BO_ 2650776967 PB_ROC_87: 16 NODE_87
 SG_ NegRelayCounterAbove500_FFA587 : 120|8@1+ (1,0) [0|255] ""  PCM
 SG_ PosRelayCounterAbove500_FFA587 : 112|8@1+ (1,0) [0|255] ""  PCM
 SG_ NegRelayCounter400_500_FFA587 : 104|8@1+ (1,0) [0|255] ""  PCM
 SG_ PosRelayCounter400_500_FFA587 : 96|8@1+ (1,0) [0|255] ""  PCM
 SG_ NegRelayCounter250_400_FFA587 : 88|8@1+ (1,0) [0|255] ""  PCM
 SG_ PosRelayCounter250_400_FFA587 : 80|8@1+ (1,0) [0|255] ""  PCM
 SG_ NegRelayCounter50_250_FFA587 : 64|16@1+ (1,0) [0|65535] ""  PCM
 SG_ PosRelayCounter50_250_FFA587 : 48|16@1+ (1,0) [0|65535] ""  PCM
 SG_ NegRelayCounter_FFA587 : 32|16@1+ (1,0) [0|65535] ""  PCM
 SG_ PosRelayCounter_FFA587 : 16|16@1+ (1,0) [0|65535] ""  PCM
 SG_ PreRelayCounter_FFA587 : 0|16@1+ (1,0) [0|65535] ""  PCM

BO_ 2650777076 PB_ROC_F4: 16 NODE_F4
 SG_ NegRelayCounterAbove500_FFA5F4 : 120|8@1+ (1,0) [0|255] ""  PCM
 SG_ PosRelayCounterAbove500_FFA5F4 : 112|8@1+ (1,0) [0|255] ""  PCM
 SG_ NegRelayCounter400_500_FFA5F4 : 104|8@1+ (1,0) [0|255] ""  PCM
 SG_ PosRelayCounter400_500_FFA5F4 : 96|8@1+ (1,0) [0|255] ""  PCM
 SG_ NegRelayCounter250_400_FFA5F4 : 88|8@1+ (1,0) [0|255] ""  PCM
 SG_ PosRelayCounter250_400_FFA5F4 : 80|8@1+ (1,0) [0|255] ""  PCM
 SG_ NegRelayCounter50_250_FFA5F4 : 64|16@1+ (1,0) [0|65535] ""  PCM
 SG_ PosRelayCounter50_250_FFA5F4 : 48|16@1+ (1,0) [0|65535] ""  PCM
 SG_ NegRelayCounter_FFA5F4 : 32|16@1+ (1,0) [0|65535] ""  PCM
 SG_ PosRelayCounter_FFA5F4 : 16|16@1+ (1,0) [0|65535] ""  PCM
 SG_ PreRelayCounter_FFA5F4 : 0|16@1+ (1,0) [0|65535] ""  PCM

BO_ 2650777077 PB_ROC_F5: 16 NODE_F5
 SG_ NegRelayCounterAbove500_FFA5F5 : 120|8@1+ (1,0) [0|255] ""  PCM
 SG_ PosRelayCounterAbove500_FFA5F5 : 112|8@1+ (1,0) [0|255] ""  PCM
 SG_ NegRelayCounter400_500_FFA5F5 : 104|8@1+ (1,0) [0|255] ""  PCM
 SG_ PosRelayCounter400_500_FFA5F5 : 96|8@1+ (1,0) [0|255] ""  PCM
 SG_ NegRelayCounter250_400_FFA5F5 : 88|8@1+ (1,0) [0|255] ""  PCM
 SG_ PosRelayCounter250_400_FFA5F5 : 80|8@1+ (1,0) [0|255] ""  PCM
 SG_ NegRelayCounter50_250_FFA5F5 : 64|16@1+ (1,0) [0|65535] ""  PCM
 SG_ PosRelayCounter50_250_FFA5F5 : 48|16@1+ (1,0) [0|65535] ""  PCM
 SG_ NegRelayCounter_FFA5F5 : 32|16@1+ (1,0) [0|65535] ""  PCM
 SG_ PosRelayCounter_FFA5F5 : 16|16@1+ (1,0) [0|65535] ""  PCM
 SG_ PreRelayCounter_FFA5F5 : 0|16@1+ (1,0) [0|65535] ""  PCM

BO_ 2650777078 PB_ROC_F6: 16 NODE_F6
 SG_ NegRelayCounterAbove500_FFA5F6 : 120|8@1+ (1,0) [0|255] ""  PCM
 SG_ PosRelayCounterAbove500_FFA5F6 : 112|8@1+ (1,0) [0|255] ""  PCM
 SG_ NegRelayCounter400_500_FFA5F6 : 104|8@1+ (1,0) [0|255] ""  PCM
 SG_ PosRelayCounter400_500_FFA5F6 : 96|8@1+ (1,0) [0|255] ""  PCM
 SG_ NegRelayCounter250_400_FFA5F6 : 88|8@1+ (1,0) [0|255] ""  PCM
 SG_ PosRelayCounter250_400_FFA5F6 : 80|8@1+ (1,0) [0|255] ""  PCM
 SG_ NegRelayCounter50_250_FFA5F6 : 64|16@1+ (1,0) [0|65535] ""  PCM
 SG_ PosRelayCounter50_250_FFA5F6 : 48|16@1+ (1,0) [0|65535] ""  PCM
 SG_ NegRelayCounter_FFA5F6 : 32|16@1+ (1,0) [0|65535] ""  PCM
 SG_ PosRelayCounter_FFA5F6 : 16|16@1+ (1,0) [0|65535] ""  PCM
 SG_ PreRelayCounter_FFA5F6 : 0|16@1+ (1,0) [0|65535] ""  PCM

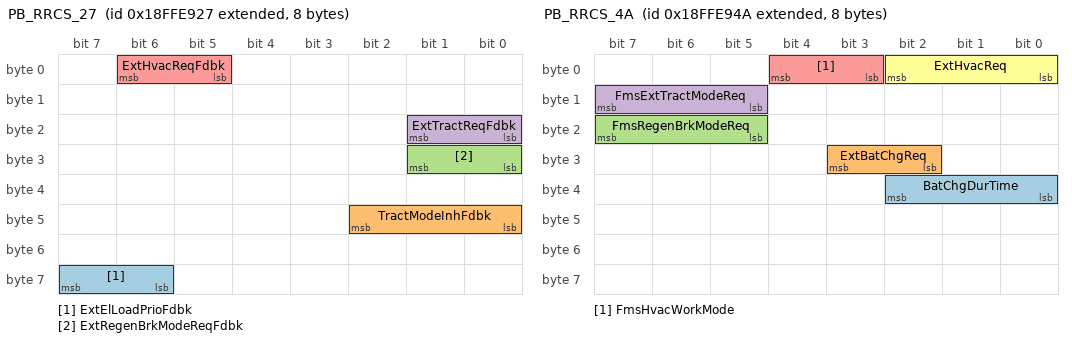
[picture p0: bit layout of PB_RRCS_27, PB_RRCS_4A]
BO_ 2566908199 PB_RRCS_27: 8 VCM
 SG_ ExtElLoadPrioFdbk : 62|2@1+ (1,0) [0|3] ""  PCM
 SG_ TractModeInhFdbk : 40|3@1+ (1,0) [0|7] ""  PCM
 SG_ ExtRegenBrkModeReqFdbk : 24|2@1+ (1,0) [0|3] ""  PCM
 SG_ ExtTractReqFdbk : 16|2@1+ (1,0) [0|3] ""  PCM
 SG_ ExtHvacReqFdbk : 5|2@1+ (1,0) [0|3] ""  PCM

BO_ 2566908234 PB_RRCS_4A: 8 PCM
 SG_ BatChgDurTime : 32|3@1+ (1,0) [0|7] "" Vector__XXX
 SG_ ExtBatChgReq : 26|2@1+ (1,0) [0|3] "" Vector__XXX
 SG_ FmsRegenBrkModeReq : 21|3@1+ (1,0) [0|7] "" Vector__XXX
 SG_ FmsExtTractModeReq : 13|3@1+ (1,0) [0|7] "" Vector__XXX
 SG_ FmsHvacWorkMode : 3|2@1+ (1,0) [0|3] "" Vector__XXX
 SG_ ExtHvacReq : 0|3@1+ (1,0) [0|7] "" Vector__XXX

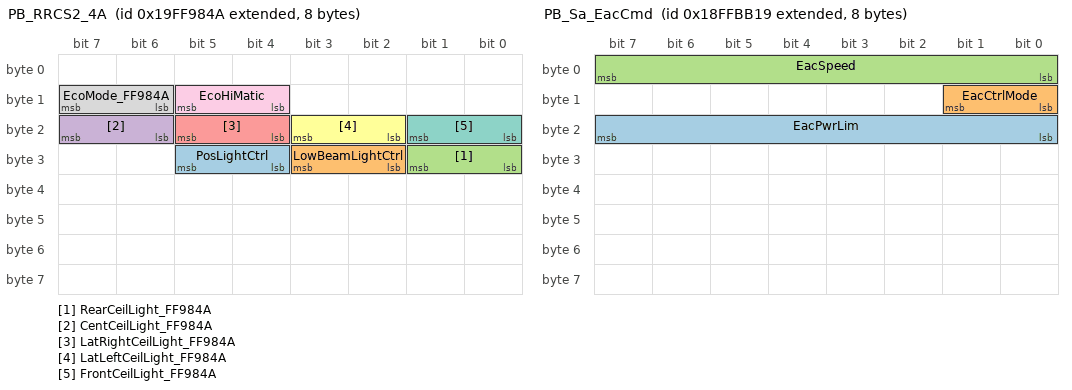
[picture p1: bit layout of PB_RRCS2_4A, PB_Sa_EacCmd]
BO_ 2583664714 PB_RRCS2_4A: 8 PCM
 SG_ PosLightCtrl : 28|2@1+ (1,0) [0|3] "" Vector__XXX
 SG_ LowBeamLightCtrl : 26|2@1+ (1,0) [0|3] "" Vector__XXX
 SG_ RearCeilLight_FF984A : 24|2@1+ (1,0) [0|3] "" Vector__XXX
 SG_ CentCeilLight_FF984A : 22|2@1+ (1,0) [0|3] "" Vector__XXX
 SG_ LatRightCeilLight_FF984A : 20|2@1+ (1,0) [0|3] "" Vector__XXX
 SG_ LatLeftCeilLight_FF984A : 18|2@1+ (1,0) [0|3] "" Vector__XXX
 SG_ FrontCeilLight_FF984A : 16|2@1+ (1,0) [0|3] "" Vector__XXX
 SG_ EcoMode_FF984A : 14|2@1+ (1,0) [0|3] "" Vector__XXX
 SG_ EcoHiMatic : 12|2@1+ (1,0) [0|3] "" Vector__XXX

BO_ 2566896409 PB_Sa_EacCmd: 8 ACM
 SG_ EacPwrLim : 16|8@1+ (0.04,0) [0|10] "kW"  PCM
 SG_ EacCtrlMode : 8|2@1+ (1,0) [0|3] ""  PCM
 SG_ EacSpeed : 0|8@1+ (50,0) [0|9000] "rpm"  PCM

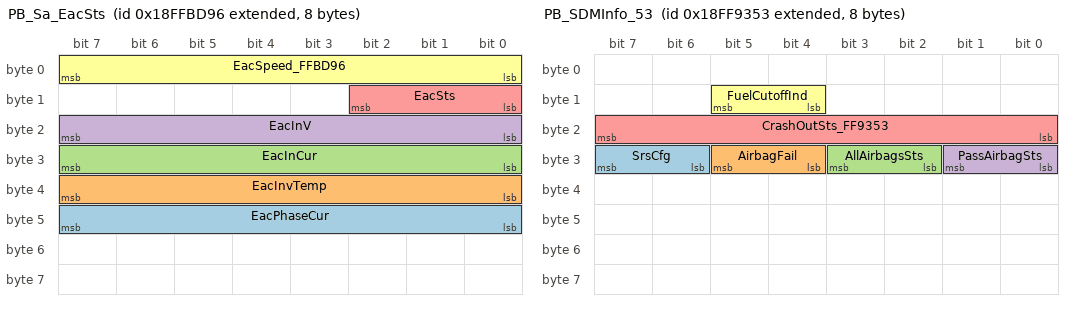
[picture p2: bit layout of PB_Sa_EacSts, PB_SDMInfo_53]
BO_ 2566897046 PB_Sa_EacSts: 8 NODE_96
 SG_ EacPhaseCur : 40|8@1+ (0.5,0) [0|125] "A"  PCM
 SG_ EacInvTemp : 32|8@1+ (1,-50) [-50|200] "�C"  PCM
 SG_ EacInCur : 24|8@1+ (0.5,0) [0|125] "A"  PCM
 SG_ EacInV : 16|8@1+ (3,0) [0|750] "V"  PCM
 SG_ EacSts : 8|3@1+ (1,0) [0|7] ""  PCM
 SG_ EacSpeed_FFBD96 : 0|8@1+ (50,0) [0|9000] "rpm"  PCM

BO_ 2566886218 PB_SDMInfo_4A: 8 PCM
 SG_ EcallSts : 32|3@1+ (1,0) [0|15] "" Vector__XXX

BO_ 2566886227 PB_SDMInfo_53: 8 Airbag
 SG_ SrsCfg : 30|2@1+ (1,0) [0|3] ""  PCM
 SG_ AirbagFail : 28|2@1+ (1,0) [0|3] ""  PCM
 SG_ AllAirbagsSts : 26|2@1+ (1,0) [0|3] ""  PCM
 SG_ PassAirbagSts : 24|2@1+ (1,0) [0|3] ""  PCM
 SG_ CrashOutSts_FF9353 : 16|8@1+ (1,0) [0|255] ""  PCM
 SG_ FuelCutoffInd : 12|2@1+ (1,0) [0|3] ""  PCM

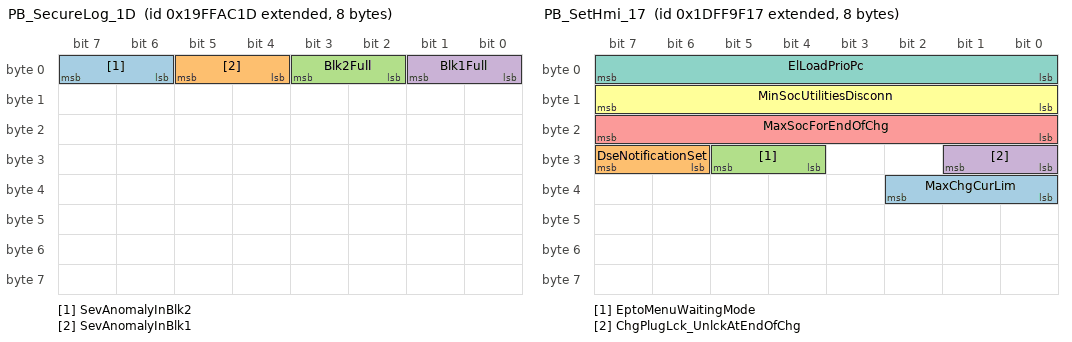
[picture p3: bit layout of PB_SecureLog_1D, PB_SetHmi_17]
BO_ 2583669789 PB_SecureLog_1D: 8 SGW
 SG_ SevAnomalyInBlk2 : 6|2@1+ (1,0) [0|3] ""  PCM
 SG_ SevAnomalyInBlk1 : 4|2@1+ (1,0) [0|3] ""  PCM
 SG_ Blk2Full : 2|2@1+ (1,0) [0|3] ""  PCM
 SG_ Blk1Full : 0|2@1+ (1,0) [0|3] ""  PCM

BO_ 2583669834 PB_SecureLog_4A: 8 PCM
 SG_ WarnRx : 8|2@1+ (1,0) [0|3] "" Vector__XXX

BO_ 2650775319 PB_SetHmi_17: 8 ICC
 SG_ MaxChgCurLim : 32|3@1+ (1,0) [0|7] ""  PCM
 SG_ DseNotificationSet : 30|2@1+ (1,0) [0|3] ""  PCM
 SG_ EptoMenuWaitingMode : 28|2@1+ (1,0) [0|3] ""  PCM
 SG_ ChgPlugLck_UnlckAtEndOfChg : 24|2@1+ (1,0) [0|3] ""  PCM
 SG_ MaxSocForEndOfChg : 16|8@1+ (0.4,0) [0|100] "%"  PCM
 SG_ MinSocUtilitiesDisconn : 8|8@1+ (0.4,0) [0|100] "%"  PCM
 SG_ ElLoadPrioPc : 0|8@1+ (0.5,0) [0|125] "%"  PCM

BO_ 2650775335 PB_SetHmi_27: 8 VCM
 SG_ ElLoadPrioPc_FF9F27 : 0|8@1+ (0.5,0) [0|125] "%"  PCM

BO_ 2650775370 PB_SetHmi_4A: 8 PCM
 SG_ ZZS_24_1DFF9F4A : 24|2@1+ (1,0) [0|3] "" Vector__XXX
 SG_ ElLoadPrioPc_FF9F4A : 0|8@1+ (0.5,0) [0|125] "%" Vector__XXX

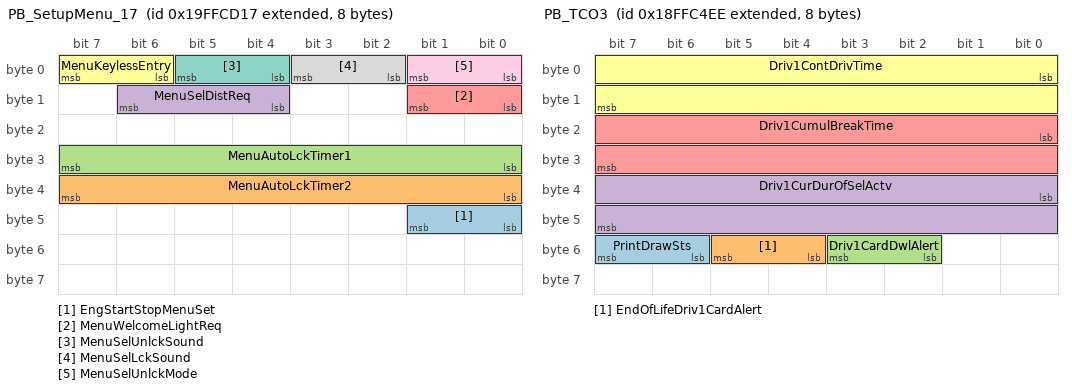
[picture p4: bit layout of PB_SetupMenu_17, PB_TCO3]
BO_ 2583678231 PB_SetupMenu_17: 8 ICC
 SG_ EngStartStopMenuSet : 40|2@1+ (1,0) [0|3] ""  PCM
 SG_ MenuAutoLckTimer2 : 32|8@1+ (1,0) [0|250] "s"  PCM
 SG_ MenuAutoLckTimer1 : 24|8@1+ (1,0) [0|250] "s"  PCM
 SG_ MenuSelDistReq : 12|3@1+ (1,0) [0|7] ""  PCM
 SG_ MenuWelcomeLightReq : 8|2@1+ (1,0) [0|3] ""  PCM
 SG_ MenuKeylessEntry : 6|2@1+ (1,0) [0|3] ""  PCM
 SG_ MenuSelUnlckSound : 4|2@1+ (1,0) [0|3] ""  PCM
 SG_ MenuSelLckSound : 2|2@1+ (1,0) [0|3] ""  PCM
 SG_ MenuSelUnlckMode : 0|2@1+ (1,0) [0|3] ""  PCM

BO_ 2583678241 PB_SetupMenu_21: 8 BCM
 SG_ IgnShutdnTimer : 16|8@1+ (1,0) [0|250] "min"  PCM

BO_ 2650777734 PB_STC_86: 24 NODE_86
 SG_ MaxIntervalViolation : 176|16@1+ (1,0) [0|65535] ""  PCM
 SG_ StgBelowNeg30_h : 160|16@1+ (1,0) [0|65535] "h"  PCM
 SG_ StgBelowNeg20_h : 144|16@1+ (1,0) [0|65535] "h"  PCM
 SG_ StgBelowNeg10_h : 128|16@1+ (1,0) [0|65535] "h"  PCM
 SG_ StgBelow0_h : 112|16@1+ (1,0) [0|65535] "h"  PCM
 SG_ StgOver0_h : 96|16@1+ (1,0) [0|65535] "h"  PCM
 SG_ StgOver15_h : 80|16@1+ (1,0) [0|65535] "h"  PCM
 SG_ StgOver30_h : 64|16@1+ (1,0) [0|65535] "h"  PCM
 SG_ StgOver35_h : 48|16@1+ (1,0) [0|65535] "h"  PCM
 SG_ StgOver40_h : 32|16@1+ (1,0) [0|65535] "h"  PCM
 SG_ StgOver45_h : 16|16@1+ (1,0) [0|65535] "h"  PCM
 SG_ StgOver55_h : 0|16@1+ (1,0) [0|65535] "h"  PCM

BO_ 2650777735 PB_STC_87: 24 NODE_87
 SG_ MaxIntervalViolation_FFA887 : 176|16@1+ (1,0) [0|65535] ""  PCM
 SG_ StgBelowNeg30_h_FFA887 : 160|16@1+ (1,0) [0|65535] "h"  PCM
 SG_ StgBelowNeg20_h_FFA887 : 144|16@1+ (1,0) [0|65535] "h"  PCM
 SG_ StgBelowNeg10_h_FFA887 : 128|16@1+ (1,0) [0|65535] "h"  PCM
 SG_ StgBelow0_h_FFA887 : 112|16@1+ (1,0) [0|65535] "h"  PCM
 SG_ StgOver0_h_FFA887 : 96|16@1+ (1,0) [0|65535] "h"  PCM
 SG_ StgOver15_h_FFA887 : 80|16@1+ (1,0) [0|65535] "h"  PCM
 SG_ StgOver30_h_FFA887 : 64|16@1+ (1,0) [0|65535] "h"  PCM
 SG_ StgOver35_h_FFA887 : 48|16@1+ (1,0) [0|65535] "h"  PCM
 SG_ StgOver40_h_FFA887 : 32|16@1+ (1,0) [0|65535] "h"  PCM
 SG_ StgOver45_h_FFA887 : 16|16@1+ (1,0) [0|65535] "h"  PCM
 SG_ StgOver55_h_FFA887 : 0|16@1+ (1,0) [0|65535] "h"  PCM

BO_ 2650777844 PB_STC_F4: 24 NODE_F4
 SG_ MaxIntervalViolation_FFA8F4 : 176|16@1+ (1,0) [0|65535] ""  PCM
 SG_ StgBelowNeg30_h_FFA8F4 : 160|16@1+ (1,0) [0|65535] "h"  PCM
 SG_ StgBelowNeg20_h_FFA8F4 : 144|16@1+ (1,0) [0|65535] "h"  PCM
 SG_ StgBelowNeg10_h_FFA8F4 : 128|16@1+ (1,0) [0|65535] "h"  PCM
 SG_ StgBelow0_h_FFA8F4 : 112|16@1+ (1,0) [0|65535] "h"  PCM
 SG_ StgOver0_h_FFA8F4 : 96|16@1+ (1,0) [0|65535] "h"  PCM
 SG_ StgOver15_h_FFA8F4 : 80|16@1+ (1,0) [0|65535] "h"  PCM
 SG_ StgOver30_h_FFA8F4 : 64|16@1+ (1,0) [0|65535] "h"  PCM
 SG_ StgOver35_h_FFA8F4 : 48|16@1+ (1,0) [0|65535] "h"  PCM
 SG_ StgOver40_h_FFA8F4 : 32|16@1+ (1,0) [0|65535] "h"  PCM
 SG_ StgOver45_h_FFA8F4 : 16|16@1+ (1,0) [0|65535] "h"  PCM
 SG_ StgOver55_h_FFA8F4 : 0|16@1+ (1,0) [0|65535] "h"  PCM

BO_ 2650777845 PB_STC_F5: 24 NODE_F5
 SG_ MaxIntervalViolation_FFA8F5 : 176|16@1+ (1,0) [0|65535] ""  PCM
 SG_ StgBelowNeg30_h_FFA8F5 : 160|16@1+ (1,0) [0|65535] "h"  PCM
 SG_ StgBelowNeg20_h_FFA8F5 : 144|16@1+ (1,0) [0|65535] "h"  PCM
 SG_ StgBelowNeg10_h_FFA8F5 : 128|16@1+ (1,0) [0|65535] "h"  PCM
 SG_ StgBelow0_h_FFA8F5 : 112|16@1+ (1,0) [0|65535] "h"  PCM
 SG_ StgOver0_h_FFA8F5 : 96|16@1+ (1,0) [0|65535] "h"  PCM
 SG_ StgOver15_h_FFA8F5 : 80|16@1+ (1,0) [0|65535] "h"  PCM
 SG_ StgOver30_h_FFA8F5 : 64|16@1+ (1,0) [0|65535] "h"  PCM
 SG_ StgOver35_h_FFA8F5 : 48|16@1+ (1,0) [0|65535] "h"  PCM
 SG_ StgOver40_h_FFA8F5 : 32|16@1+ (1,0) [0|65535] "h"  PCM
 SG_ StgOver45_h_FFA8F5 : 16|16@1+ (1,0) [0|65535] "h"  PCM
 SG_ StgOver55_h_FFA8F5 : 0|16@1+ (1,0) [0|65535] "h"  PCM

BO_ 2650777846 PB_STC_F6: 24 NODE_F6
 SG_ MaxIntervalViolation_FFA8F6 : 176|16@1+ (1,0) [0|65535] ""  PCM
 SG_ StgBelowNeg30_h_FFA8F6 : 160|16@1+ (1,0) [0|65535] "h"  PCM
 SG_ StgBelowNeg20_h_FFA8F6 : 144|16@1+ (1,0) [0|65535] "h"  PCM
 SG_ StgBelowNeg10_h_FFA8F6 : 128|16@1+ (1,0) [0|65535] "h"  PCM
 SG_ StgBelow0_h_FFA8F6 : 112|16@1+ (1,0) [0|65535] "h"  PCM
 SG_ StgOver0_h_FFA8F6 : 96|16@1+ (1,0) [0|65535] "h"  PCM
 SG_ StgOver15_h_FFA8F6 : 80|16@1+ (1,0) [0|65535] "h"  PCM
 SG_ StgOver30_h_FFA8F6 : 64|16@1+ (1,0) [0|65535] "h"  PCM
 SG_ StgOver35_h_FFA8F6 : 48|16@1+ (1,0) [0|65535] "h"  PCM
 SG_ StgOver40_h_FFA8F6 : 32|16@1+ (1,0) [0|65535] "h"  PCM
 SG_ StgOver45_h_FFA8F6 : 16|16@1+ (1,0) [0|65535] "h"  PCM
 SG_ StgOver55_h_FFA8F6 : 0|16@1+ (1,0) [0|65535] "h"  PCM

BO_ 2583654525 PB_TBoxInfo_7D: 8 Tbox
 SG_ TboxSts : 0|2@1+ (1,0) [0|3] ""  PCM

BO_ 2566898670 PB_TCO2: 21 DTCO
 SG_ WFact : 152|16@1+ (0.001,0) [2.4|25] "pulse/m"  PCM
 SG_ NextCalDateYr : 144|8@1+ (1,1985) [1985|2235] "year"  PCM
 SG_ NextCalDateMonth : 136|8@1+ (1,0) [1|12] "month"  PCM
 SG_ NextCalDateDay : 128|8@1+ (0.25,0) [0.25|31.75] "day"  PCM
 SG_ PrefLang : 112|16@1+ (1,0) [0|255] "ASCII"  PCM
 SG_ Driv1Id_FFC3EE : 0|8@1+ (1,0) [0|255] "ASCII"  PCM

BO_ 2566898926 PB_TCO3: 8 DTCO
 SG_ PrintDrawSts : 54|2@1+ (1,0) [0|3] ""  PCM
 SG_ EndOfLifeDriv1CardAlert : 52|2@1+ (1,0) [0|3] ""  PCM
 SG_ Driv1CardDwlAlert : 50|2@1+ (1,0) [0|3] ""  PCM
 SG_ Driv1CurDurOfSelActv : 32|16@1+ (1,0) [0|64255] "min"  PCM
 SG_ Driv1CumulBreakTime : 16|16@1+ (1,0) [0|64255] "min"  PCM
 SG_ Driv1ContDrivTime : 0|16@1+ (1,0) [0|64255] "min"  PCM

BO_ 2566899694 PB_TCO4: 44 DTCO
 SG_ AvCnt : 336|16@1+ (1,0) [0|64255] "min"  PCM
 SG_ WorkCnt : 320|16@1+ (1,0) [0|64255] "min"  PCM
 SG_ DrivCnt : 304|16@1+ (1,0) [0|64255] "min"  PCM
 SG_ TwoWeeksTotOdo : 288|16@1+ (1,0) [0|64255] "km"  PCM
 SG_ WeekTotOdo : 272|16@1+ (1,0) [0|64255] "km"  PCM
 SG_ DayOdo : 256|16@1+ (1,0) [0|64255] "km"  PCM
 SG_ DayRestPer7Flag : 255|1@1+ (1,0) [0|1] ""  PCM
 SG_ DayRestPer7 : 240|15@1+ (1,0) [0|31487] "min"  PCM
 SG_ DayRestPer6Flag : 239|1@1+ (1,0) [0|1] ""  PCM
 SG_ DayRestPer6 : 224|15@1+ (1,0) [0|31487] "min"  PCM
 SG_ DayRestPer5Flag : 223|1@1+ (1,0) [0|1] ""  PCM
 SG_ DayRestPer5 : 208|15@1+ (1,0) [0|31487] "min"  PCM
 SG_ DayRestPer4Flag : 207|1@1+ (1,0) [0|1] ""  PCM
 SG_ DayRestPer4 : 192|15@1+ (1,0) [0|31487] "min"  PCM
 SG_ DayRestPer3Flag : 191|1@1+ (1,0) [0|1] ""  PCM
 SG_ DayRestPer3 : 176|15@1+ (1,0) [0|31487] "min"  PCM
 SG_ DayRestPer2Flag : 175|1@1+ (1,0) [0|1] ""  PCM
 SG_ DayRestPer2 : 160|15@1+ (1,0) [0|31487] "min"  PCM
 SG_ DayRestPer1Flag : 159|1@1+ (1,0) [0|1] ""  PCM
 SG_ DayRestPer1 : 144|15@1+ (1,0) [0|31487] "min"  PCM
 SG_ DayDrivTimeShift6Flag : 143|1@1+ (1,0) [0|1] ""  PCM
 SG_ DayDrivTimeShift6 : 128|15@1+ (1,0) [0|31487] "min"  PCM
 SG_ DayDrivTimeShift5Flag : 127|1@1+ (1,0) [0|1] ""  PCM
 SG_ DayDrivTimeShift5 : 112|15@1+ (1,0) [0|31487] "min"  PCM
 SG_ DayDrivTimeShift4Flag : 111|1@1+ (1,0) [0|1] ""  PCM
 SG_ DayDrivTimeShift4 : 96|15@1+ (1,0) [0|31487] "min"  PCM
 SG_ DayDrivTimeShift3Flag : 95|1@1+ (1,0) [0|1] ""  PCM
 SG_ DayDrivTimeShift3 : 80|15@1+ (1,0) [0|31487] "min"  PCM
 SG_ DayDrivTimeShift2Flag : 79|1@1+ (1,0) [0|1] ""  PCM
 SG_ DayDrivTimeShift2 : 64|15@1+ (1,0) [0|31487] "min"  PCM
 SG_ DayDrivTimeShift1Flag : 63|1@1+ (1,0) [0|1] ""  PCM
 SG_ DayDrivTimeShift1 : 48|15@1+ (1,0) [0|31487] "min"  PCM
 SG_ DayDrivTimeFlag : 47|1@1+ (1,0) [0|1] ""  PCM
 SG_ DayDrivTime : 32|15@1+ (1,0) [0|31487] "min"  PCM
 SG_ WeekTotDrivTime : 16|16@1+ (1,0) [0|64255] "min"  PCM
 SG_ TwoWeeksTotDrivTime : 0|16@1+ (1,0) [0|64255] "min"  PCM

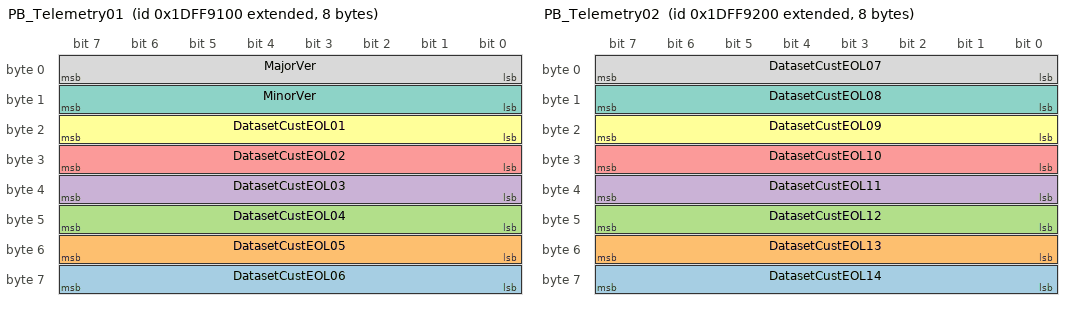
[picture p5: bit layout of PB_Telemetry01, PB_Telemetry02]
BO_ 2650771712 PB_Telemetry01: 8 ECM
 SG_ DatasetCustEOL06 : 56|8@1+ (1,0) [0|255] ""  PCM
 SG_ DatasetCustEOL05 : 48|8@1+ (1,0) [0|255] ""  PCM
 SG_ DatasetCustEOL04 : 40|8@1+ (1,0) [0|255] ""  PCM
 SG_ DatasetCustEOL03 : 32|8@1+ (1,0) [0|255] ""  PCM
 SG_ DatasetCustEOL02 : 24|8@1+ (1,0) [0|255] ""  PCM
 SG_ DatasetCustEOL01 : 16|8@1+ (1,0) [0|255] ""  PCM
 SG_ MinorVer : 8|8@1+ (1,0) [0|255] ""  PCM
 SG_ MajorVer : 0|8@1+ (1,0) [0|255] ""  PCM

BO_ 2650771968 PB_Telemetry02: 8 ECM
 SG_ DatasetCustEOL14 : 56|8@1+ (1,0) [0|255] ""  PCM
 SG_ DatasetCustEOL13 : 48|8@1+ (1,0) [0|255] ""  PCM
 SG_ DatasetCustEOL12 : 40|8@1+ (1,0) [0|255] ""  PCM
 SG_ DatasetCustEOL11 : 32|8@1+ (1,0) [0|255] ""  PCM
 SG_ DatasetCustEOL10 : 24|8@1+ (1,0) [0|255] ""  PCM
 SG_ DatasetCustEOL09 : 16|8@1+ (1,0) [0|255] ""  PCM
 SG_ DatasetCustEOL08 : 8|8@1+ (1,0) [0|255] ""  PCM
 SG_ DatasetCustEOL07 : 0|8@1+ (1,0) [0|255] ""  PCM

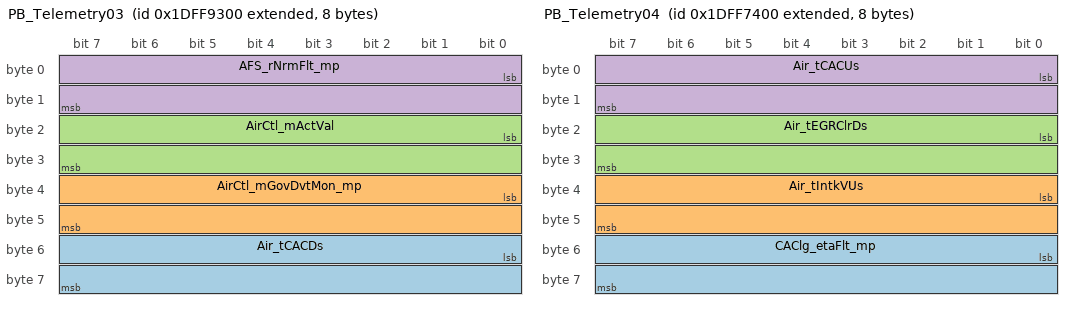
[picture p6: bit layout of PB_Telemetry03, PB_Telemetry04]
BO_ 2650772224 PB_Telemetry03: 8 ECM
 SG_ Air_tCACDs : 48|16@1- (0.1,-273.14) [-3549.94|3003.56] "�C"  PCM
 SG_ AirCtl_mGovDvtMon_mp : 32|16@1- (0.1,0) [-3276.8|3276.7] "mg/Hub"  PCM
 SG_ AirCtl_mActVal : 16|16@1- (0.1,0) [-3276.8|3276.7] "mg/Hub"  PCM
 SG_ AFS_rNrmFlt_mp : 0|16@1- (0.0001220703125,0) [-4|3.9998779296875] ""  PCM

BO_ 2650764288 PB_Telemetry04: 8 ECM
 SG_ CAClg_etaFlt_mp : 48|16@1- (0.0001220703125,0) [-4|3.9998779296875] "-"  PCM
 SG_ Air_tIntkVUs : 32|16@1- (0.1,-273.14) [-3549.94|3003.56] "�C"  PCM
 SG_ Air_tEGRClrDs : 16|16@1- (0.1,-273.14) [-3549.94|3003.56] "�C"  PCM
 SG_ Air_tCACUs : 0|16@1- (0.1,-273.14) [-3549.94|3003.56] "�C"  PCM

BO_ 2650764544 PB_Telemetry05: 8 ECM
 SG_ DStgyEffMon_mNOxDsMon2_mp : 32|32@1- (0.001,0) [-2147483.648|2147483.647] "mg"  PCM
 SG_ CoEOM_stOpModeAct : 0|32@1+ (1,0) [0|4294967295] "-"  PCM

BO_ 2650764800 PB_Telemetry06: 8 ECM
 SG_ DStgyEffMon_mNOxUsMon2_mp : 32|32@1- (0.001,0) [-2147483.648|2147483.647] "mg"  PCM
 SG_ DStgyEffMon_mNOxDsMon4_mp : 0|32@1- (0.001,0) [-2147483.648|2147483.647] "mg"  PCM

BO_ 2650765056 PB_Telemetry07: 8 ECM
 SG_ DStgySys2_cNH3CalcCell1 : 32|32@1- (1E-006,0) [-2147.483648|2147.483647] ""  PCM
 SG_ DStgyEffMon_mNOxUsMon4_mp : 0|32@1- (0.001,0) [-2147483.648|2147483.647] "mg"  PCM

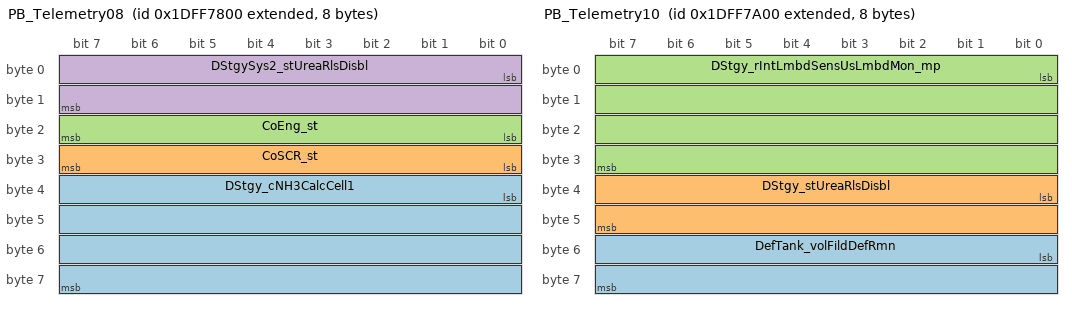
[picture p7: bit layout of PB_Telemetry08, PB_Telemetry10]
BO_ 2650765312 PB_Telemetry08: 8 ECM
 SG_ DStgy_cNH3CalcCell1 : 32|32@1- (1E-006,0) [-2147.483648|2147.483647] ""  PCM
 SG_ CoSCR_st : 24|8@1+ (1,0) [0|255] "-"  PCM
 SG_ CoEng_st : 16|8@1+ (1,0) [0|255] "-"  PCM
 SG_ DStgySys2_stUreaRlsDisbl : 0|16@1+ (1,0) [0|65535] "-"  PCM

BO_ 2650765568 PB_Telemetry09: 8 ECM
 SG_ DStgy_rIntLmbdSensMsLmbdMon_mp : 32|32@1- (0.001,0) [-2147483.648|2147483.647] "-"  PCM
 SG_ DStgy_rIntLmbdSensDsLmbdMon_mp : 0|32@1- (0.001,0) [-2147483.648|2147483.647] "-"  PCM

BO_ 2650765824 PB_Telemetry10: 8 ECM
 SG_ DefTank_volFildDefRmn : 48|16@1+ (0.001,0) [0|65.535] "L"  PCM
 SG_ DStgy_stUreaRlsDisbl : 32|16@1+ (1,0) [0|65.535] "-"  PCM
 SG_ DStgy_rIntLmbdSensUsLmbdMon_mp : 0|32@1- (0.001,0) [-2147483.648|2147483.647] "-"  PCM

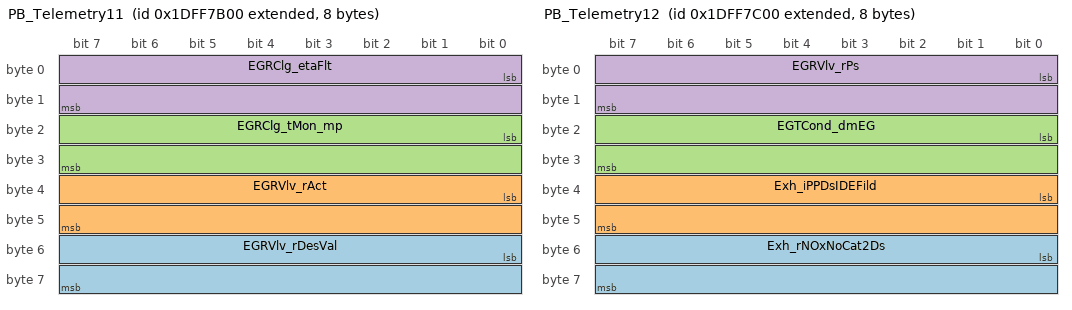
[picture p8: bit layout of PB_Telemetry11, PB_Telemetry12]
BO_ 2650766080 PB_Telemetry11: 8 ECM
 SG_ EGRVlv_rDesVal : 48|16@1- (0.01220703125,0) [-400|399.98779296875] "%"  PCM
 SG_ EGRVlv_rAct : 32|16@1- (0.01220703125,0) [-400|399.98779296875] "%"  PCM
 SG_ EGRClg_tMon_mp : 16|16@1- (0.1,-273.14) [-3549.94|3003.56] "�C"  PCM
 SG_ EGRClg_etaFlt : 0|16@1- (0.0001220703125,0) [-4|3.9998779296875] "-"  PCM

BO_ 2650766336 PB_Telemetry12: 8 ECM
 SG_ Exh_rNOxNoCat2Ds : 48|16@1- (1,0) [-32768|32767] "ppm"  PCM
 SG_ Exh_iPPDsIDEFild : 32|16@1- (0.00390625,0) [-128|127.99609375] "uA"  PCM
 SG_ EGTCond_dmEG : 16|16@1- (0.1,0) [-3276.8|3276.7] "Kg/h"  PCM
 SG_ EGRVlv_rPs : 0|16@1- (0.01,0) [-327.68|327.67] "%"  PCM

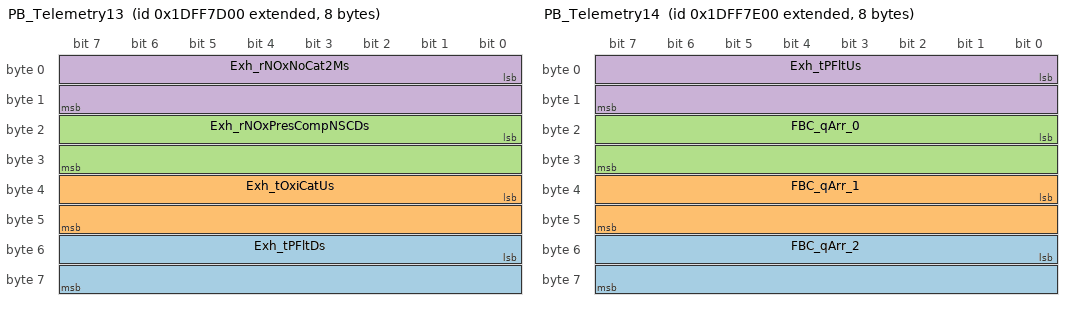
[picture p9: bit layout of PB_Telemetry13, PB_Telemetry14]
BO_ 2650766592 PB_Telemetry13: 8 ECM
 SG_ Exh_tPFltDs : 48|16@1- (0.1,-273.14) [-3549.94|3003.56] "�C"  PCM
 SG_ Exh_tOxiCatUs : 32|16@1- (0.1,-273.14) [-3549.94|3003.56] "�C"  PCM
 SG_ Exh_rNOxPresCompNSCDs : 16|16@1- (1,0) [-32768|32767] "ppm"  PCM
 SG_ Exh_rNOxNoCat2Ms : 0|16@1- (1,0) [-32768|32767] "ppm"  PCM

BO_ 2650766848 PB_Telemetry14: 8 ECM
 SG_ FBC_qArr_2 : 48|16@1- (0.01,0) [-327.68|327.67] "mg/hub"  PCM
 SG_ FBC_qArr_1 : 32|16@1- (0.01,0) [-327.68|327.67] "mg/hub"  PCM
 SG_ FBC_qArr_0 : 16|16@1- (0.01,0) [-327.68|327.67] "mg/hub"  PCM
 SG_ Exh_tPFltUs : 0|16@1- (0.1,-273.14) [-3549.94|3003.56] "�C"  PCM

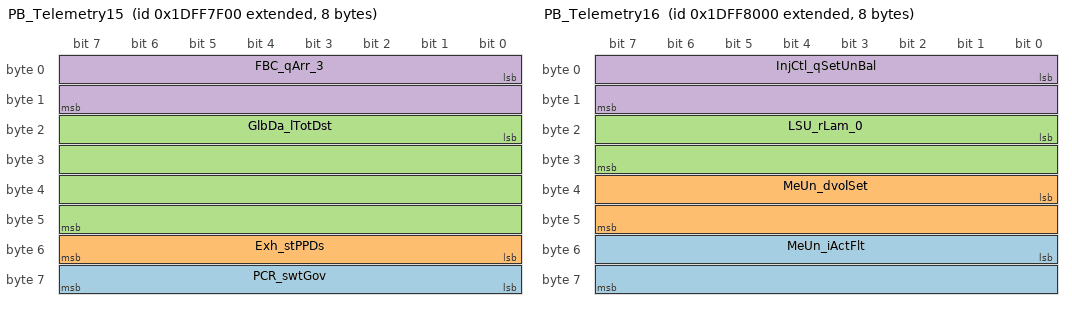
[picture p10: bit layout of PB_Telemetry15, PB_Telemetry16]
BO_ 2650767104 PB_Telemetry15: 8 ECM
 SG_ PCR_swtGov : 56|8@1+ (1,0) [0|255] "-"  PCM
 SG_ Exh_stPPDs : 48|8@1+ (1,0) [0|255] "-"  PCM
 SG_ GlbDa_lTotDst : 16|32@1- (1,0) [-2147483648|2147483647] "m"  PCM
 SG_ FBC_qArr_3 : 0|16@1- (0.01,0) [-327.68|327.67] "mg/hub"  PCM

BO_ 2650767360 PB_Telemetry16: 8 ECM
 SG_ MeUn_iActFlt : 48|16@1- (1,0) [-32768|32767] "mA"  PCM
 SG_ MeUn_dvolSet : 32|16@1- (10,0) [-327680|327670] "mm3/s"  PCM
 SG_ LSU_rLam_0 : 16|16@1- (0.001,0) [-32.768|32.767] "-"  PCM
 SG_ InjCtl_qSetUnBal : 0|16@1- (0.01,0) [-327.68|327.67] "mg/hub"  PCM

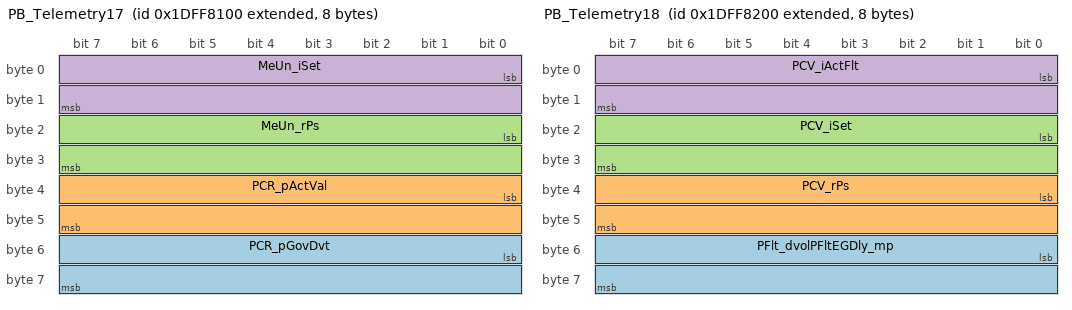
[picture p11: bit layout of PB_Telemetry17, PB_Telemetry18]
BO_ 2650767616 PB_Telemetry17: 8 ECM
 SG_ PCR_pGovDvt : 48|16@1- (1,0) [-32768|32767] "hPa"  PCM
 SG_ PCR_pActVal : 32|16@1- (1,0) [-32768|32767] "hPa"  PCM
 SG_ MeUn_rPs : 16|16@1- (0.01,0) [-327.68|327.67] "%"  PCM
 SG_ MeUn_iSet : 0|16@1- (1,0) [-32768|32767] "mA"  PCM

BO_ 2650767872 PB_Telemetry18: 8 ECM
 SG_ PFlt_dvolPFltEGDly_mp : 48|16@1- (0.1,0) [-3276.8|3276.7] "m^3/h"  PCM
 SG_ PCV_rPs : 32|16@1- (0.01,0) [-327.68|327.67] "%"  PCM
 SG_ PCV_iSet : 16|16@1- (1,0) [-32768|32767] "mA"  PCM
 SG_ PCV_iActFlt : 0|16@1- (1,0) [-32768|32767] "mA"  PCM

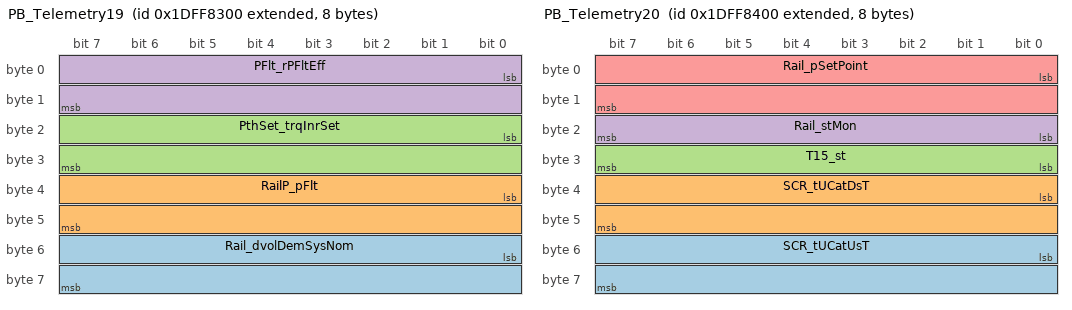
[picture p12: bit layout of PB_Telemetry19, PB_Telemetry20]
BO_ 2650768128 PB_Telemetry19: 8 ECM
 SG_ Rail_dvolDemSysNom : 48|16@1- (10,0) [-327680|327670] "mm3/s"  PCM
 SG_ RailP_pFlt : 32|16@1- (100,0) [-3276800|3276700] "hPa"  PCM
 SG_ PthSet_trqInrSet : 16|16@1- (0.1,0) [-3276.8|3276.7] "Nm"  PCM
 SG_ PFlt_rPFltEff : 0|16@1- (0.001,0) [-32.768|32.767] "-"  PCM

BO_ 2650768384 PB_Telemetry20: 8 ECM
 SG_ SCR_tUCatUsT : 48|16@1- (0.1,-273.14) [-3549.94|3003.56] "�C"  PCM
 SG_ SCR_tUCatDsT : 32|16@1- (0.1,-273.14) [-3549.94|3003.56] "�C"  PCM
 SG_ T15_st : 24|8@1+ (1,0) [0|255] "-"  PCM
 SG_ Rail_stMon : 16|8@1+ (1,0) [0|255] "-"  PCM
 SG_ Rail_pSetPoint : 0|16@1- (100,0) [-3276800|3276700] "hPa"  PCM

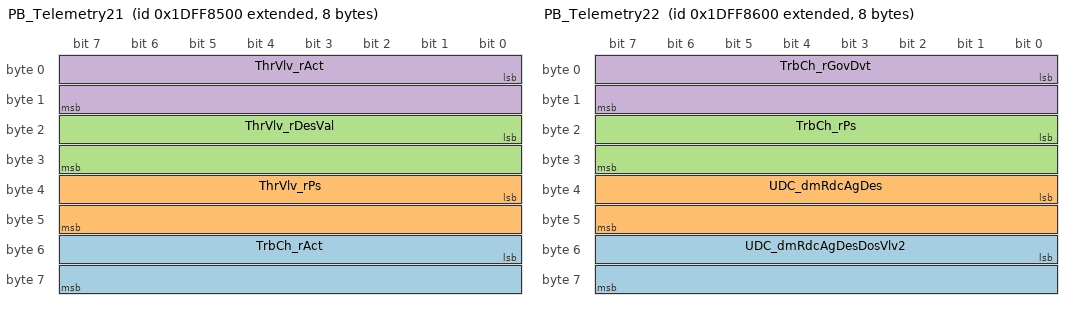
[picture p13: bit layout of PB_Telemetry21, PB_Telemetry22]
BO_ 2650768640 PB_Telemetry21: 8 ECM
 SG_ TrbCh_rAct : 48|16@1- (0.01220703125,0) [-400|399.98779296875] "%"  PCM
 SG_ ThrVlv_rPs : 32|16@1- (0.01,0) [-327.68|327.67] "%"  PCM
 SG_ ThrVlv_rDesVal : 16|16@1- (0.01220703125,0) [-400|399.98779296875] "%"  PCM
 SG_ ThrVlv_rAct : 0|16@1- (0.01220703125,0) [-400|399.98779296875] "%"  PCM

BO_ 2650768896 PB_Telemetry22: 8 ECM
 SG_ UDC_dmRdcAgDesDosVlv2 : 48|16@1- (0.1,0) [-3276.8|3276.7] "mg/s"  PCM
 SG_ UDC_dmRdcAgDes : 32|16@1- (0.1,0) [-3276.8|3276.7] "mg/s"  PCM
 SG_ TrbCh_rPs : 16|16@1- (0.01,0) [-327.68|327.67] "%"  PCM
 SG_ TrbCh_rGovDvt : 0|16@1- (0.01220703125,0) [-400|399.98779296875] "%"  PCM

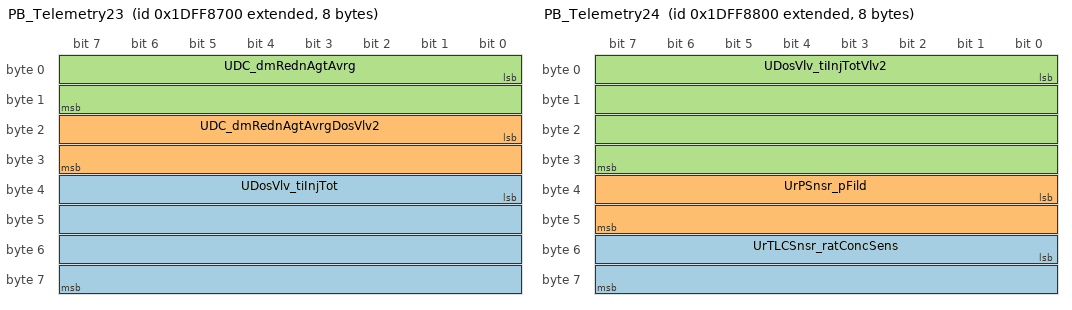
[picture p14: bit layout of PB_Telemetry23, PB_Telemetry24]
BO_ 2650769152 PB_Telemetry23: 8 ECM
 SG_ UDosVlv_tiInjTot : 32|32@1- (0.01,0) [-21474836.48|21474836.47] "ms"  PCM
 SG_ UDC_dmRednAgtAvrgDosVlv2 : 16|16@1- (0.1,0) [-3276.8|3276.7] "mg/s"  PCM
 SG_ UDC_dmRednAgtAvrg : 0|16@1- (0.1,0) [-3276.8|3276.7] "mg/s"  PCM

BO_ 2650769408 PB_Telemetry24: 8 ECM
 SG_ UrTLCSnsr_ratConcSens : 48|16@1- (0.01,0) [-327.68|327.67] "%"  PCM
 SG_ UrPSnsr_pFild : 32|16@1- (1,0) [-32768|32767] "hPa"  PCM
 SG_ UDosVlv_tiInjTotVlv2 : 0|32@1- (0.01,0) [-21474836.48|21474836.47] "ms"  PCM

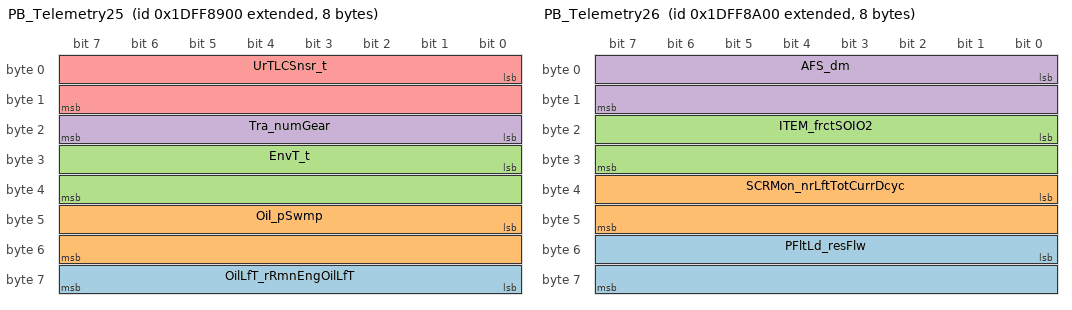
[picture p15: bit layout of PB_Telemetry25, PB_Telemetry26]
BO_ 2650769664 PB_Telemetry25: 8 ECM
 SG_ OilLfT_rRmnEngOilLfT : 56|8@1+ (1,0) [0|255] "%"  PCM
 SG_ Oil_pSwmp : 40|16@1- (1,0) [-32768|32767] "hPa"  PCM
 SG_ EnvT_t : 24|16@1- (0.1,-273.14) [-3549.94|3003.56] "�C"  PCM
 SG_ Tra_numGear : 16|8@1- (1,0) [-128|127] "-"  PCM
 SG_ UrTLCSnsr_t : 0|16@1- (0.1,-273.14) [-3549.94|3003.56] "�C"  PCM

BO_ 2650769920 PB_Telemetry26: 8 ECM
 SG_ PFltLd_resFlw : 48|16@1- (0.0001,0) [-3.2768|3.2767] "hPa/(m^3/h)"  PCM
 SG_ SCRMon_nrLftTotCurrDcyc : 32|16@1+ (1,0) [0|65535] "-"  PCM
 SG_ ITEM_frctSOIO2 : 16|16@1- (0.01,0) [-327.68|327.67] "-"  PCM
 SG_ AFS_dm : 0|16@1- (0.1,0) [-3276.8|3276.7] "Kg/h"  PCM

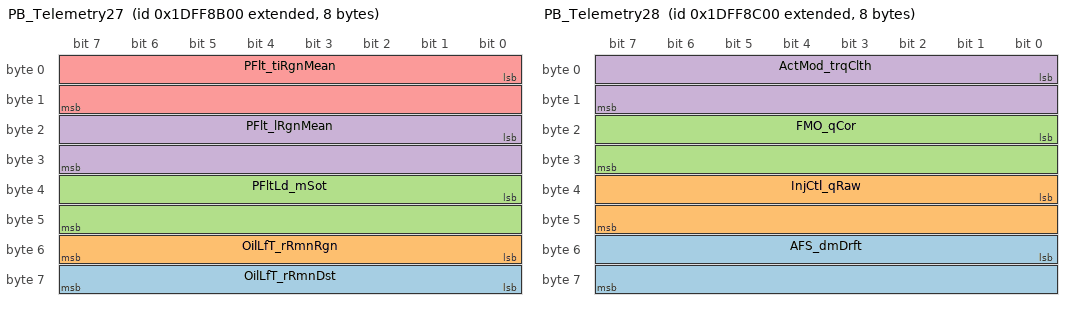
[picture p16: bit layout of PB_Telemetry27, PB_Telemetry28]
BO_ 2650770176 PB_Telemetry27: 8 ECM
 SG_ OilLfT_rRmnDst : 56|8@1+ (1,0) [0|255] "%"  PCM
 SG_ OilLfT_rRmnRgn : 48|8@1+ (1,0) [0|255] "%"  PCM
 SG_ PFltLd_mSot : 32|16@1- (0.01,0) [-327.68|327.67] "g"  PCM
 SG_ PFlt_lRgnMean : 16|16@1- (1,0) [-32768|32767] "km"  PCM
 SG_ PFlt_tiRgnMean : 0|16@1- (1,0) [-32768|32767] "s"  PCM

BO_ 2650770432 PB_Telemetry28: 8 ECM
 SG_ AFS_dmDrft : 48|16@1- (0.1,0) [-3276.8|3276.7] "kg/h"  PCM
 SG_ InjCtl_qRaw : 32|16@1- (0.01,0) [-327.68|327.67] "mg/hub"  PCM
 SG_ FMO_qCor : 16|16@1- (0.01,0) [-327.68|327.67] "mg/hub"  PCM
 SG_ ActMod_trqClth : 0|16@1- (0.1,0) [-3276.8|3276.7] "Nm"  PCM

BO_ 2583640871 PB_TripInfo1_27: 8 VCM
 SG_ PriEptoEnergyCons : 32|32@1+ (0.1,0) [0|421108121.5] "kWh"  PCM
 SG_ TotTractEnergyCons : 0|32@1+ (0.001,0) [0|4211081.215] "kWh"  PCM

BO_ 2583640615 PB_TripInfo2_27: 8 VCM
 SG_ TotEnergyRecoveredWithBrks : 32|32@1+ (0.001,0) [0|4211081.215] "kWh"  PCM
 SG_ TotHvacEnergyCons : 0|32@1+ (0.1,0) [0|421108121.5] "kWh"  PCM

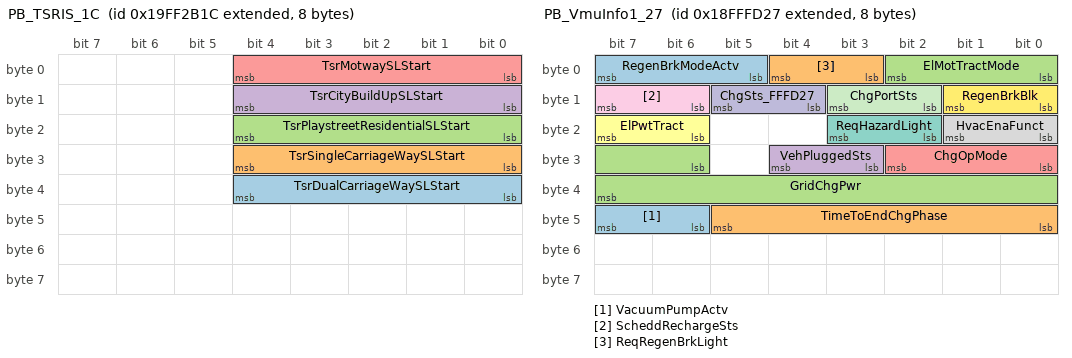
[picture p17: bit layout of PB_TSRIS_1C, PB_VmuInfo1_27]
BO_ 2583636764 PB_TSRIS_1C: 8 PCM
 SG_ TsrDualCarriageWaySLStart : 32|5@1+ (1,0) [0|31] "" Vector__XXX
 SG_ TsrSingleCarriageWaySLStart : 24|5@1+ (1,0) [0|31] "" Vector__XXX
 SG_ TsrPlaystreetResidentialSLStart : 16|5@1+ (1,0) [0|31] "" Vector__XXX
 SG_ TsrCityBuildUpSLStart : 8|5@1+ (1,0) [0|31] "" Vector__XXX
 SG_ TsrMotwaySLStart : 0|5@1+ (1,0) [0|31] "" Vector__XXX

BO_ 2566909770 PB_TXCMUDATA3_4A: 8 PCM
 SG_ VmuWakeUp : 56|2@1+ (1,0) [0|3] "" Vector__XXX

BO_ 2566867182 PB_VDO1: 32 DTCO
 SG_ SignifTimeOverlapInUsedDrivActiv : 254|2@1+ (1,0) [0|3] ""  PCM
 SG_ MultiManningCurShift : 252|2@1+ (1,0) [0|3] ""  PCM
 SG_ WeekRestPerCalcEna : 250|2@1+ (1,0) [0|3] ""  PCM
 SG_ NoSuffDataOnTheDrivCard : 248|2@1+ (1,0) [0|3] ""  PCM
 SG_ UnknownPer : 246|2@1+ (1,0) [0|3] ""  PCM
 SG_ RemReducDayRestPer : 243|3@1+ (1,0) [0|7] ""  PCM
 SG_ Rem10HDrivTimes : 240|3@1+ (1,0) [0|7] ""  PCM
 SG_ OpenCompIn2ndWeekBefLast : 224|16@1+ (1,0) [0|64255] "min"  PCM
 SG_ OpenCompInWeekBefLast : 208|16@1+ (1,0) [0|64255] "min"  PCM
 SG_ OpenCompInLw : 192|16@1+ (1,0) [0|64255] "min"  PCM
 SG_ DurOfNwlyRestPer : 176|16@1+ (1,0) [0|64255] "min"  PCM
 SG_ RemTimeTillNwlyRestPer : 160|16@1+ (1,0) [0|64255] "min"  PCM
 SG_ RemDrivTimeOfCw : 144|16@1+ (1,0) [0|64255] "min"  PCM
 SG_ DurOfNextDayRestPer : 128|16@1+ (1,0) [0|64255] "min"  PCM
 SG_ RemTimeTillNextDayRestPer : 112|16@1+ (1,0) [0|64255] "min"  PCM
 SG_ RemCurDayDrivTime : 96|16@1+ (1,0) [0|64255] "min"  PCM
 SG_ DurOfNextDrivPer : 80|16@1+ (1,0) [0|64255] "min"  PCM
 SG_ TimeBefStartOfNextDrivPer : 64|16@1+ (1,0) [0|64255] "min"  PCM
 SG_ RemDurOfCurBreak_Rest : 48|16@1+ (1,0) [0|64255] "min"  PCM
 SG_ DurOfNextRest_Break : 32|16@1+ (1,0) [0|64255] "min"  PCM
 SG_ RemTimeTillNextRest_Break : 16|16@1+ (1,0) [0|64255] "min"  PCM
 SG_ RemCurDrivTime : 0|16@1+ (1,0) [0|64255] "min"  PCM

BO_ 2566867694 PB_VDO2: 32 DTCO
 SG_ CwWorkTime : 144|16@1+ (1,0) [0|64255] "min"  PCM
 SG_ CurDayWorkTime : 128|16@1+ (1,0) [0|64255] "min"  PCM
 SG_ LwAssignReducWeekRestPer : 124|4@1+ (1,0) [0|15] ""  PCM
 SG_ LwAssignRegWeekRestPer : 120|4@1+ (1,0) [0|15] ""  PCM
 SG_ CwNumOfAssignReducWeekRestPer : 116|4@1+ (1,0) [0|15] ""  PCM
 SG_ CwNumOfAssignRegWeekRestPer : 112|4@1+ (1,0) [0|15] ""  PCM
 SG_ DurOfCurRestPer : 96|16@1+ (1,0) [0|64255] "min"  PCM
 SG_ DurOfCurRest : 80|16@1+ (1,0) [0|64255] "min"  PCM
 SG_ CumulBreakTime : 64|16@1+ (1,0) [0|64255] "min"  PCM
 SG_ WeekDrivTime : 48|16@1+ (1,0) [0|64255] "min"  PCM
 SG_ TwoWeeksDrivTime : 32|16@1+ (1,0) [0|64255] "min"  PCM
 SG_ DayDrivTime_FF4AEE : 16|16@1+ (1,0) [0|64255] "min"  PCM
 SG_ ContDrivTime : 0|16@1+ (1,0) [0|64255] "min"  PCM

BO_ 2583645991 PB_VMU2HMI_12_27: 8 VCM
 SG_ EmActPwrKw : 32|16@1+ (0.1,-150) [-150|6403.5] "kW"  PCM
 SG_ BatActPwrKw : 16|16@1- (0.05,-200) [-1838.4|1438.35] "kW"  PCM

BO_ 2566913319 PB_VmuInfo1_27: 8 VCM
 SG_ VacuumPumpActv : 46|2@1+ (1,0) [0|3] ""  PCM
 SG_ TimeToEndChgPhase : 40|6@1+ (15,0) [0|915] "min"  PCM
 SG_ GridChgPwr : 30|10@1+ (0.5,0) [0|500] "kW"  PCM
 SG_ VehPluggedSts : 27|2@1+ (1,0) [0|3] ""  PCM
 SG_ ChgOpMode : 24|3@1+ (1,0) [0|7] ""  PCM
 SG_ ElPwtTract : 22|2@1+ (1,0) [0|3] ""  PCM
 SG_ ReqHazardLight : 18|2@1+ (1,0) [0|3] ""  PCM
 SG_ HvacEnaFunct : 16|2@1+ (1,0) [0|3] ""  PCM
 SG_ ScheddRechargeSts : 14|2@1+ (1,0) [0|3] ""  PCM
 SG_ ChgSts_FFFD27 : 12|2@1+ (1,0) [0|3] ""  PCM
 SG_ ChgPortSts : 10|2@1+ (1,0) [0|3] ""  PCM
 SG_ RegenBrkBlk : 8|2@1+ (1,0) [0|3] ""  PCM
 SG_ RegenBrkModeActv : 5|3@1+ (1,0) [0|7] ""  PCM
 SG_ ReqRegenBrkLight : 3|2@1+ (1,0) [0|3] ""  PCM
 SG_ ElMotTractMode : 0|3@1+ (1,0) [0|7] ""  PCM

CM_ BO_ 2566908199 "- As Needed trasmission mode when in Key Off";
CM_ BO_ 2566908234 "- Sent by PCM for each Key cycle";
CM_ SG_ 2566908234 FmsExtTractModeReq "- Value Performance not used";
CM_ BO_ 2583664714 "- Sent by PCM at each Key Cycle";
CM_ SG_ 2566886227 SrsCfg "- TBC";
CM_ BO_ 2583669789 "- Sent 10 times each 2 seconds. SGW will stop the transmission when PB_SecureLog_4A is received";
CM_ BO_ 2566898670 "- Multipacket message handled by SAE Transport Protocol (J1939/21, par 5.10, Multipacket Broadcast with TP.CM/BAM, TP.DT)";
CM_ SG_ 2566898670 Driv1Id_FFC3EE "- Signal length 112 bits (14 ASCII chars)";
CM_ BO_ 2566899694 "- Multipacket message handled by SAE Transport Protocol (J1939/21, par 5.10, Multipacket Broadcast with TP.CM/BAM, TP.DT)";
CM_ SG_ 2566899694 AvCnt "- Currently not used";
CM_ SG_ 2566899694 WorkCnt "- Currently not used";
CM_ SG_ 2566899694 DrivCnt "- Currently not used";
CM_ SG_ 2566899694 TwoWeeksTotOdo "- Currently not used";
CM_ SG_ 2566899694 WeekTotOdo "- Currently not used";
CM_ SG_ 2566899694 DayOdo "- Currently not used";
CM_ SG_ 2566899694 DayRestPer7Flag "- 1b also when the info is Not Available";
CM_ SG_ 2566899694 DayRestPer6Flag "- 1b also when the info is Not Available";
CM_ SG_ 2566899694 DayRestPer5Flag "- 1b also when the info is Not Available";
CM_ SG_ 2566899694 DayRestPer4Flag "- 1b also when the info is Not Available";
CM_ SG_ 2566899694 DayRestPer3Flag "- 1b also when the info is Not Available";
CM_ SG_ 2566899694 DayRestPer2Flag "- 1b also when the info is Not Available";
CM_ SG_ 2566899694 DayRestPer1Flag "- 1b also when the info is Not Available";
CM_ SG_ 2566899694 DayDrivTimeShift6Flag "- 1b also when the info is Not Available";
CM_ SG_ 2566899694 DayDrivTimeShift5Flag "- 1b also when the info is Not Available";
CM_ SG_ 2566899694 DayDrivTimeShift4Flag "- 1b also when the info is Not Available";
CM_ SG_ 2566899694 DayDrivTimeShift3Flag "- 1b also when the info is Not Available";
CM_ SG_ 2566899694 DayDrivTimeShift2Flag "- 1b also when the info is Not Available";
CM_ SG_ 2566899694 DayDrivTimeShift1Flag "- 1b also when the info is Not Available";
CM_ SG_ 2566899694 DayDrivTimeFlag "- 1b also when the info is Not Available";
CM_ SG_ 2583640871 PriEptoEnergyCons "- Primary ePTO Data";
CM_ BO_ 2566909770 "-  2 Message Variant(s): Transm.Rates 50 / 100 / -, 100
-  Faster Transmission Rate till wakeup (2s max), then every 100 ms when active";
CM_ BO_ 2566867182 "- PGN=0xFF00 as Conti default, 0xFF48 applied by Iveco";
CM_ SG_ 2566867182 SignifTimeOverlapInUsedDrivActiv "- SPN Position to be verified";
CM_ SG_ 2566867182 MultiManningCurShift "- SPN Position to be verified";
CM_ SG_ 2566867182 WeekRestPerCalcEna "- SPN Position to be verified";
CM_ SG_ 2566867182 NoSuffDataOnTheDrivCard "- SPN Position to be verified";
CM_ SG_ 2566867182 UnknownPer "- SPN Position to be verified";
CM_ SG_ 2566867182 RemReducDayRestPer "- SPN Position to be verified";
CM_ SG_ 2566867182 Rem10HDrivTimes "- SPN Position to be verified";
CM_ BO_ 2566867694 "- PGN=0xFF02 as Conti default, 0xFF4A applied by Iveco";
CM_ BO_ 2566913319 "- Active also in Doze mode";
BA_DEF_ BO_  "CI_MsgDefinition" STRING ;
BA_DEF_ BO_  "CI_MsgId" INT 0 2147483647;
BA_DEF_ BO_  "CI_MsgName" STRING ;
BA_DEF_ BO_  "GenMsgCycleTime" INT 0 3600000;
BA_DEF_ BO_  "GenMsgCycleTimeFast" INT 0 3600000;
BA_DEF_ BO_  "GenMsgDelayTime" INT 0 3600000;
BA_DEF_ BO_  "GenMsgILSupport" ENUM  "No","Yes";
BA_DEF_ BO_  "GenMsgNrOfRepetition" INT 0 1000000;
BA_DEF_ BO_  "GenMsgRequestable" INT 0 1;
BA_DEF_ BO_  "GenMsgSendType" ENUM  "cyclic","NotUsed","NotUsed","NotUsed","NotUsed","NotUsed","NotUsed","IfActive","noMsgSendType";
BA_DEF_ BO_  "GenMsgStartDelayTime" INT 0 100000;
BA_DEF_ BO_  "TpJ1939VarDlc" ENUM  "No","Yes";
BA_DEF_ BO_  "VFrameFormat" ENUM  "StandardCAN","ExtendedCAN","reserved","J1939PG";
BA_DEF_ SG_  "CI_ParId" STRING ;
BA_DEF_ SG_  "CI_SigId" INT 0 2147483647;
BA_DEF_ SG_  "CI_SigName" STRING ;
BA_DEF_ SG_  "GenSigEVName" STRING ;
BA_DEF_ SG_  "GenSigILSupport" ENUM  "No","Yes";
BA_DEF_ SG_  "GenSigInactiveValue" INT 0 2147483647;
BA_DEF_ SG_  "GenSigSendType" ENUM  "Cyclic","OnWrite","OnWriteWithRepetition","OnChange","OnChangeWithRepetition","IfActive","IfActiveWithRepetition","NoSigSendType";
BA_DEF_ SG_  "GenSigStartValue" INT 0 2147483647;
BA_DEF_ SG_  "GenSigTimeoutTime_PCM" INT 0 3600000;
BA_DEF_ SG_  "GenSigTimeoutTime_SGW" INT 0 3600000;
BA_DEF_ SG_  "SPN" INT 0 524287;
BA_DEF_ SG_  "SigType" ENUM  "Default","Range","RangeSigned","ASCII","Discrete","Control","ReferencePGN","DTC","StringDelimiter","StringLength","StringLengthControl";
BA_DEF_DEF_  "CI_MsgDefinition" "";
BA_DEF_DEF_  "CI_MsgId" 0;
BA_DEF_DEF_  "CI_MsgName" "";
BA_DEF_DEF_  "GenMsgCycleTime" 0;
BA_DEF_DEF_  "GenMsgCycleTimeFast" 0;
BA_DEF_DEF_  "GenMsgDelayTime" 1;
BA_DEF_DEF_  "GenMsgILSupport" "Yes";
BA_DEF_DEF_  "GenMsgNrOfRepetition" 0;
BA_DEF_DEF_  "GenMsgRequestable" 0;
BA_DEF_DEF_  "GenMsgSendType" "noMsgSendType";
BA_DEF_DEF_  "GenMsgStartDelayTime" 0;
BA_DEF_DEF_  "TpJ1939VarDlc" "No";
BA_DEF_DEF_  "VFrameFormat" "J1939PG";
BA_DEF_DEF_  "CI_ParId" "";
BA_DEF_DEF_  "CI_SigId" 0;
BA_DEF_DEF_  "CI_SigName" "";
BA_DEF_DEF_  "GenSigEVName" "Env@Nodename_@Signame";
BA_DEF_DEF_  "GenSigILSupport" "Yes";
BA_DEF_DEF_  "GenSigInactiveValue" 0;
BA_DEF_DEF_  "GenSigSendType" "NoSigSendType";
BA_DEF_DEF_  "GenSigStartValue" 0;
BA_DEF_DEF_  "GenSigTimeoutTime_PCM" 0;
BA_DEF_DEF_  "GenSigTimeoutTime_SGW" 0;
BA_DEF_DEF_  "SPN" 0;
BA_DEF_DEF_  "SigType" "Default";
BA_ "CI_MsgDefinition" BO_ 2650776967 "Iveco Daily Electric";
BA_ "CI_MsgId" BO_ 2650776967 45474;
BA_ "CI_MsgName" BO_ 2650776967 "PB_ROC_87 - Proprietary B - Relay Operation Counter";
BA_ "GenMsgCycleTime" BO_ 2650776967 600000;
BA_ "GenMsgCycleTimeFast" BO_ 2650776967 600000;
BA_ "GenMsgDelayTime" BO_ 2650776967 300000;
BA_ "GenMsgSendType" BO_ 2650776967 0;
BA_ "GenMsgStartDelayTime" BO_ 2650776967 382;
BA_ "CI_MsgDefinition" BO_ 2650777076 "Iveco Daily Electric";
BA_ "CI_MsgId" BO_ 2650777076 45442;
BA_ "CI_MsgName" BO_ 2650777076 "PB_ROC_F4 - Proprietary B - Relay Operation Counter";
BA_ "GenMsgCycleTime" BO_ 2650777076 600000;
BA_ "GenMsgCycleTimeFast" BO_ 2650777076 600000;
BA_ "GenMsgDelayTime" BO_ 2650777076 300000;
BA_ "GenMsgSendType" BO_ 2650777076 0;
BA_ "GenMsgStartDelayTime" BO_ 2650777076 383;
BA_ "CI_MsgDefinition" BO_ 2650777077 "Iveco Daily Electric";
BA_ "CI_MsgId" BO_ 2650777077 45450;
BA_ "CI_MsgName" BO_ 2650777077 "PB_ROC_F5 - Proprietary B - Relay Operation Counter";
BA_ "GenMsgCycleTime" BO_ 2650777077 600000;
BA_ "GenMsgCycleTimeFast" BO_ 2650777077 600000;
BA_ "GenMsgDelayTime" BO_ 2650777077 300000;
BA_ "GenMsgSendType" BO_ 2650777077 0;
BA_ "GenMsgStartDelayTime" BO_ 2650777077 384;
BA_ "CI_MsgDefinition" BO_ 2650777078 "Iveco Daily Electric";
BA_ "CI_MsgId" BO_ 2650777078 45458;
BA_ "CI_MsgName" BO_ 2650777078 "PB_ROC_F6 - Proprietary B - Relay Operation Counter";
BA_ "GenMsgCycleTime" BO_ 2650777078 600000;
BA_ "GenMsgCycleTimeFast" BO_ 2650777078 600000;
BA_ "GenMsgDelayTime" BO_ 2650777078 300000;
BA_ "GenMsgSendType" BO_ 2650777078 0;
BA_ "GenMsgStartDelayTime" BO_ 2650777078 385;
BA_ "CI_MsgDefinition" BO_ 2566908199 "Iveco Daily Electric";
BA_ "CI_MsgId" BO_ 2566908199 8642;
BA_ "CI_MsgName" BO_ 2566908199 "PB_RRCS_27 - Proprietary B - Remote Request Command Status";
BA_ "GenMsgCycleTime" BO_ 2566908199 1000;
BA_ "GenMsgCycleTimeFast" BO_ 2566908199 1000;
BA_ "GenMsgDelayTime" BO_ 2566908199 500;
BA_ "GenMsgSendType" BO_ 2566908199 0;
BA_ "GenMsgStartDelayTime" BO_ 2566908199 279;
BA_ "CI_MsgDefinition" BO_ 2566908234 "Iveco Daily Electric";
BA_ "CI_MsgId" BO_ 2566908234 8623;
BA_ "CI_MsgName" BO_ 2566908234 "PB_RRCS_4A - Proprietary B - Remote Request Command Status";
BA_ "CI_MsgDefinition" BO_ 2583664714 "Iveco Daily";
BA_ "CI_MsgId" BO_ 2583664714 44713;
BA_ "CI_MsgName" BO_ 2583664714 "PB_RRCS2_4A - Proprietary B - Remote Request Command Status 2";
BA_ "GenMsgDelayTime" BO_ 2583664714 100;
BA_ "CI_MsgDefinition" BO_ 2566896409 "Sanden Proprietary";
BA_ "CI_MsgId" BO_ 2566896409 8922;
BA_ "CI_MsgName" BO_ 2566896409 "PB_Sa_EacCmd - Proprietary B - Electric Air Compressor Command message";
BA_ "GenMsgCycleTime" BO_ 2566896409 1000;
BA_ "GenMsgCycleTimeFast" BO_ 2566896409 1000;
BA_ "GenMsgDelayTime" BO_ 2566896409 100;
BA_ "GenMsgSendType" BO_ 2566896409 0;
BA_ "GenMsgStartDelayTime" BO_ 2566896409 267;
BA_ "CI_MsgDefinition" BO_ 2566897046 "Sanden Proprietary";
BA_ "CI_MsgId" BO_ 2566897046 8926;
BA_ "CI_MsgName" BO_ 2566897046 "PB_Sa_EacSts - Proprietary B - Electric Air Compressor Status message";
BA_ "GenMsgCycleTime" BO_ 2566897046 1000;
BA_ "GenMsgCycleTimeFast" BO_ 2566897046 1000;
BA_ "GenMsgDelayTime" BO_ 2566897046 500;
BA_ "GenMsgSendType" BO_ 2566897046 0;
BA_ "GenMsgStartDelayTime" BO_ 2566897046 269;
BA_ "CI_MsgDefinition" BO_ 2566886218 "Iveco Proprietary";
BA_ "CI_MsgId" BO_ 2566886218 45133;
BA_ "CI_MsgName" BO_ 2566886218 "PB_SDMInfo_4A - Proprietary B - Sensing and Diagnostic Module Information";
BA_ "GenMsgCycleTime" BO_ 2566886218 1000;
BA_ "GenMsgCycleTimeFast" BO_ 2566886218 1000;
BA_ "GenMsgDelayTime" BO_ 2566886218 100;
BA_ "GenMsgSendType" BO_ 2566886218 0;
BA_ "GenMsgStartDelayTime" BO_ 2566886218 24;
BA_ "CI_MsgDefinition" BO_ 2566886227 "Iveco Proprietary";
BA_ "CI_MsgId" BO_ 2566886227 43096;
BA_ "CI_MsgName" BO_ 2566886227 "PB_SDMInfo_53 - Proprietary B - Sensing and Diagnostic Module Information";
BA_ "GenMsgCycleTime" BO_ 2566886227 250;
BA_ "GenMsgCycleTimeFast" BO_ 2566886227 250;
BA_ "GenMsgDelayTime" BO_ 2566886227 125;
BA_ "GenMsgSendType" BO_ 2566886227 0;
BA_ "GenMsgStartDelayTime" BO_ 2566886227 112;
BA_ "CI_MsgDefinition" BO_ 2583669789 "Iveco Proprietary";
BA_ "CI_MsgId" BO_ 2583669789 45126;
BA_ "CI_MsgName" BO_ 2583669789 "PB_SecureLog_1D - Proprietary B - Secure Log";
BA_ "GenMsgDelayTime" BO_ 2583669789 50;
BA_ "CI_MsgDefinition" BO_ 2583669834 "Iveco Proprietary";
BA_ "CI_MsgId" BO_ 2583669834 45131;
BA_ "CI_MsgName" BO_ 2583669834 "PB_SecureLog_4A - Proprietary B - Secure Log";
BA_ "GenMsgDelayTime" BO_ 2583669834 50;
BA_ "CI_MsgDefinition" BO_ 2650775319 "Iveco Proprietary";
BA_ "CI_MsgId" BO_ 2650775319 36879;
BA_ "CI_MsgName" BO_ 2650775319 "PB_SetHmi_17 - Proprietary B - Setting Hmi";
BA_ "GenMsgCycleTime" BO_ 2650775319 1000;
BA_ "GenMsgCycleTimeFast" BO_ 2650775319 1000;
BA_ "GenMsgDelayTime" BO_ 2650775319 500;
BA_ "GenMsgSendType" BO_ 2650775319 0;
BA_ "GenMsgStartDelayTime" BO_ 2650775319 324;
BA_ "CI_MsgDefinition" BO_ 2650775335 "Iveco Proprietary";
BA_ "CI_MsgId" BO_ 2650775335 41807;
BA_ "CI_MsgName" BO_ 2650775335 "PB_SetHmi_27 - Proprietary B - Setting Hmi";
BA_ "GenMsgCycleTime" BO_ 2650775335 1000;
BA_ "GenMsgCycleTimeFast" BO_ 2650775335 1000;
BA_ "GenMsgDelayTime" BO_ 2650775335 500;
BA_ "GenMsgSendType" BO_ 2650775335 0;
BA_ "GenMsgStartDelayTime" BO_ 2650775335 325;
BA_ "CI_MsgDefinition" BO_ 2650775370 "Iveco Proprietary";
BA_ "CI_MsgId" BO_ 2650775370 36881;
BA_ "CI_MsgName" BO_ 2650775370 "PB_SetHmi_4A - Proprietary B - Setting Hmi";
BA_ "GenMsgCycleTime" BO_ 2650775370 1000;
BA_ "GenMsgCycleTimeFast" BO_ 2650775370 1000;
BA_ "GenMsgDelayTime" BO_ 2650775370 500;
BA_ "GenMsgSendType" BO_ 2650775370 0;
BA_ "GenMsgStartDelayTime" BO_ 2650775370 36;
BA_ "CI_MsgDefinition" BO_ 2583678231 "Iveco Proprietary";
BA_ "CI_MsgId" BO_ 2583678231 44737;
BA_ "CI_MsgName" BO_ 2583678231 "PB_SetupMenu_17 - Proprietary B - Setup Passive Entry Passive Start";
BA_ "GenMsgCycleTime" BO_ 2583678231 1000;
BA_ "GenMsgCycleTimeFast" BO_ 2583678231 1000;
BA_ "GenMsgDelayTime" BO_ 2583678231 100;
BA_ "GenMsgSendType" BO_ 2583678231 0;
BA_ "GenMsgStartDelayTime" BO_ 2583678231 292;
BA_ "CI_MsgDefinition" BO_ 2583678241 "Iveco Proprietary";
BA_ "CI_MsgId" BO_ 2583678241 44771;
BA_ "CI_MsgName" BO_ 2583678241 "PB_SetupMenu_21 - Proprietary B - Setup Passive Entry Passive Start";
BA_ "GenMsgCycleTime" BO_ 2583678241 1000;
BA_ "GenMsgCycleTimeFast" BO_ 2583678241 1000;
BA_ "GenMsgDelayTime" BO_ 2583678241 100;
BA_ "GenMsgSendType" BO_ 2583678241 0;
BA_ "GenMsgStartDelayTime" BO_ 2583678241 293;
BA_ "CI_MsgDefinition" BO_ 2650777734 "Iveco Daily Electric";
BA_ "CI_MsgId" BO_ 2650777734 44192;
BA_ "CI_MsgName" BO_ 2650777734 "PB_STC_86 - Proprietary B - S Time Counter";
BA_ "GenMsgCycleTime" BO_ 2650777734 600000;
BA_ "GenMsgCycleTimeFast" BO_ 2650777734 600000;
BA_ "GenMsgDelayTime" BO_ 2650777734 300000;
BA_ "GenMsgSendType" BO_ 2650777734 0;
BA_ "GenMsgStartDelayTime" BO_ 2650777734 397;
BA_ "CI_MsgDefinition" BO_ 2650777735 "Iveco Daily Electric";
BA_ "CI_MsgId" BO_ 2650777735 44205;
BA_ "CI_MsgName" BO_ 2650777735 "PB_STC_87 - Proprietary B - S Time Counter";
BA_ "GenMsgCycleTime" BO_ 2650777735 600000;
BA_ "GenMsgCycleTimeFast" BO_ 2650777735 600000;
BA_ "GenMsgDelayTime" BO_ 2650777735 300000;
BA_ "GenMsgSendType" BO_ 2650777735 0;
BA_ "GenMsgStartDelayTime" BO_ 2650777735 398;
BA_ "CI_MsgDefinition" BO_ 2650777844 "Iveco Daily Electric";
BA_ "CI_MsgId" BO_ 2650777844 44153;
BA_ "CI_MsgName" BO_ 2650777844 "PB_STC_F4 - Proprietary B - S Time Counter";
BA_ "GenMsgCycleTime" BO_ 2650777844 600000;
BA_ "GenMsgCycleTimeFast" BO_ 2650777844 600000;
BA_ "GenMsgDelayTime" BO_ 2650777844 300000;
BA_ "GenMsgSendType" BO_ 2650777844 0;
BA_ "GenMsgStartDelayTime" BO_ 2650777844 399;
BA_ "CI_MsgDefinition" BO_ 2650777845 "Iveco Daily Electric";
BA_ "CI_MsgId" BO_ 2650777845 44166;
BA_ "CI_MsgName" BO_ 2650777845 "PB_STC_F5 - Proprietary B - S Time Counter";
BA_ "GenMsgCycleTime" BO_ 2650777845 600000;
BA_ "GenMsgCycleTimeFast" BO_ 2650777845 600000;
BA_ "GenMsgDelayTime" BO_ 2650777845 300000;
BA_ "GenMsgSendType" BO_ 2650777845 0;
BA_ "GenMsgStartDelayTime" BO_ 2650777845 401;
BA_ "CI_MsgDefinition" BO_ 2650777846 "Iveco Daily Electric";
BA_ "CI_MsgId" BO_ 2650777846 44179;
BA_ "CI_MsgName" BO_ 2650777846 "PB_STC_F6 - Proprietary B - S Time Counter";
BA_ "GenMsgCycleTime" BO_ 2650777846 600000;
BA_ "GenMsgCycleTimeFast" BO_ 2650777846 600000;
BA_ "GenMsgDelayTime" BO_ 2650777846 300000;
BA_ "GenMsgSendType" BO_ 2650777846 0;
BA_ "GenMsgStartDelayTime" BO_ 2650777846 402;
BA_ "CI_MsgDefinition" BO_ 2583654525 "Iveco Daily China";
BA_ "CI_MsgId" BO_ 2583654525 33779;
BA_ "CI_MsgName" BO_ 2583654525 "PB_TBoxInfo_7D - Proprietary B - Tbox Information";
BA_ "GenMsgCycleTime" BO_ 2583654525 5000;
BA_ "GenMsgCycleTimeFast" BO_ 2583654525 5000;
BA_ "GenMsgDelayTime" BO_ 2583654525 2500;
BA_ "GenMsgSendType" BO_ 2583654525 0;
BA_ "GenMsgStartDelayTime" BO_ 2583654525 339;
BA_ "CI_MsgDefinition" BO_ 2566898670 "Continental Proprietary";
BA_ "CI_MsgId" BO_ 2566898670 1655;
BA_ "CI_MsgName" BO_ 2566898670 "PB_TCO2 - TCO2 (Continental Proprietary)";
BA_ "GenMsgCycleTime" BO_ 2566898670 60000;
BA_ "GenMsgCycleTimeFast" BO_ 2566898670 60000;
BA_ "GenMsgDelayTime" BO_ 2566898670 1000;
BA_ "GenMsgSendType" BO_ 2566898670 0;
BA_ "GenMsgStartDelayTime" BO_ 2566898670 367;
BA_ "CI_MsgDefinition" BO_ 2566898926 "Continental Proprietary";
BA_ "CI_MsgId" BO_ 2566898926 1662;
BA_ "CI_MsgName" BO_ 2566898926 "PB_TCO3 - TCO3 (Continental Proprietary)";
BA_ "GenMsgCycleTime" BO_ 2566898926 10000;
BA_ "GenMsgCycleTimeFast" BO_ 2566898926 10000;
BA_ "GenMsgDelayTime" BO_ 2566898926 5000;
BA_ "GenMsgSendType" BO_ 2566898926 0;
BA_ "GenMsgStartDelayTime" BO_ 2566898926 345;
BA_ "CI_MsgDefinition" BO_ 2566899694 "Continental Proprietary";
BA_ "CI_MsgId" BO_ 2566899694 1669;
BA_ "CI_MsgName" BO_ 2566899694 "PB_TCO4 - TCO4 (Continental Proprietary)";
BA_ "GenMsgCycleTime" BO_ 2566899694 60000;
BA_ "GenMsgCycleTimeFast" BO_ 2566899694 60000;
BA_ "GenMsgDelayTime" BO_ 2566899694 1000;
BA_ "GenMsgSendType" BO_ 2566899694 0;
BA_ "GenMsgStartDelayTime" BO_ 2566899694 368;
BA_ "CI_MsgDefinition" BO_ 2650771712 "Iveco Proprietary";
BA_ "CI_MsgId" BO_ 2650771712 37321;
BA_ "CI_MsgName" BO_ 2650771712 "PB_Telemetry01 - Proprietary B - Telemetry 01";
BA_ "GenMsgCycleTime" BO_ 2650771712 5000;
BA_ "GenMsgCycleTimeFast" BO_ 2650771712 5000;
BA_ "GenMsgDelayTime" BO_ 2650771712 2500;
BA_ "GenMsgSendType" BO_ 2650771712 0;
BA_ "GenMsgStartDelayTime" BO_ 2650771712 341;
BA_ "CI_MsgDefinition" BO_ 2650771968 "Iveco Proprietary";
BA_ "CI_MsgId" BO_ 2650771968 37323;
BA_ "CI_MsgName" BO_ 2650771968 "PB_Telemetry02 - Proprietary B - Telemetry 02";
BA_ "GenMsgCycleTime" BO_ 2650771968 5000;
BA_ "GenMsgCycleTimeFast" BO_ 2650771968 5000;
BA_ "GenMsgDelayTime" BO_ 2650771968 2500;
BA_ "GenMsgSendType" BO_ 2650771968 0;
BA_ "GenMsgStartDelayTime" BO_ 2650771968 342;
BA_ "CI_MsgDefinition" BO_ 2650772224 "Iveco Proprietary";
BA_ "CI_MsgId" BO_ 2650772224 37325;
BA_ "CI_MsgName" BO_ 2650772224 "PB_Telemetry03 - Proprietary B - Telemetry 03";
BA_ "GenMsgCycleTime" BO_ 2650772224 1000;
BA_ "GenMsgCycleTimeFast" BO_ 2650772224 1000;
BA_ "GenMsgDelayTime" BO_ 2650772224 500;
BA_ "GenMsgSendType" BO_ 2650772224 0;
BA_ "GenMsgStartDelayTime" BO_ 2650772224 323;
BA_ "CI_MsgDefinition" BO_ 2650764288 "Iveco Proprietary";
BA_ "CI_MsgId" BO_ 2650764288 37327;
BA_ "CI_MsgName" BO_ 2650764288 "PB_Telemetry04 - Proprietary B - Telemetry 04";
BA_ "GenMsgCycleTime" BO_ 2650764288 1000;
BA_ "GenMsgCycleTimeFast" BO_ 2650764288 1000;
BA_ "GenMsgDelayTime" BO_ 2650764288 500;
BA_ "GenMsgSendType" BO_ 2650764288 0;
BA_ "GenMsgStartDelayTime" BO_ 2650764288 295;
BA_ "CI_MsgDefinition" BO_ 2650764544 "Iveco Proprietary";
BA_ "CI_MsgId" BO_ 2650764544 37329;
BA_ "CI_MsgName" BO_ 2650764544 "PB_Telemetry05 - Proprietary B - Telemetry 05";
BA_ "GenMsgCycleTime" BO_ 2650764544 1000;
BA_ "GenMsgCycleTimeFast" BO_ 2650764544 1000;
BA_ "GenMsgDelayTime" BO_ 2650764544 500;
BA_ "GenMsgSendType" BO_ 2650764544 0;
BA_ "GenMsgStartDelayTime" BO_ 2650764544 296;
BA_ "CI_MsgDefinition" BO_ 2650764800 "Iveco Proprietary";
BA_ "CI_MsgId" BO_ 2650764800 37331;
BA_ "CI_MsgName" BO_ 2650764800 "PB_Telemetry06 - Proprietary B - Telemetry 06";
BA_ "GenMsgCycleTime" BO_ 2650764800 1000;
BA_ "GenMsgCycleTimeFast" BO_ 2650764800 1000;
BA_ "GenMsgDelayTime" BO_ 2650764800 500;
BA_ "GenMsgSendType" BO_ 2650764800 0;
BA_ "GenMsgStartDelayTime" BO_ 2650764800 297;
BA_ "CI_MsgDefinition" BO_ 2650765056 "Iveco Proprietary";
BA_ "CI_MsgId" BO_ 2650765056 37333;
BA_ "CI_MsgName" BO_ 2650765056 "PB_Telemetry07 - Proprietary B - Telemetry 07";
BA_ "GenMsgCycleTime" BO_ 2650765056 1000;
BA_ "GenMsgCycleTimeFast" BO_ 2650765056 1000;
BA_ "GenMsgDelayTime" BO_ 2650765056 500;
BA_ "GenMsgSendType" BO_ 2650765056 0;
BA_ "GenMsgStartDelayTime" BO_ 2650765056 298;
BA_ "CI_MsgDefinition" BO_ 2650765312 "Iveco Proprietary";
BA_ "CI_MsgId" BO_ 2650765312 37335;
BA_ "CI_MsgName" BO_ 2650765312 "PB_Telemetry08 - Proprietary B - Telemetry 08";
BA_ "GenMsgCycleTime" BO_ 2650765312 1000;
BA_ "GenMsgCycleTimeFast" BO_ 2650765312 1000;
BA_ "GenMsgDelayTime" BO_ 2650765312 500;
BA_ "GenMsgSendType" BO_ 2650765312 0;
BA_ "GenMsgStartDelayTime" BO_ 2650765312 299;
BA_ "CI_MsgDefinition" BO_ 2650765568 "Iveco Proprietary";
BA_ "CI_MsgId" BO_ 2650765568 37337;
BA_ "CI_MsgName" BO_ 2650765568 "PB_Telemetry09 - Proprietary B - Telemetry 09";
BA_ "GenMsgCycleTime" BO_ 2650765568 1000;
BA_ "GenMsgCycleTimeFast" BO_ 2650765568 1000;
BA_ "GenMsgDelayTime" BO_ 2650765568 500;
BA_ "GenMsgSendType" BO_ 2650765568 0;
BA_ "GenMsgStartDelayTime" BO_ 2650765568 301;
BA_ "CI_MsgDefinition" BO_ 2650765824 "Iveco Proprietary";
BA_ "CI_MsgId" BO_ 2650765824 37339;
BA_ "CI_MsgName" BO_ 2650765824 "PB_Telemetry10 - Proprietary B - Telemetry 10";
BA_ "GenMsgCycleTime" BO_ 2650765824 1000;
BA_ "GenMsgCycleTimeFast" BO_ 2650765824 1000;
BA_ "GenMsgDelayTime" BO_ 2650765824 500;
BA_ "GenMsgSendType" BO_ 2650765824 0;
BA_ "GenMsgStartDelayTime" BO_ 2650765824 302;
BA_ "CI_MsgDefinition" BO_ 2650766080 "Iveco Proprietary";
BA_ "CI_MsgId" BO_ 2650766080 37341;
BA_ "CI_MsgName" BO_ 2650766080 "PB_Telemetry11 - Proprietary B - Telemetry 11";
BA_ "GenMsgCycleTime" BO_ 2650766080 1000;
BA_ "GenMsgCycleTimeFast" BO_ 2650766080 1000;
BA_ "GenMsgDelayTime" BO_ 2650766080 500;
BA_ "GenMsgSendType" BO_ 2650766080 0;
BA_ "GenMsgStartDelayTime" BO_ 2650766080 303;
BA_ "CI_MsgDefinition" BO_ 2650766336 "Iveco Proprietary";
BA_ "CI_MsgId" BO_ 2650766336 37343;
BA_ "CI_MsgName" BO_ 2650766336 "PB_Telemetry12 - Proprietary B - Telemetry 12";
BA_ "GenMsgCycleTime" BO_ 2650766336 1000;
BA_ "GenMsgCycleTimeFast" BO_ 2650766336 1000;
BA_ "GenMsgDelayTime" BO_ 2650766336 500;
BA_ "GenMsgSendType" BO_ 2650766336 0;
BA_ "GenMsgStartDelayTime" BO_ 2650766336 304;
BA_ "CI_MsgDefinition" BO_ 2650766592 "Iveco Proprietary";
BA_ "CI_MsgId" BO_ 2650766592 37345;
BA_ "CI_MsgName" BO_ 2650766592 "PB_Telemetry13 - Proprietary B - Telemetry 13";
BA_ "GenMsgCycleTime" BO_ 2650766592 1000;
BA_ "GenMsgCycleTimeFast" BO_ 2650766592 1000;
BA_ "GenMsgDelayTime" BO_ 2650766592 500;
BA_ "GenMsgSendType" BO_ 2650766592 0;
BA_ "GenMsgStartDelayTime" BO_ 2650766592 305;
BA_ "CI_MsgDefinition" BO_ 2650766848 "Iveco Proprietary";
BA_ "CI_MsgId" BO_ 2650766848 37347;
BA_ "CI_MsgName" BO_ 2650766848 "PB_Telemetry14 - Proprietary B - Telemetry 14";
BA_ "GenMsgCycleTime" BO_ 2650766848 1000;
BA_ "GenMsgCycleTimeFast" BO_ 2650766848 1000;
BA_ "GenMsgDelayTime" BO_ 2650766848 500;
BA_ "GenMsgSendType" BO_ 2650766848 0;
BA_ "GenMsgStartDelayTime" BO_ 2650766848 306;
BA_ "CI_MsgDefinition" BO_ 2650767104 "Iveco Proprietary";
BA_ "CI_MsgId" BO_ 2650767104 37349;
BA_ "CI_MsgName" BO_ 2650767104 "PB_Telemetry15 - Proprietary B - Telemetry 15";
BA_ "GenMsgCycleTime" BO_ 2650767104 1000;
BA_ "GenMsgCycleTimeFast" BO_ 2650767104 1000;
BA_ "GenMsgDelayTime" BO_ 2650767104 500;
BA_ "GenMsgSendType" BO_ 2650767104 0;
BA_ "GenMsgStartDelayTime" BO_ 2650767104 307;
BA_ "CI_MsgDefinition" BO_ 2650767360 "Iveco Proprietary";
BA_ "CI_MsgId" BO_ 2650767360 37351;
BA_ "CI_MsgName" BO_ 2650767360 "PB_Telemetry16 - Proprietary B - Telemetry 16";
BA_ "GenMsgCycleTime" BO_ 2650767360 1000;
BA_ "GenMsgCycleTimeFast" BO_ 2650767360 1000;
BA_ "GenMsgDelayTime" BO_ 2650767360 500;
BA_ "GenMsgSendType" BO_ 2650767360 0;
BA_ "GenMsgStartDelayTime" BO_ 2650767360 308;
BA_ "CI_MsgDefinition" BO_ 2650767616 "Iveco Proprietary";
BA_ "CI_MsgId" BO_ 2650767616 37353;
BA_ "CI_MsgName" BO_ 2650767616 "PB_Telemetry17 - Proprietary B - Telemetry 17";
BA_ "GenMsgCycleTime" BO_ 2650767616 1000;
BA_ "GenMsgCycleTimeFast" BO_ 2650767616 1000;
BA_ "GenMsgDelayTime" BO_ 2650767616 500;
BA_ "GenMsgSendType" BO_ 2650767616 0;
BA_ "GenMsgStartDelayTime" BO_ 2650767616 309;
BA_ "CI_MsgDefinition" BO_ 2650767872 "Iveco Proprietary";
BA_ "CI_MsgId" BO_ 2650767872 37355;
BA_ "CI_MsgName" BO_ 2650767872 "PB_Telemetry18 - Proprietary B - Telemetry 18";
BA_ "GenMsgCycleTime" BO_ 2650767872 1000;
BA_ "GenMsgCycleTimeFast" BO_ 2650767872 1000;
BA_ "GenMsgDelayTime" BO_ 2650767872 500;
BA_ "GenMsgSendType" BO_ 2650767872 0;
BA_ "GenMsgStartDelayTime" BO_ 2650767872 311;
BA_ "CI_MsgDefinition" BO_ 2650768128 "Iveco Proprietary";
BA_ "CI_MsgId" BO_ 2650768128 37357;
BA_ "CI_MsgName" BO_ 2650768128 "PB_Telemetry19 - Proprietary B - Telemetry 19";
BA_ "GenMsgCycleTime" BO_ 2650768128 1000;
BA_ "GenMsgCycleTimeFast" BO_ 2650768128 1000;
BA_ "GenMsgDelayTime" BO_ 2650768128 500;
BA_ "GenMsgSendType" BO_ 2650768128 0;
BA_ "GenMsgStartDelayTime" BO_ 2650768128 312;
BA_ "CI_MsgDefinition" BO_ 2650768384 "Iveco Proprietary";
BA_ "CI_MsgId" BO_ 2650768384 37359;
BA_ "CI_MsgName" BO_ 2650768384 "PB_Telemetry20 - Proprietary B - Telemetry 20";
BA_ "GenMsgCycleTime" BO_ 2650768384 1000;
BA_ "GenMsgCycleTimeFast" BO_ 2650768384 1000;
BA_ "GenMsgDelayTime" BO_ 2650768384 500;
BA_ "GenMsgSendType" BO_ 2650768384 0;
BA_ "GenMsgStartDelayTime" BO_ 2650768384 313;
BA_ "CI_MsgDefinition" BO_ 2650768640 "Iveco Proprietary";
BA_ "CI_MsgId" BO_ 2650768640 37361;
BA_ "CI_MsgName" BO_ 2650768640 "PB_Telemetry21 - Proprietary B - Telemetry 21";
BA_ "GenMsgCycleTime" BO_ 2650768640 1000;
BA_ "GenMsgCycleTimeFast" BO_ 2650768640 1000;
BA_ "GenMsgDelayTime" BO_ 2650768640 500;
BA_ "GenMsgSendType" BO_ 2650768640 0;
BA_ "GenMsgStartDelayTime" BO_ 2650768640 314;
BA_ "CI_MsgDefinition" BO_ 2650768896 "Iveco Proprietary";
BA_ "CI_MsgId" BO_ 2650768896 37363;
BA_ "CI_MsgName" BO_ 2650768896 "PB_Telemetry22 - Proprietary B - Telemetry 22";
BA_ "GenMsgCycleTime" BO_ 2650768896 1000;
BA_ "GenMsgCycleTimeFast" BO_ 2650768896 1000;
BA_ "GenMsgDelayTime" BO_ 2650768896 500;
BA_ "GenMsgSendType" BO_ 2650768896 0;
BA_ "GenMsgStartDelayTime" BO_ 2650768896 315;
BA_ "CI_MsgDefinition" BO_ 2650769152 "Iveco Proprietary";
BA_ "CI_MsgId" BO_ 2650769152 37365;
BA_ "CI_MsgName" BO_ 2650769152 "PB_Telemetry23 - Proprietary B - Telemetry 23";
BA_ "GenMsgCycleTime" BO_ 2650769152 1000;
BA_ "GenMsgCycleTimeFast" BO_ 2650769152 1000;
BA_ "GenMsgDelayTime" BO_ 2650769152 500;
BA_ "GenMsgSendType" BO_ 2650769152 0;
BA_ "GenMsgStartDelayTime" BO_ 2650769152 316;
BA_ "CI_MsgDefinition" BO_ 2650769408 "Iveco Proprietary";
BA_ "CI_MsgId" BO_ 2650769408 37367;
BA_ "CI_MsgName" BO_ 2650769408 "PB_Telemetry24 - Proprietary B - Telemetry 24";
BA_ "GenMsgCycleTime" BO_ 2650769408 1000;
BA_ "GenMsgCycleTimeFast" BO_ 2650769408 1000;
BA_ "GenMsgDelayTime" BO_ 2650769408 500;
BA_ "GenMsgSendType" BO_ 2650769408 0;
BA_ "GenMsgStartDelayTime" BO_ 2650769408 317;
BA_ "CI_MsgDefinition" BO_ 2650769664 "Iveco Proprietary";
BA_ "CI_MsgId" BO_ 2650769664 37369;
BA_ "CI_MsgName" BO_ 2650769664 "PB_Telemetry25 - Proprietary B - Telemetry 25";
BA_ "GenMsgCycleTime" BO_ 2650769664 1000;
BA_ "GenMsgCycleTimeFast" BO_ 2650769664 1000;
BA_ "GenMsgDelayTime" BO_ 2650769664 500;
BA_ "GenMsgSendType" BO_ 2650769664 0;
BA_ "GenMsgStartDelayTime" BO_ 2650769664 318;
BA_ "CI_MsgDefinition" BO_ 2650769920 "Iveco Proprietary";
BA_ "CI_MsgId" BO_ 2650769920 37371;
BA_ "CI_MsgName" BO_ 2650769920 "PB_Telemetry26 - Proprietary B - Telemetry 26";
BA_ "GenMsgCycleTime" BO_ 2650769920 1000;
BA_ "GenMsgCycleTimeFast" BO_ 2650769920 1000;
BA_ "GenMsgDelayTime" BO_ 2650769920 500;
BA_ "GenMsgSendType" BO_ 2650769920 0;
BA_ "GenMsgStartDelayTime" BO_ 2650769920 319;
BA_ "CI_MsgDefinition" BO_ 2650770176 "Iveco Proprietary";
BA_ "CI_MsgId" BO_ 2650770176 37373;
BA_ "CI_MsgName" BO_ 2650770176 "PB_Telemetry27 - Proprietary B - Telemetry 27";
BA_ "GenMsgCycleTime" BO_ 2650770176 1000;
BA_ "GenMsgCycleTimeFast" BO_ 2650770176 1000;
BA_ "GenMsgDelayTime" BO_ 2650770176 500;
BA_ "GenMsgSendType" BO_ 2650770176 0;
BA_ "GenMsgStartDelayTime" BO_ 2650770176 321;
BA_ "CI_MsgDefinition" BO_ 2650770432 "Iveco Proprietary";
BA_ "CI_MsgId" BO_ 2650770432 37375;
BA_ "CI_MsgName" BO_ 2650770432 "PB_Telemetry28 - Proprietary B - Telemetry 28";
BA_ "GenMsgCycleTime" BO_ 2650770432 1000;
BA_ "GenMsgCycleTimeFast" BO_ 2650770432 1000;
BA_ "GenMsgDelayTime" BO_ 2650770432 500;
BA_ "GenMsgSendType" BO_ 2650770432 0;
BA_ "GenMsgStartDelayTime" BO_ 2650770432 322;
BA_ "CI_MsgDefinition" BO_ 2583640871 "Iveco Daily Electric";
BA_ "CI_MsgId" BO_ 2583640871 40408;
BA_ "CI_MsgName" BO_ 2583640871 "PB_TripInfo1_27 - Proprietary B - Trip Information 1";
BA_ "GenMsgCycleTime" BO_ 2583640871 10000;
BA_ "GenMsgCycleTimeFast" BO_ 2583640871 10000;
BA_ "GenMsgDelayTime" BO_ 2583640871 5000;
BA_ "GenMsgSendType" BO_ 2583640871 0;
BA_ "GenMsgStartDelayTime" BO_ 2583640871 361;
BA_ "CI_MsgDefinition" BO_ 2583640615 "Iveco Daily Electric";
BA_ "CI_MsgId" BO_ 2583640615 41784;
BA_ "CI_MsgName" BO_ 2583640615 "PB_TripInfo2_27 - Proprietary B - Trip Information 2";
BA_ "GenMsgCycleTime" BO_ 2583640615 10000;
BA_ "GenMsgCycleTimeFast" BO_ 2583640615 10000;
BA_ "GenMsgDelayTime" BO_ 2583640615 5000;
BA_ "GenMsgSendType" BO_ 2583640615 0;
BA_ "GenMsgStartDelayTime" BO_ 2583640615 359;
BA_ "CI_MsgDefinition" BO_ 2583636764 "Iveco Daily";
BA_ "CI_MsgId" BO_ 2583636764 44601;
BA_ "CI_MsgName" BO_ 2583636764 "PB_TSRIS_1C - Proprietary B - Traffic Sign Recognition Implicit Signs";
BA_ "GenMsgCycleTime" BO_ 2583636764 10000;
BA_ "GenMsgCycleTimeFast" BO_ 2583636764 10000;
BA_ "GenMsgDelayTime" BO_ 2583636764 5000;
BA_ "GenMsgSendType" BO_ 2583636764 0;
BA_ "GenMsgStartDelayTime" BO_ 2583636764 46;
BA_ "CI_MsgDefinition" BO_ 2566909770 "Iveco Daily Electric";
BA_ "CI_MsgId" BO_ 2566909770 44320;
BA_ "CI_MsgName" BO_ 2566909770 "PB_TXCMUDATA3_4A - PB_TXCMUDATA3";
BA_ "GenMsgCycleTime" BO_ 2566909770 100;
BA_ "GenMsgCycleTimeFast" BO_ 2566909770 50;
BA_ "GenMsgDelayTime" BO_ 2566909770 25;
BA_ "GenMsgSendType" BO_ 2566909770 0;
BA_ "GenMsgStartDelayTime" BO_ 2566909770 2;
BA_ "CI_MsgDefinition" BO_ 2566867182 "Continental Proprietary";
BA_ "CI_MsgId" BO_ 2566867182 1730;
BA_ "CI_MsgName" BO_ 2566867182 "PB_VDO1 - VDO1 (Continental Proprietary)";
BA_ "GenMsgCycleTime" BO_ 2566867182 60000;
BA_ "GenMsgCycleTimeFast" BO_ 2566867182 60000;
BA_ "GenMsgDelayTime" BO_ 2566867182 30000;
BA_ "GenMsgSendType" BO_ 2566867182 0;
BA_ "GenMsgStartDelayTime" BO_ 2566867182 365;
BA_ "CI_MsgDefinition" BO_ 2566867694 "Continental Proprietary";
BA_ "CI_MsgId" BO_ 2566867694 1762;
BA_ "CI_MsgName" BO_ 2566867694 "PB_VDO2 - VDO2 (Continental Proprietary)";
BA_ "GenMsgCycleTime" BO_ 2566867694 60000;
BA_ "GenMsgCycleTimeFast" BO_ 2566867694 60000;
BA_ "GenMsgDelayTime" BO_ 2566867694 30000;
BA_ "GenMsgSendType" BO_ 2566867694 0;
BA_ "GenMsgStartDelayTime" BO_ 2566867694 366;
BA_ "CI_MsgDefinition" BO_ 2583645991 "Iveco Daily Electric";
BA_ "CI_MsgId" BO_ 2583645991 39397;
BA_ "CI_MsgName" BO_ 2583645991 "PB_VMU2HMI_12_27 - Proprietary B - VMU2HMI_12";
BA_ "GenMsgCycleTime" BO_ 2583645991 250;
BA_ "GenMsgCycleTimeFast" BO_ 2583645991 250;
BA_ "GenMsgDelayTime" BO_ 2583645991 125;
BA_ "GenMsgSendType" BO_ 2583645991 0;
BA_ "GenMsgStartDelayTime" BO_ 2583645991 122;
BA_ "CI_MsgDefinition" BO_ 2566913319 "Iveco Daily Electric";
BA_ "CI_MsgId" BO_ 2566913319 3677;
BA_ "CI_MsgName" BO_ 2566913319 "PB_VmuInfo1_27 - Proprietary B - VMU Information 1";
BA_ "GenMsgCycleTime" BO_ 2566913319 500;
BA_ "GenMsgCycleTimeFast" BO_ 2566913319 500;
BA_ "GenMsgDelayTime" BO_ 2566913319 250;
BA_ "GenMsgSendType" BO_ 2566913319 0;
BA_ "GenMsgStartDelayTime" BO_ 2566913319 131;
BA_ "CI_ParId" SG_ 2650776967 NegRelayCounterAbove500_FFA587 "F375";
BA_ "CI_SigId" SG_ 2650776967 NegRelayCounterAbove500_FFA587 45695;
BA_ "CI_SigName" SG_ 2650776967 NegRelayCounterAbove500_FFA587 "NegRelayCounterAbove500";
BA_ "GenSigTimeoutTime_PCM" SG_ 2650776967 NegRelayCounterAbove500_FFA587 3000000;
BA_ "CI_ParId" SG_ 2650776967 PosRelayCounterAbove500_FFA587 "F374";
BA_ "CI_SigId" SG_ 2650776967 PosRelayCounterAbove500_FFA587 45694;
BA_ "CI_SigName" SG_ 2650776967 PosRelayCounterAbove500_FFA587 "PosRelayCounterAbove500";
BA_ "GenSigTimeoutTime_PCM" SG_ 2650776967 PosRelayCounterAbove500_FFA587 3000000;
BA_ "CI_ParId" SG_ 2650776967 NegRelayCounter400_500_FFA587 "F373";
BA_ "CI_SigId" SG_ 2650776967 NegRelayCounter400_500_FFA587 45693;
BA_ "CI_SigName" SG_ 2650776967 NegRelayCounter400_500_FFA587 "NegRelayCounter400_500";
BA_ "GenSigTimeoutTime_PCM" SG_ 2650776967 NegRelayCounter400_500_FFA587 3000000;
BA_ "CI_ParId" SG_ 2650776967 PosRelayCounter400_500_FFA587 "F372";
BA_ "CI_SigId" SG_ 2650776967 PosRelayCounter400_500_FFA587 45692;
BA_ "CI_SigName" SG_ 2650776967 PosRelayCounter400_500_FFA587 "PosRelayCounter400_500";
BA_ "GenSigTimeoutTime_PCM" SG_ 2650776967 PosRelayCounter400_500_FFA587 3000000;
BA_ "CI_ParId" SG_ 2650776967 NegRelayCounter250_400_FFA587 "F371";
BA_ "CI_SigId" SG_ 2650776967 NegRelayCounter250_400_FFA587 45481;
BA_ "CI_SigName" SG_ 2650776967 NegRelayCounter250_400_FFA587 "NegRelayCounter250_400";
BA_ "GenSigTimeoutTime_PCM" SG_ 2650776967 NegRelayCounter250_400_FFA587 3000000;
BA_ "CI_ParId" SG_ 2650776967 PosRelayCounter250_400_FFA587 "F370";
BA_ "CI_SigId" SG_ 2650776967 PosRelayCounter250_400_FFA587 45480;
BA_ "CI_SigName" SG_ 2650776967 PosRelayCounter250_400_FFA587 "PosRelayCounter250_400";
BA_ "GenSigTimeoutTime_PCM" SG_ 2650776967 PosRelayCounter250_400_FFA587 3000000;
BA_ "CI_ParId" SG_ 2650776967 NegRelayCounter50_250_FFA587 "F369";
BA_ "CI_SigId" SG_ 2650776967 NegRelayCounter50_250_FFA587 45479;
BA_ "CI_SigName" SG_ 2650776967 NegRelayCounter50_250_FFA587 "NegRelayCounter50_250";
BA_ "GenSigTimeoutTime_PCM" SG_ 2650776967 NegRelayCounter50_250_FFA587 3000000;
BA_ "CI_ParId" SG_ 2650776967 PosRelayCounter50_250_FFA587 "F368";
BA_ "CI_SigId" SG_ 2650776967 PosRelayCounter50_250_FFA587 45478;
BA_ "CI_SigName" SG_ 2650776967 PosRelayCounter50_250_FFA587 "PosRelayCounter50_250";
BA_ "GenSigTimeoutTime_PCM" SG_ 2650776967 PosRelayCounter50_250_FFA587 3000000;
BA_ "CI_ParId" SG_ 2650776967 NegRelayCounter_FFA587 "F367";
BA_ "CI_SigId" SG_ 2650776967 NegRelayCounter_FFA587 45477;
BA_ "CI_SigName" SG_ 2650776967 NegRelayCounter_FFA587 "NegRelayCounter";
BA_ "GenSigTimeoutTime_PCM" SG_ 2650776967 NegRelayCounter_FFA587 3000000;
BA_ "CI_ParId" SG_ 2650776967 PosRelayCounter_FFA587 "F366";
BA_ "CI_SigId" SG_ 2650776967 PosRelayCounter_FFA587 45476;
BA_ "CI_SigName" SG_ 2650776967 PosRelayCounter_FFA587 "PosRelayCounter";
BA_ "GenSigTimeoutTime_PCM" SG_ 2650776967 PosRelayCounter_FFA587 3000000;
BA_ "CI_ParId" SG_ 2650776967 PreRelayCounter_FFA587 "F365";
BA_ "CI_SigId" SG_ 2650776967 PreRelayCounter_FFA587 45475;
BA_ "CI_SigName" SG_ 2650776967 PreRelayCounter_FFA587 "PreRelayCounter";
BA_ "GenSigTimeoutTime_PCM" SG_ 2650776967 PreRelayCounter_FFA587 3000000;
BA_ "CI_ParId" SG_ 2650777076 NegRelayCounterAbove500_FFA5F4 "F375";
BA_ "CI_SigId" SG_ 2650777076 NegRelayCounterAbove500_FFA5F4 45679;
BA_ "CI_SigName" SG_ 2650777076 NegRelayCounterAbove500_FFA5F4 "NegRelayCounterAbove500";
BA_ "GenSigTimeoutTime_PCM" SG_ 2650777076 NegRelayCounterAbove500_FFA5F4 3000000;
BA_ "CI_ParId" SG_ 2650777076 PosRelayCounterAbove500_FFA5F4 "F374";
BA_ "CI_SigId" SG_ 2650777076 PosRelayCounterAbove500_FFA5F4 45678;
BA_ "CI_SigName" SG_ 2650777076 PosRelayCounterAbove500_FFA5F4 "PosRelayCounterAbove500";
BA_ "GenSigTimeoutTime_PCM" SG_ 2650777076 PosRelayCounterAbove500_FFA5F4 3000000;
BA_ "CI_ParId" SG_ 2650777076 NegRelayCounter400_500_FFA5F4 "F373";
BA_ "CI_SigId" SG_ 2650777076 NegRelayCounter400_500_FFA5F4 45677;
BA_ "CI_SigName" SG_ 2650777076 NegRelayCounter400_500_FFA5F4 "NegRelayCounter400_500";
BA_ "GenSigTimeoutTime_PCM" SG_ 2650777076 NegRelayCounter400_500_FFA5F4 3000000;
BA_ "CI_ParId" SG_ 2650777076 PosRelayCounter400_500_FFA5F4 "F372";
BA_ "CI_SigId" SG_ 2650777076 PosRelayCounter400_500_FFA5F4 45676;
BA_ "CI_SigName" SG_ 2650777076 PosRelayCounter400_500_FFA5F4 "PosRelayCounter400_500";
BA_ "GenSigTimeoutTime_PCM" SG_ 2650777076 PosRelayCounter400_500_FFA5F4 3000000;
BA_ "CI_ParId" SG_ 2650777076 NegRelayCounter250_400_FFA5F4 "F371";
BA_ "CI_SigId" SG_ 2650777076 NegRelayCounter250_400_FFA5F4 45449;
BA_ "CI_SigName" SG_ 2650777076 NegRelayCounter250_400_FFA5F4 "NegRelayCounter250_400";
BA_ "GenSigTimeoutTime_PCM" SG_ 2650777076 NegRelayCounter250_400_FFA5F4 3000000;
BA_ "CI_ParId" SG_ 2650777076 PosRelayCounter250_400_FFA5F4 "F370";
BA_ "CI_SigId" SG_ 2650777076 PosRelayCounter250_400_FFA5F4 45448;
BA_ "CI_SigName" SG_ 2650777076 PosRelayCounter250_400_FFA5F4 "PosRelayCounter250_400";
BA_ "GenSigTimeoutTime_PCM" SG_ 2650777076 PosRelayCounter250_400_FFA5F4 3000000;
BA_ "CI_ParId" SG_ 2650777076 NegRelayCounter50_250_FFA5F4 "F369";
BA_ "CI_SigId" SG_ 2650777076 NegRelayCounter50_250_FFA5F4 45447;
BA_ "CI_SigName" SG_ 2650777076 NegRelayCounter50_250_FFA5F4 "NegRelayCounter50_250";
BA_ "GenSigTimeoutTime_PCM" SG_ 2650777076 NegRelayCounter50_250_FFA5F4 3000000;
BA_ "CI_ParId" SG_ 2650777076 PosRelayCounter50_250_FFA5F4 "F368";
BA_ "CI_SigId" SG_ 2650777076 PosRelayCounter50_250_FFA5F4 45446;
BA_ "CI_SigName" SG_ 2650777076 PosRelayCounter50_250_FFA5F4 "PosRelayCounter50_250";
BA_ "GenSigTimeoutTime_PCM" SG_ 2650777076 PosRelayCounter50_250_FFA5F4 3000000;
BA_ "CI_ParId" SG_ 2650777076 NegRelayCounter_FFA5F4 "F367";
BA_ "CI_SigId" SG_ 2650777076 NegRelayCounter_FFA5F4 45445;
BA_ "CI_SigName" SG_ 2650777076 NegRelayCounter_FFA5F4 "NegRelayCounter";
BA_ "GenSigTimeoutTime_PCM" SG_ 2650777076 NegRelayCounter_FFA5F4 3000000;
BA_ "CI_ParId" SG_ 2650777076 PosRelayCounter_FFA5F4 "F366";
BA_ "CI_SigId" SG_ 2650777076 PosRelayCounter_FFA5F4 45444;
BA_ "CI_SigName" SG_ 2650777076 PosRelayCounter_FFA5F4 "PosRelayCounter";
BA_ "GenSigTimeoutTime_PCM" SG_ 2650777076 PosRelayCounter_FFA5F4 3000000;
BA_ "CI_ParId" SG_ 2650777076 PreRelayCounter_FFA5F4 "F365";
BA_ "CI_SigId" SG_ 2650777076 PreRelayCounter_FFA5F4 45443;
BA_ "CI_SigName" SG_ 2650777076 PreRelayCounter_FFA5F4 "PreRelayCounter";
BA_ "GenSigTimeoutTime_PCM" SG_ 2650777076 PreRelayCounter_FFA5F4 3000000;
BA_ "CI_ParId" SG_ 2650777077 NegRelayCounterAbove500_FFA5F5 "F375";
BA_ "CI_SigId" SG_ 2650777077 NegRelayCounterAbove500_FFA5F5 45683;
BA_ "CI_SigName" SG_ 2650777077 NegRelayCounterAbove500_FFA5F5 "NegRelayCounterAbove500";
BA_ "GenSigTimeoutTime_PCM" SG_ 2650777077 NegRelayCounterAbove500_FFA5F5 3000000;
BA_ "CI_ParId" SG_ 2650777077 PosRelayCounterAbove500_FFA5F5 "F374";
BA_ "CI_SigId" SG_ 2650777077 PosRelayCounterAbove500_FFA5F5 45682;
BA_ "CI_SigName" SG_ 2650777077 PosRelayCounterAbove500_FFA5F5 "PosRelayCounterAbove500";
BA_ "GenSigTimeoutTime_PCM" SG_ 2650777077 PosRelayCounterAbove500_FFA5F5 3000000;
BA_ "CI_ParId" SG_ 2650777077 NegRelayCounter400_500_FFA5F5 "F373";
BA_ "CI_SigId" SG_ 2650777077 NegRelayCounter400_500_FFA5F5 45681;
BA_ "CI_SigName" SG_ 2650777077 NegRelayCounter400_500_FFA5F5 "NegRelayCounter400_500";
BA_ "GenSigTimeoutTime_PCM" SG_ 2650777077 NegRelayCounter400_500_FFA5F5 3000000;
BA_ "CI_ParId" SG_ 2650777077 PosRelayCounter400_500_FFA5F5 "F372";
BA_ "CI_SigId" SG_ 2650777077 PosRelayCounter400_500_FFA5F5 45680;
BA_ "CI_SigName" SG_ 2650777077 PosRelayCounter400_500_FFA5F5 "PosRelayCounter400_500";
BA_ "GenSigTimeoutTime_PCM" SG_ 2650777077 PosRelayCounter400_500_FFA5F5 3000000;
BA_ "CI_ParId" SG_ 2650777077 NegRelayCounter250_400_FFA5F5 "F371";
BA_ "CI_SigId" SG_ 2650777077 NegRelayCounter250_400_FFA5F5 45457;
BA_ "CI_SigName" SG_ 2650777077 NegRelayCounter250_400_FFA5F5 "NegRelayCounter250_400";
BA_ "GenSigTimeoutTime_PCM" SG_ 2650777077 NegRelayCounter250_400_FFA5F5 3000000;
BA_ "CI_ParId" SG_ 2650777077 PosRelayCounter250_400_FFA5F5 "F370";
BA_ "CI_SigId" SG_ 2650777077 PosRelayCounter250_400_FFA5F5 45456;
BA_ "CI_SigName" SG_ 2650777077 PosRelayCounter250_400_FFA5F5 "PosRelayCounter250_400";
BA_ "GenSigTimeoutTime_PCM" SG_ 2650777077 PosRelayCounter250_400_FFA5F5 3000000;
BA_ "CI_ParId" SG_ 2650777077 NegRelayCounter50_250_FFA5F5 "F369";
BA_ "CI_SigId" SG_ 2650777077 NegRelayCounter50_250_FFA5F5 45455;
BA_ "CI_SigName" SG_ 2650777077 NegRelayCounter50_250_FFA5F5 "NegRelayCounter50_250";
BA_ "GenSigTimeoutTime_PCM" SG_ 2650777077 NegRelayCounter50_250_FFA5F5 3000000;
BA_ "CI_ParId" SG_ 2650777077 PosRelayCounter50_250_FFA5F5 "F368";
BA_ "CI_SigId" SG_ 2650777077 PosRelayCounter50_250_FFA5F5 45454;
BA_ "CI_SigName" SG_ 2650777077 PosRelayCounter50_250_FFA5F5 "PosRelayCounter50_250";
BA_ "GenSigTimeoutTime_PCM" SG_ 2650777077 PosRelayCounter50_250_FFA5F5 3000000;
BA_ "CI_ParId" SG_ 2650777077 NegRelayCounter_FFA5F5 "F367";
BA_ "CI_SigId" SG_ 2650777077 NegRelayCounter_FFA5F5 45453;
BA_ "CI_SigName" SG_ 2650777077 NegRelayCounter_FFA5F5 "NegRelayCounter";
BA_ "GenSigTimeoutTime_PCM" SG_ 2650777077 NegRelayCounter_FFA5F5 3000000;
BA_ "CI_ParId" SG_ 2650777077 PosRelayCounter_FFA5F5 "F366";
BA_ "CI_SigId" SG_ 2650777077 PosRelayCounter_FFA5F5 45452;
BA_ "CI_SigName" SG_ 2650777077 PosRelayCounter_FFA5F5 "PosRelayCounter";
BA_ "GenSigTimeoutTime_PCM" SG_ 2650777077 PosRelayCounter_FFA5F5 3000000;
BA_ "CI_ParId" SG_ 2650777077 PreRelayCounter_FFA5F5 "F365";
BA_ "CI_SigId" SG_ 2650777077 PreRelayCounter_FFA5F5 45451;
BA_ "CI_SigName" SG_ 2650777077 PreRelayCounter_FFA5F5 "PreRelayCounter";
BA_ "GenSigTimeoutTime_PCM" SG_ 2650777077 PreRelayCounter_FFA5F5 3000000;
BA_ "CI_ParId" SG_ 2650777078 NegRelayCounterAbove500_FFA5F6 "F375";
BA_ "CI_SigId" SG_ 2650777078 NegRelayCounterAbove500_FFA5F6 45687;
BA_ "CI_SigName" SG_ 2650777078 NegRelayCounterAbove500_FFA5F6 "NegRelayCounterAbove500";
BA_ "GenSigTimeoutTime_PCM" SG_ 2650777078 NegRelayCounterAbove500_FFA5F6 3000000;
BA_ "CI_ParId" SG_ 2650777078 PosRelayCounterAbove500_FFA5F6 "F374";
BA_ "CI_SigId" SG_ 2650777078 PosRelayCounterAbove500_FFA5F6 45686;
BA_ "CI_SigName" SG_ 2650777078 PosRelayCounterAbove500_FFA5F6 "PosRelayCounterAbove500";
BA_ "GenSigTimeoutTime_PCM" SG_ 2650777078 PosRelayCounterAbove500_FFA5F6 3000000;
BA_ "CI_ParId" SG_ 2650777078 NegRelayCounter400_500_FFA5F6 "F373";
BA_ "CI_SigId" SG_ 2650777078 NegRelayCounter400_500_FFA5F6 45685;
BA_ "CI_SigName" SG_ 2650777078 NegRelayCounter400_500_FFA5F6 "NegRelayCounter400_500";
BA_ "GenSigTimeoutTime_PCM" SG_ 2650777078 NegRelayCounter400_500_FFA5F6 3000000;
BA_ "CI_ParId" SG_ 2650777078 PosRelayCounter400_500_FFA5F6 "F372";
BA_ "CI_SigId" SG_ 2650777078 PosRelayCounter400_500_FFA5F6 45684;
BA_ "CI_SigName" SG_ 2650777078 PosRelayCounter400_500_FFA5F6 "PosRelayCounter400_500";
BA_ "GenSigTimeoutTime_PCM" SG_ 2650777078 PosRelayCounter400_500_FFA5F6 3000000;
BA_ "CI_ParId" SG_ 2650777078 NegRelayCounter250_400_FFA5F6 "F371";
BA_ "CI_SigId" SG_ 2650777078 NegRelayCounter250_400_FFA5F6 45465;
BA_ "CI_SigName" SG_ 2650777078 NegRelayCounter250_400_FFA5F6 "NegRelayCounter250_400";
BA_ "GenSigTimeoutTime_PCM" SG_ 2650777078 NegRelayCounter250_400_FFA5F6 3000000;
BA_ "CI_ParId" SG_ 2650777078 PosRelayCounter250_400_FFA5F6 "F370";
BA_ "CI_SigId" SG_ 2650777078 PosRelayCounter250_400_FFA5F6 45464;
BA_ "CI_SigName" SG_ 2650777078 PosRelayCounter250_400_FFA5F6 "PosRelayCounter250_400";
BA_ "GenSigTimeoutTime_PCM" SG_ 2650777078 PosRelayCounter250_400_FFA5F6 3000000;
BA_ "CI_ParId" SG_ 2650777078 NegRelayCounter50_250_FFA5F6 "F369";
BA_ "CI_SigId" SG_ 2650777078 NegRelayCounter50_250_FFA5F6 45463;
BA_ "CI_SigName" SG_ 2650777078 NegRelayCounter50_250_FFA5F6 "NegRelayCounter50_250";
BA_ "GenSigTimeoutTime_PCM" SG_ 2650777078 NegRelayCounter50_250_FFA5F6 3000000;
BA_ "CI_ParId" SG_ 2650777078 PosRelayCounter50_250_FFA5F6 "F368";
BA_ "CI_SigId" SG_ 2650777078 PosRelayCounter50_250_FFA5F6 45462;
BA_ "CI_SigName" SG_ 2650777078 PosRelayCounter50_250_FFA5F6 "PosRelayCounter50_250";
BA_ "GenSigTimeoutTime_PCM" SG_ 2650777078 PosRelayCounter50_250_FFA5F6 3000000;
BA_ "CI_ParId" SG_ 2650777078 NegRelayCounter_FFA5F6 "F367";
BA_ "CI_SigId" SG_ 2650777078 NegRelayCounter_FFA5F6 45461;
BA_ "CI_SigName" SG_ 2650777078 NegRelayCounter_FFA5F6 "NegRelayCounter";
BA_ "GenSigTimeoutTime_PCM" SG_ 2650777078 NegRelayCounter_FFA5F6 3000000;
BA_ "CI_ParId" SG_ 2650777078 PosRelayCounter_FFA5F6 "F366";
BA_ "CI_SigId" SG_ 2650777078 PosRelayCounter_FFA5F6 45460;
BA_ "CI_SigName" SG_ 2650777078 PosRelayCounter_FFA5F6 "PosRelayCounter";
BA_ "GenSigTimeoutTime_PCM" SG_ 2650777078 PosRelayCounter_FFA5F6 3000000;
BA_ "CI_ParId" SG_ 2650777078 PreRelayCounter_FFA5F6 "F365";
BA_ "CI_SigId" SG_ 2650777078 PreRelayCounter_FFA5F6 45459;
BA_ "CI_SigName" SG_ 2650777078 PreRelayCounter_FFA5F6 "PreRelayCounter";
BA_ "GenSigTimeoutTime_PCM" SG_ 2650777078 PreRelayCounter_FFA5F6 3000000;
BA_ "CI_ParId" SG_ 2566908199 ExtElLoadPrioFdbk "ID1511";
BA_ "CI_SigId" SG_ 2566908199 ExtElLoadPrioFdbk 35237;
BA_ "CI_SigName" SG_ 2566908199 ExtElLoadPrioFdbk "External Electrical Load Priority Feedback";
BA_ "GenSigTimeoutTime_PCM" SG_ 2566908199 ExtElLoadPrioFdbk 5000;
BA_ "SigType" SG_ 2566908199 ExtElLoadPrioFdbk 4;
BA_ "CI_ParId" SG_ 2566908199 TractModeInhFdbk "ID2590";
BA_ "CI_SigId" SG_ 2566908199 TractModeInhFdbk 45409;
BA_ "CI_SigName" SG_ 2566908199 TractModeInhFdbk "Traction Mode Inhibit Feedback";
BA_ "GenSigTimeoutTime_PCM" SG_ 2566908199 TractModeInhFdbk 5000;
BA_ "CI_ParId" SG_ 2566908199 ExtRegenBrkModeReqFdbk "ID1488";
BA_ "CI_SigId" SG_ 2566908199 ExtRegenBrkModeReqFdbk 8652;
BA_ "CI_SigName" SG_ 2566908199 ExtRegenBrkModeReqFdbk "External Regenerative Brake Mode Request Feedback";
BA_ "GenSigTimeoutTime_PCM" SG_ 2566908199 ExtRegenBrkModeReqFdbk 5000;
BA_ "SigType" SG_ 2566908199 ExtRegenBrkModeReqFdbk 4;
BA_ "CI_ParId" SG_ 2566908199 ExtTractReqFdbk "ID1485";
BA_ "CI_SigId" SG_ 2566908199 ExtTractReqFdbk 8649;
BA_ "CI_SigName" SG_ 2566908199 ExtTractReqFdbk "External Traction Request Feedback";
BA_ "GenSigTimeoutTime_PCM" SG_ 2566908199 ExtTractReqFdbk 5000;
BA_ "SigType" SG_ 2566908199 ExtTractReqFdbk 4;
BA_ "CI_ParId" SG_ 2566908199 ExtHvacReqFdbk "ID1479";
BA_ "CI_SigId" SG_ 2566908199 ExtHvacReqFdbk 8645;
BA_ "CI_SigName" SG_ 2566908199 ExtHvacReqFdbk "External HVAC Request Feedback";
BA_ "GenSigTimeoutTime_PCM" SG_ 2566908199 ExtHvacReqFdbk 5000;
BA_ "SigType" SG_ 2566908199 ExtHvacReqFdbk 4;
BA_ "CI_ParId" SG_ 2566908234 BatChgDurTime "ID1494";
BA_ "CI_SigId" SG_ 2566908234 BatChgDurTime 8636;
BA_ "CI_SigName" SG_ 2566908234 BatChgDurTime "Battery Charging Duration Time";
BA_ "CI_ParId" SG_ 2566908234 ExtBatChgReq "ID1493";
BA_ "CI_SigId" SG_ 2566908234 ExtBatChgReq 8634;
BA_ "CI_SigName" SG_ 2566908234 ExtBatChgReq "External Battery Charging Request";
BA_ "SigType" SG_ 2566908234 ExtBatChgReq 4;
BA_ "CI_ParId" SG_ 2566908234 FmsRegenBrkModeReq "ID1487";
BA_ "CI_SigId" SG_ 2566908234 FmsRegenBrkModeReq 8632;
BA_ "CI_SigName" SG_ 2566908234 FmsRegenBrkModeReq "FMS Regenerative Brake Mode Request";
BA_ "CI_ParId" SG_ 2566908234 FmsExtTractModeReq "ID1484";
BA_ "CI_SigId" SG_ 2566908234 FmsExtTractModeReq 8629;
BA_ "CI_SigName" SG_ 2566908234 FmsExtTractModeReq "FMS External Traction Mode Request";
BA_ "CI_ParId" SG_ 2566908234 FmsHvacWorkMode "ID1478";
BA_ "CI_SigId" SG_ 2566908234 FmsHvacWorkMode 8625;
BA_ "CI_SigName" SG_ 2566908234 FmsHvacWorkMode "FMS HVAC Working Mode";
BA_ "GenSigStartValue" SG_ 2566908234 FmsHvacWorkMode 3;
BA_ "SigType" SG_ 2566908234 FmsHvacWorkMode 4;
BA_ "CI_ParId" SG_ 2566908234 ExtHvacReq "ID1477";
BA_ "CI_SigId" SG_ 2566908234 ExtHvacReq 8624;
BA_ "CI_SigName" SG_ 2566908234 ExtHvacReq "External HVAC Request";
BA_ "CI_ParId" SG_ 2583664714 PosLightCtrl "ID2509";
BA_ "CI_SigId" SG_ 2583664714 PosLightCtrl 44724;
BA_ "CI_SigName" SG_ 2583664714 PosLightCtrl "Position Lights Control";
BA_ "SigType" SG_ 2583664714 PosLightCtrl 4;
BA_ "CI_ParId" SG_ 2583664714 LowBeamLightCtrl "ID2508";
BA_ "CI_SigId" SG_ 2583664714 LowBeamLightCtrl 44723;
BA_ "CI_SigName" SG_ 2583664714 LowBeamLightCtrl "Low Beam Light Control";
BA_ "SigType" SG_ 2583664714 LowBeamLightCtrl 4;
BA_ "CI_ParId" SG_ 2583664714 RearCeilLight_FF984A "ID2507";
BA_ "CI_SigId" SG_ 2583664714 RearCeilLight_FF984A 44722;
BA_ "CI_SigName" SG_ 2583664714 RearCeilLight_FF984A "Rear Ceiling Light";
BA_ "SigType" SG_ 2583664714 RearCeilLight_FF984A 4;
BA_ "CI_ParId" SG_ 2583664714 CentCeilLight_FF984A "ID2506";
BA_ "CI_SigId" SG_ 2583664714 CentCeilLight_FF984A 44721;
BA_ "CI_SigName" SG_ 2583664714 CentCeilLight_FF984A "Central Ceiling Light";
BA_ "SigType" SG_ 2583664714 CentCeilLight_FF984A 4;
BA_ "CI_ParId" SG_ 2583664714 LatRightCeilLight_FF984A "ID2505";
BA_ "CI_SigId" SG_ 2583664714 LatRightCeilLight_FF984A 44720;
BA_ "CI_SigName" SG_ 2583664714 LatRightCeilLight_FF984A "Lateral Right Ceiling Light";
BA_ "SigType" SG_ 2583664714 LatRightCeilLight_FF984A 4;
BA_ "CI_ParId" SG_ 2583664714 LatLeftCeilLight_FF984A "ID2504";
BA_ "CI_SigId" SG_ 2583664714 LatLeftCeilLight_FF984A 44719;
BA_ "CI_SigName" SG_ 2583664714 LatLeftCeilLight_FF984A "Lateral Left Ceiling Light";
BA_ "SigType" SG_ 2583664714 LatLeftCeilLight_FF984A 4;
BA_ "CI_ParId" SG_ 2583664714 FrontCeilLight_FF984A "ID2503";
BA_ "CI_SigId" SG_ 2583664714 FrontCeilLight_FF984A 44718;
BA_ "CI_SigName" SG_ 2583664714 FrontCeilLight_FF984A "Front Ceiling Light";
BA_ "SigType" SG_ 2583664714 FrontCeilLight_FF984A 4;
BA_ "CI_ParId" SG_ 2583664714 EcoMode_FF984A "ID2502";
BA_ "CI_SigId" SG_ 2583664714 EcoMode_FF984A 44717;
BA_ "CI_SigName" SG_ 2583664714 EcoMode_FF984A "Eco Mode";
BA_ "SigType" SG_ 2583664714 EcoMode_FF984A 4;
BA_ "CI_ParId" SG_ 2583664714 EcoHiMatic "ID2501";
BA_ "CI_SigId" SG_ 2583664714 EcoHiMatic 44716;
BA_ "CI_SigName" SG_ 2583664714 EcoHiMatic "Eco Hi Matic";
BA_ "SigType" SG_ 2583664714 EcoHiMatic 4;
BA_ "CI_ParId" SG_ 2566896409 EacPwrLim "Sa003";
BA_ "CI_SigId" SG_ 2566896409 EacPwrLim 8925;
BA_ "CI_SigName" SG_ 2566896409 EacPwrLim "Electric Air Compressor Power Limitation";
BA_ "GenSigSendType" SG_ 2566896409 EacPwrLim 3;
BA_ "GenSigTimeoutTime_PCM" SG_ 2566896409 EacPwrLim 5000;
BA_ "SigType" SG_ 2566896409 EacPwrLim 1;
BA_ "CI_ParId" SG_ 2566896409 EacCtrlMode "Sa002";
BA_ "CI_SigId" SG_ 2566896409 EacCtrlMode 8924;
BA_ "CI_SigName" SG_ 2566896409 EacCtrlMode "Electric Air Compressor Control Mode";
BA_ "GenSigSendType" SG_ 2566896409 EacCtrlMode 3;
BA_ "GenSigTimeoutTime_PCM" SG_ 2566896409 EacCtrlMode 5000;
BA_ "SigType" SG_ 2566896409 EacCtrlMode 4;
BA_ "CI_ParId" SG_ 2566896409 EacSpeed "Sa001";
BA_ "CI_SigId" SG_ 2566896409 EacSpeed 8923;
BA_ "CI_SigName" SG_ 2566896409 EacSpeed "Electric Air Compressor Speed";
BA_ "GenSigSendType" SG_ 2566896409 EacSpeed 3;
BA_ "GenSigTimeoutTime_PCM" SG_ 2566896409 EacSpeed 5000;
BA_ "SigType" SG_ 2566896409 EacSpeed 1;
BA_ "CI_ParId" SG_ 2566897046 EacPhaseCur "Sa008";
BA_ "CI_SigId" SG_ 2566897046 EacPhaseCur 8932;
BA_ "CI_SigName" SG_ 2566897046 EacPhaseCur "Electric Air Compressor Phase Current";
BA_ "GenSigTimeoutTime_PCM" SG_ 2566897046 EacPhaseCur 5000;
BA_ "SigType" SG_ 2566897046 EacPhaseCur 1;
BA_ "CI_ParId" SG_ 2566897046 EacInvTemp "Sa007";
BA_ "CI_SigId" SG_ 2566897046 EacInvTemp 8931;
BA_ "CI_SigName" SG_ 2566897046 EacInvTemp "Electric Air Compressor Inverter Temperature";
BA_ "GenSigInactiveValue" SG_ 2566897046 EacInvTemp 50;
BA_ "GenSigTimeoutTime_PCM" SG_ 2566897046 EacInvTemp 5000;
BA_ "SigType" SG_ 2566897046 EacInvTemp 1;
BA_ "CI_ParId" SG_ 2566897046 EacInCur "Sa006";
BA_ "CI_SigId" SG_ 2566897046 EacInCur 8930;
BA_ "CI_SigName" SG_ 2566897046 EacInCur "Electric Air Compressor Input Current";
BA_ "GenSigTimeoutTime_PCM" SG_ 2566897046 EacInCur 5000;
BA_ "SigType" SG_ 2566897046 EacInCur 1;
BA_ "CI_ParId" SG_ 2566897046 EacInV "Sa005";
BA_ "CI_SigId" SG_ 2566897046 EacInV 8929;
BA_ "CI_SigName" SG_ 2566897046 EacInV "Electric Air Compressor Input Voltage";
BA_ "GenSigTimeoutTime_PCM" SG_ 2566897046 EacInV 5000;
BA_ "SigType" SG_ 2566897046 EacInV 1;
BA_ "CI_ParId" SG_ 2566897046 EacSts "Sa004";
BA_ "CI_SigId" SG_ 2566897046 EacSts 8928;
BA_ "CI_SigName" SG_ 2566897046 EacSts "Electric Air Compressor Status";
BA_ "GenSigTimeoutTime_PCM" SG_ 2566897046 EacSts 5000;
BA_ "CI_ParId" SG_ 2566897046 EacSpeed_FFBD96 "Sa001";
BA_ "CI_SigId" SG_ 2566897046 EacSpeed_FFBD96 8927;
BA_ "CI_SigName" SG_ 2566897046 EacSpeed_FFBD96 "Electric Air Compressor Speed";
BA_ "GenSigTimeoutTime_PCM" SG_ 2566897046 EacSpeed_FFBD96 5000;
BA_ "SigType" SG_ 2566897046 EacSpeed_FFBD96 1;
BA_ "CI_ParId" SG_ 2566886218 EcallSts "ID2566";
BA_ "CI_SigId" SG_ 2566886218 EcallSts 45134;
BA_ "CI_SigName" SG_ 2566886218 EcallSts "eCALL Status";
BA_ "GenSigSendType" SG_ 2566886218 EcallSts 3;
BA_ "GenSigTimeoutTime_SGW" SG_ 2566886218 EcallSts 5000;
BA_ "CI_ParId" SG_ 2566886227 SrsCfg "ID2363";
BA_ "CI_SigId" SG_ 2566886227 SrsCfg 43103;
BA_ "CI_SigName" SG_ 2566886227 SrsCfg "SRS Configuration";
BA_ "GenSigTimeoutTime_PCM" SG_ 2566886227 SrsCfg 1250;
BA_ "SigType" SG_ 2566886227 SrsCfg 4;
BA_ "CI_ParId" SG_ 2566886227 AirbagFail "ID2362";
BA_ "CI_SigId" SG_ 2566886227 AirbagFail 43102;
BA_ "CI_SigName" SG_ 2566886227 AirbagFail "Airbag Fail status";
BA_ "GenSigTimeoutTime_PCM" SG_ 2566886227 AirbagFail 1250;
BA_ "SigType" SG_ 2566886227 AirbagFail 4;
BA_ "CI_ParId" SG_ 2566886227 AllAirbagsSts "ID2365";
BA_ "CI_SigId" SG_ 2566886227 AllAirbagsSts 43101;
BA_ "CI_SigName" SG_ 2566886227 AllAirbagsSts "All Airbags Status";
BA_ "GenSigTimeoutTime_PCM" SG_ 2566886227 AllAirbagsSts 1250;
BA_ "SigType" SG_ 2566886227 AllAirbagsSts 4;
BA_ "CI_ParId" SG_ 2566886227 PassAirbagSts "ID2364";
BA_ "CI_SigId" SG_ 2566886227 PassAirbagSts 43100;
BA_ "CI_SigName" SG_ 2566886227 PassAirbagSts "Passenger Airbag Status";
BA_ "GenSigTimeoutTime_PCM" SG_ 2566886227 PassAirbagSts 1250;
BA_ "SigType" SG_ 2566886227 PassAirbagSts 4;
BA_ "CI_ParId" SG_ 2566886227 CrashOutSts_FF9353 "ID0254";
BA_ "CI_SigId" SG_ 2566886227 CrashOutSts_FF9353 43099;
BA_ "CI_SigName" SG_ 2566886227 CrashOutSts_FF9353 "Crash Output Status";
BA_ "GenSigTimeoutTime_PCM" SG_ 2566886227 CrashOutSts_FF9353 1250;
BA_ "CI_ParId" SG_ 2566886227 FuelCutoffInd "ID2401";
BA_ "CI_SigId" SG_ 2566886227 FuelCutoffInd 43962;
BA_ "CI_SigName" SG_ 2566886227 FuelCutoffInd "Fuel CutOff Indication";
BA_ "GenSigTimeoutTime_PCM" SG_ 2566886227 FuelCutoffInd 1250;
BA_ "SigType" SG_ 2566886227 FuelCutoffInd 4;
BA_ "CI_ParId" SG_ 2583669789 SevAnomalyInBlk2 "IMH0064";
BA_ "CI_SigId" SG_ 2583669789 SevAnomalyInBlk2 45130;
BA_ "CI_SigName" SG_ 2583669789 SevAnomalyInBlk2 "Severe anomaly in Block 2";
BA_ "SigType" SG_ 2583669789 SevAnomalyInBlk2 4;
BA_ "CI_ParId" SG_ 2583669789 SevAnomalyInBlk1 "IMH0063";
BA_ "CI_SigId" SG_ 2583669789 SevAnomalyInBlk1 45129;
BA_ "CI_SigName" SG_ 2583669789 SevAnomalyInBlk1 "Severe anomaly in Block 1";
BA_ "SigType" SG_ 2583669789 SevAnomalyInBlk1 4;
BA_ "CI_ParId" SG_ 2583669789 Blk2Full "IMH0062";
BA_ "CI_SigId" SG_ 2583669789 Blk2Full 45128;
BA_ "CI_SigName" SG_ 2583669789 Blk2Full "Block 2 full";
BA_ "SigType" SG_ 2583669789 Blk2Full 4;
BA_ "CI_ParId" SG_ 2583669789 Blk1Full "IMH0061";
BA_ "CI_SigId" SG_ 2583669789 Blk1Full 45127;
BA_ "CI_SigName" SG_ 2583669789 Blk1Full "Block 1 full";
BA_ "SigType" SG_ 2583669789 Blk1Full 4;
BA_ "CI_ParId" SG_ 2583669834 WarnRx "IMH0065";
BA_ "CI_SigId" SG_ 2583669834 WarnRx 45132;
BA_ "CI_SigName" SG_ 2583669834 WarnRx "Warning Received";
BA_ "SigType" SG_ 2583669834 WarnRx 4;
BA_ "CI_ParId" SG_ 2650775319 MaxChgCurLim "ID2090";
BA_ "CI_SigId" SG_ 2650775319 MaxChgCurLim 40427;
BA_ "CI_SigName" SG_ 2650775319 MaxChgCurLim "Max Charge Current Limit";
BA_ "GenSigTimeoutTime_PCM" SG_ 2650775319 MaxChgCurLim 5000;
BA_ "CI_ParId" SG_ 2650775319 DseNotificationSet "ID2591";
BA_ "CI_SigId" SG_ 2650775319 DseNotificationSet 45410;
BA_ "CI_SigName" SG_ 2650775319 DseNotificationSet "DSE Notification Setting";
BA_ "GenSigTimeoutTime_PCM" SG_ 2650775319 DseNotificationSet 5000;
BA_ "SigType" SG_ 2650775319 DseNotificationSet 4;
BA_ "CI_ParId" SG_ 2650775319 EptoMenuWaitingMode "ID2093";
BA_ "CI_SigId" SG_ 2650775319 EptoMenuWaitingMode 40426;
BA_ "CI_SigName" SG_ 2650775319 EptoMenuWaitingMode "ePTO Menu Waiting Mode";
BA_ "GenSigTimeoutTime_PCM" SG_ 2650775319 EptoMenuWaitingMode 5000;
BA_ "SigType" SG_ 2650775319 EptoMenuWaitingMode 4;
BA_ "CI_ParId" SG_ 2650775319 ChgPlugLck_UnlckAtEndOfChg "ID2089";
BA_ "CI_SigId" SG_ 2650775319 ChgPlugLck_UnlckAtEndOfChg 40424;
BA_ "CI_SigName" SG_ 2650775319 ChgPlugLck_UnlckAtEndOfChg "Charging plug Lock/Unlock at end of charge";
BA_ "GenSigTimeoutTime_PCM" SG_ 2650775319 ChgPlugLck_UnlckAtEndOfChg 5000;
BA_ "SigType" SG_ 2650775319 ChgPlugLck_UnlckAtEndOfChg 4;
BA_ "CI_ParId" SG_ 2650775319 MaxSocForEndOfChg "ID2094";
BA_ "CI_SigId" SG_ 2650775319 MaxSocForEndOfChg 40423;
BA_ "CI_SigName" SG_ 2650775319 MaxSocForEndOfChg "Max SOC for End of Charge";
BA_ "GenSigTimeoutTime_PCM" SG_ 2650775319 MaxSocForEndOfChg 5000;
BA_ "SigType" SG_ 2650775319 MaxSocForEndOfChg 1;
BA_ "CI_ParId" SG_ 2650775319 MinSocUtilitiesDisconn "ID2092";
BA_ "CI_SigId" SG_ 2650775319 MinSocUtilitiesDisconn 40422;
BA_ "CI_SigName" SG_ 2650775319 MinSocUtilitiesDisconn "Minimum SOC Utilities disconnection";
BA_ "GenSigTimeoutTime_PCM" SG_ 2650775319 MinSocUtilitiesDisconn 5000;
BA_ "SigType" SG_ 2650775319 MinSocUtilitiesDisconn 1;
BA_ "CI_ParId" SG_ 2650775319 ElLoadPrioPc "ID1547";
BA_ "CI_SigId" SG_ 2650775319 ElLoadPrioPc 36880;
BA_ "CI_SigName" SG_ 2650775319 ElLoadPrioPc "Electrical Load Priority Percent";
BA_ "GenSigTimeoutTime_PCM" SG_ 2650775319 ElLoadPrioPc 5000;
BA_ "SigType" SG_ 2650775319 ElLoadPrioPc 1;
BA_ "CI_ParId" SG_ 2650775335 ElLoadPrioPc_FF9F27 "ID1547";
BA_ "CI_SigId" SG_ 2650775335 ElLoadPrioPc_FF9F27 41808;
BA_ "CI_SigName" SG_ 2650775335 ElLoadPrioPc_FF9F27 "Electrical Load Priority Percent";
BA_ "GenSigTimeoutTime_PCM" SG_ 2650775335 ElLoadPrioPc_FF9F27 5000;
BA_ "SigType" SG_ 2650775335 ElLoadPrioPc_FF9F27 1;
BA_ "CI_ParId" SG_ 2650775370 ZZS_24_1DFF9F4A "ID2089";
BA_ "CI_SigId" SG_ 2650775370 ZZS_24_1DFF9F4A 41086;
BA_ "CI_SigName" SG_ 2650775370 ZZS_24_1DFF9F4A "Charging plug Lock/Unlock at end of charge";
BA_ "GenSigTimeoutTime_SGW" SG_ 2650775370 ZZS_24_1DFF9F4A 5000;
BA_ "SigType" SG_ 2650775370 ZZS_24_1DFF9F4A 4;
BA_ "CI_ParId" SG_ 2650775370 ElLoadPrioPc_FF9F4A "ID1547";
BA_ "CI_SigId" SG_ 2650775370 ElLoadPrioPc_FF9F4A 36882;
BA_ "CI_SigName" SG_ 2650775370 ElLoadPrioPc_FF9F4A "Electrical Load Priority Percent";
BA_ "GenSigTimeoutTime_SGW" SG_ 2650775370 ElLoadPrioPc_FF9F4A 5000;
BA_ "SigType" SG_ 2650775370 ElLoadPrioPc_FF9F4A 1;
BA_ "CI_ParId" SG_ 2583678231 EngStartStopMenuSet "ID2532";
BA_ "CI_SigId" SG_ 2583678231 EngStartStopMenuSet 44773;
BA_ "CI_SigName" SG_ 2583678231 EngStartStopMenuSet "Engine Start Stop Menu Setting";
BA_ "GenSigSendType" SG_ 2583678231 EngStartStopMenuSet 3;
BA_ "GenSigTimeoutTime_PCM" SG_ 2583678231 EngStartStopMenuSet 5000;
BA_ "SigType" SG_ 2583678231 EngStartStopMenuSet 4;
BA_ "CI_ParId" SG_ 2583678231 MenuAutoLckTimer2 "ID2534";
BA_ "CI_SigId" SG_ 2583678231 MenuAutoLckTimer2 44785;
BA_ "CI_SigName" SG_ 2583678231 MenuAutoLckTimer2 "Menu Auto Lock Timer 2";
BA_ "GenSigSendType" SG_ 2583678231 MenuAutoLckTimer2 3;
BA_ "GenSigTimeoutTime_PCM" SG_ 2583678231 MenuAutoLckTimer2 5000;
BA_ "SigType" SG_ 2583678231 MenuAutoLckTimer2 1;
BA_ "CI_ParId" SG_ 2583678231 MenuAutoLckTimer1 "ID2533";
BA_ "CI_SigId" SG_ 2583678231 MenuAutoLckTimer1 44784;
BA_ "CI_SigName" SG_ 2583678231 MenuAutoLckTimer1 "Menu Auto Lock Timer 1";
BA_ "GenSigSendType" SG_ 2583678231 MenuAutoLckTimer1 3;
BA_ "GenSigTimeoutTime_PCM" SG_ 2583678231 MenuAutoLckTimer1 5000;
BA_ "SigType" SG_ 2583678231 MenuAutoLckTimer1 1;
BA_ "CI_ParId" SG_ 2583678231 MenuSelDistReq "ID1537";
BA_ "CI_SigId" SG_ 2583678231 MenuSelDistReq 35410;
BA_ "CI_SigName" SG_ 2583678231 MenuSelDistReq "Menu Selection Distance Request";
BA_ "GenSigSendType" SG_ 2583678231 MenuSelDistReq 3;
BA_ "GenSigTimeoutTime_PCM" SG_ 2583678231 MenuSelDistReq 5000;
BA_ "CI_ParId" SG_ 2583678231 MenuWelcomeLightReq "ID1539";
BA_ "CI_SigId" SG_ 2583678231 MenuWelcomeLightReq 35408;
BA_ "CI_SigName" SG_ 2583678231 MenuWelcomeLightReq "Menu Welcome Light Request";
BA_ "GenSigSendType" SG_ 2583678231 MenuWelcomeLightReq 3;
BA_ "GenSigTimeoutTime_PCM" SG_ 2583678231 MenuWelcomeLightReq 5000;
BA_ "SigType" SG_ 2583678231 MenuWelcomeLightReq 4;
BA_ "CI_ParId" SG_ 2583678231 MenuKeylessEntry "ID1538";
BA_ "CI_SigId" SG_ 2583678231 MenuKeylessEntry 35407;
BA_ "CI_SigName" SG_ 2583678231 MenuKeylessEntry "Menu Keyless Entry";
BA_ "GenSigSendType" SG_ 2583678231 MenuKeylessEntry 3;
BA_ "GenSigTimeoutTime_PCM" SG_ 2583678231 MenuKeylessEntry 5000;
BA_ "SigType" SG_ 2583678231 MenuKeylessEntry 4;
BA_ "CI_ParId" SG_ 2583678231 MenuSelUnlckSound "ID1536";
BA_ "CI_SigId" SG_ 2583678231 MenuSelUnlckSound 35406;
BA_ "CI_SigName" SG_ 2583678231 MenuSelUnlckSound "Menu Selection Unlock Sound";
BA_ "GenSigSendType" SG_ 2583678231 MenuSelUnlckSound 3;
BA_ "GenSigTimeoutTime_PCM" SG_ 2583678231 MenuSelUnlckSound 5000;
BA_ "SigType" SG_ 2583678231 MenuSelUnlckSound 4;
BA_ "CI_ParId" SG_ 2583678231 MenuSelLckSound "ID1535";
BA_ "CI_SigId" SG_ 2583678231 MenuSelLckSound 35405;
BA_ "CI_SigName" SG_ 2583678231 MenuSelLckSound "Menu Selection Lock Sound";
BA_ "GenSigSendType" SG_ 2583678231 MenuSelLckSound 3;
BA_ "GenSigTimeoutTime_PCM" SG_ 2583678231 MenuSelLckSound 5000;
BA_ "SigType" SG_ 2583678231 MenuSelLckSound 4;
BA_ "CI_ParId" SG_ 2583678231 MenuSelUnlckMode "ID1534";
BA_ "CI_SigId" SG_ 2583678231 MenuSelUnlckMode 35404;
BA_ "CI_SigName" SG_ 2583678231 MenuSelUnlckMode "Menu Selection Unlock Mode";
BA_ "GenSigSendType" SG_ 2583678231 MenuSelUnlckMode 3;
BA_ "GenSigTimeoutTime_PCM" SG_ 2583678231 MenuSelUnlckMode 5000;
BA_ "SigType" SG_ 2583678231 MenuSelUnlckMode 4;
BA_ "CI_ParId" SG_ 2583678241 IgnShutdnTimer "ID1550";
BA_ "CI_SigId" SG_ 2583678241 IgnShutdnTimer 44772;
BA_ "CI_SigName" SG_ 2583678241 IgnShutdnTimer "Ignition Shutdown Timer";
BA_ "GenSigSendType" SG_ 2583678241 IgnShutdnTimer 3;
BA_ "GenSigTimeoutTime_PCM" SG_ 2583678241 IgnShutdnTimer 5000;
BA_ "SigType" SG_ 2583678241 IgnShutdnTimer 1;
BA_ "CI_ParId" SG_ 2650777734 MaxIntervalViolation "MV043";
BA_ "CI_SigId" SG_ 2650777734 MaxIntervalViolation 44204;
BA_ "CI_SigName" SG_ 2650777734 MaxIntervalViolation "MaxIntervalViolation";
BA_ "GenSigTimeoutTime_PCM" SG_ 2650777734 MaxIntervalViolation 3000000;
BA_ "CI_ParId" SG_ 2650777734 StgBelowNeg30_h "MV042";
BA_ "CI_SigId" SG_ 2650777734 StgBelowNeg30_h 44203;
BA_ "CI_SigName" SG_ 2650777734 StgBelowNeg30_h "StgBelowNeg30_h";
BA_ "GenSigTimeoutTime_PCM" SG_ 2650777734 StgBelowNeg30_h 3000000;
BA_ "SigType" SG_ 2650777734 StgBelowNeg30_h 1;
BA_ "CI_ParId" SG_ 2650777734 StgBelowNeg20_h "MV041";
BA_ "CI_SigId" SG_ 2650777734 StgBelowNeg20_h 44202;
BA_ "CI_SigName" SG_ 2650777734 StgBelowNeg20_h "StgBelowNeg20_h";
BA_ "GenSigTimeoutTime_PCM" SG_ 2650777734 StgBelowNeg20_h 3000000;
BA_ "SigType" SG_ 2650777734 StgBelowNeg20_h 1;
BA_ "CI_ParId" SG_ 2650777734 StgBelowNeg10_h "MV040";
BA_ "CI_SigId" SG_ 2650777734 StgBelowNeg10_h 44201;
BA_ "CI_SigName" SG_ 2650777734 StgBelowNeg10_h "StgBelowNeg10_h";
BA_ "GenSigTimeoutTime_PCM" SG_ 2650777734 StgBelowNeg10_h 3000000;
BA_ "SigType" SG_ 2650777734 StgBelowNeg10_h 1;
BA_ "CI_ParId" SG_ 2650777734 StgBelow0_h "MV039";
BA_ "CI_SigId" SG_ 2650777734 StgBelow0_h 44200;
BA_ "CI_SigName" SG_ 2650777734 StgBelow0_h "StgBelow0_h";
BA_ "GenSigTimeoutTime_PCM" SG_ 2650777734 StgBelow0_h 3000000;
BA_ "SigType" SG_ 2650777734 StgBelow0_h 1;
BA_ "CI_ParId" SG_ 2650777734 StgOver0_h "MV038";
BA_ "CI_SigId" SG_ 2650777734 StgOver0_h 44199;
BA_ "CI_SigName" SG_ 2650777734 StgOver0_h "StgOver0_h";
BA_ "GenSigTimeoutTime_PCM" SG_ 2650777734 StgOver0_h 3000000;
BA_ "SigType" SG_ 2650777734 StgOver0_h 1;
BA_ "CI_ParId" SG_ 2650777734 StgOver15_h "MV037";
BA_ "CI_SigId" SG_ 2650777734 StgOver15_h 44198;
BA_ "CI_SigName" SG_ 2650777734 StgOver15_h "StgOver15_h";
BA_ "GenSigTimeoutTime_PCM" SG_ 2650777734 StgOver15_h 3000000;
BA_ "SigType" SG_ 2650777734 StgOver15_h 1;
BA_ "CI_ParId" SG_ 2650777734 StgOver30_h "MV036";
BA_ "CI_SigId" SG_ 2650777734 StgOver30_h 44197;
BA_ "CI_SigName" SG_ 2650777734 StgOver30_h "StgOver30_h";
BA_ "GenSigTimeoutTime_PCM" SG_ 2650777734 StgOver30_h 3000000;
BA_ "SigType" SG_ 2650777734 StgOver30_h 1;
BA_ "CI_ParId" SG_ 2650777734 StgOver35_h "MV035";
BA_ "CI_SigId" SG_ 2650777734 StgOver35_h 44196;
BA_ "CI_SigName" SG_ 2650777734 StgOver35_h "StgOver35_h";
BA_ "GenSigTimeoutTime_PCM" SG_ 2650777734 StgOver35_h 3000000;
BA_ "SigType" SG_ 2650777734 StgOver35_h 1;
BA_ "CI_ParId" SG_ 2650777734 StgOver40_h "MV034";
BA_ "CI_SigId" SG_ 2650777734 StgOver40_h 44195;
BA_ "CI_SigName" SG_ 2650777734 StgOver40_h "StgOver40_h";
BA_ "GenSigTimeoutTime_PCM" SG_ 2650777734 StgOver40_h 3000000;
BA_ "SigType" SG_ 2650777734 StgOver40_h 1;
BA_ "CI_ParId" SG_ 2650777734 StgOver45_h "MV033";
BA_ "CI_SigId" SG_ 2650777734 StgOver45_h 44194;
BA_ "CI_SigName" SG_ 2650777734 StgOver45_h "StgOver45_h";
BA_ "GenSigTimeoutTime_PCM" SG_ 2650777734 StgOver45_h 3000000;
BA_ "SigType" SG_ 2650777734 StgOver45_h 1;
BA_ "CI_ParId" SG_ 2650777734 StgOver55_h "MV032";
BA_ "CI_SigId" SG_ 2650777734 StgOver55_h 44193;
BA_ "CI_SigName" SG_ 2650777734 StgOver55_h "StgOver55_h";
BA_ "GenSigTimeoutTime_PCM" SG_ 2650777734 StgOver55_h 3000000;
BA_ "SigType" SG_ 2650777734 StgOver55_h 1;
BA_ "CI_ParId" SG_ 2650777735 MaxIntervalViolation_FFA887 "MV043";
BA_ "CI_SigId" SG_ 2650777735 MaxIntervalViolation_FFA887 44217;
BA_ "CI_SigName" SG_ 2650777735 MaxIntervalViolation_FFA887 "MaxIntervalViolation";
BA_ "GenSigTimeoutTime_PCM" SG_ 2650777735 MaxIntervalViolation_FFA887 3000000;
BA_ "CI_ParId" SG_ 2650777735 StgBelowNeg30_h_FFA887 "MV042";
BA_ "CI_SigId" SG_ 2650777735 StgBelowNeg30_h_FFA887 44216;
BA_ "CI_SigName" SG_ 2650777735 StgBelowNeg30_h_FFA887 "StgBelowNeg30_h";
BA_ "GenSigTimeoutTime_PCM" SG_ 2650777735 StgBelowNeg30_h_FFA887 3000000;
BA_ "SigType" SG_ 2650777735 StgBelowNeg30_h_FFA887 1;
BA_ "CI_ParId" SG_ 2650777735 StgBelowNeg20_h_FFA887 "MV041";
BA_ "CI_SigId" SG_ 2650777735 StgBelowNeg20_h_FFA887 44215;
BA_ "CI_SigName" SG_ 2650777735 StgBelowNeg20_h_FFA887 "StgBelowNeg20_h";
BA_ "GenSigTimeoutTime_PCM" SG_ 2650777735 StgBelowNeg20_h_FFA887 3000000;
BA_ "SigType" SG_ 2650777735 StgBelowNeg20_h_FFA887 1;
BA_ "CI_ParId" SG_ 2650777735 StgBelowNeg10_h_FFA887 "MV040";
BA_ "CI_SigId" SG_ 2650777735 StgBelowNeg10_h_FFA887 44214;
BA_ "CI_SigName" SG_ 2650777735 StgBelowNeg10_h_FFA887 "StgBelowNeg10_h";
BA_ "GenSigTimeoutTime_PCM" SG_ 2650777735 StgBelowNeg10_h_FFA887 3000000;
BA_ "SigType" SG_ 2650777735 StgBelowNeg10_h_FFA887 1;
BA_ "CI_ParId" SG_ 2650777735 StgBelow0_h_FFA887 "MV039";
BA_ "CI_SigId" SG_ 2650777735 StgBelow0_h_FFA887 44213;
BA_ "CI_SigName" SG_ 2650777735 StgBelow0_h_FFA887 "StgBelow0_h";
BA_ "GenSigTimeoutTime_PCM" SG_ 2650777735 StgBelow0_h_FFA887 3000000;
BA_ "SigType" SG_ 2650777735 StgBelow0_h_FFA887 1;
BA_ "CI_ParId" SG_ 2650777735 StgOver0_h_FFA887 "MV038";
BA_ "CI_SigId" SG_ 2650777735 StgOver0_h_FFA887 44212;
BA_ "CI_SigName" SG_ 2650777735 StgOver0_h_FFA887 "StgOver0_h";
BA_ "GenSigTimeoutTime_PCM" SG_ 2650777735 StgOver0_h_FFA887 3000000;
BA_ "SigType" SG_ 2650777735 StgOver0_h_FFA887 1;
BA_ "CI_ParId" SG_ 2650777735 StgOver15_h_FFA887 "MV037";
BA_ "CI_SigId" SG_ 2650777735 StgOver15_h_FFA887 44211;
BA_ "CI_SigName" SG_ 2650777735 StgOver15_h_FFA887 "StgOver15_h";
BA_ "GenSigTimeoutTime_PCM" SG_ 2650777735 StgOver15_h_FFA887 3000000;
BA_ "SigType" SG_ 2650777735 StgOver15_h_FFA887 1;
BA_ "CI_ParId" SG_ 2650777735 StgOver30_h_FFA887 "MV036";
BA_ "CI_SigId" SG_ 2650777735 StgOver30_h_FFA887 44210;
BA_ "CI_SigName" SG_ 2650777735 StgOver30_h_FFA887 "StgOver30_h";
BA_ "GenSigTimeoutTime_PCM" SG_ 2650777735 StgOver30_h_FFA887 3000000;
BA_ "SigType" SG_ 2650777735 StgOver30_h_FFA887 1;
BA_ "CI_ParId" SG_ 2650777735 StgOver35_h_FFA887 "MV035";
BA_ "CI_SigId" SG_ 2650777735 StgOver35_h_FFA887 44209;
BA_ "CI_SigName" SG_ 2650777735 StgOver35_h_FFA887 "StgOver35_h";
BA_ "GenSigTimeoutTime_PCM" SG_ 2650777735 StgOver35_h_FFA887 3000000;
BA_ "SigType" SG_ 2650777735 StgOver35_h_FFA887 1;
BA_ "CI_ParId" SG_ 2650777735 StgOver40_h_FFA887 "MV034";
BA_ "CI_SigId" SG_ 2650777735 StgOver40_h_FFA887 44208;
BA_ "CI_SigName" SG_ 2650777735 StgOver40_h_FFA887 "StgOver40_h";
BA_ "GenSigTimeoutTime_PCM" SG_ 2650777735 StgOver40_h_FFA887 3000000;
BA_ "SigType" SG_ 2650777735 StgOver40_h_FFA887 1;
BA_ "CI_ParId" SG_ 2650777735 StgOver45_h_FFA887 "MV033";
BA_ "CI_SigId" SG_ 2650777735 StgOver45_h_FFA887 44207;
BA_ "CI_SigName" SG_ 2650777735 StgOver45_h_FFA887 "StgOver45_h";
BA_ "GenSigTimeoutTime_PCM" SG_ 2650777735 StgOver45_h_FFA887 3000000;
BA_ "SigType" SG_ 2650777735 StgOver45_h_FFA887 1;
BA_ "CI_ParId" SG_ 2650777735 StgOver55_h_FFA887 "MV032";
BA_ "CI_SigId" SG_ 2650777735 StgOver55_h_FFA887 44206;
BA_ "CI_SigName" SG_ 2650777735 StgOver55_h_FFA887 "StgOver55_h";
BA_ "GenSigTimeoutTime_PCM" SG_ 2650777735 StgOver55_h_FFA887 3000000;
BA_ "SigType" SG_ 2650777735 StgOver55_h_FFA887 1;
BA_ "CI_ParId" SG_ 2650777844 MaxIntervalViolation_FFA8F4 "MV043";
BA_ "CI_SigId" SG_ 2650777844 MaxIntervalViolation_FFA8F4 44165;
BA_ "CI_SigName" SG_ 2650777844 MaxIntervalViolation_FFA8F4 "MaxIntervalViolation";
BA_ "GenSigTimeoutTime_PCM" SG_ 2650777844 MaxIntervalViolation_FFA8F4 3000000;
BA_ "CI_ParId" SG_ 2650777844 StgBelowNeg30_h_FFA8F4 "MV042";
BA_ "CI_SigId" SG_ 2650777844 StgBelowNeg30_h_FFA8F4 44164;
BA_ "CI_SigName" SG_ 2650777844 StgBelowNeg30_h_FFA8F4 "StgBelowNeg30_h";
BA_ "GenSigTimeoutTime_PCM" SG_ 2650777844 StgBelowNeg30_h_FFA8F4 3000000;
BA_ "SigType" SG_ 2650777844 StgBelowNeg30_h_FFA8F4 1;
BA_ "CI_ParId" SG_ 2650777844 StgBelowNeg20_h_FFA8F4 "MV041";
BA_ "CI_SigId" SG_ 2650777844 StgBelowNeg20_h_FFA8F4 44163;
BA_ "CI_SigName" SG_ 2650777844 StgBelowNeg20_h_FFA8F4 "StgBelowNeg20_h";
BA_ "GenSigTimeoutTime_PCM" SG_ 2650777844 StgBelowNeg20_h_FFA8F4 3000000;
BA_ "SigType" SG_ 2650777844 StgBelowNeg20_h_FFA8F4 1;
BA_ "CI_ParId" SG_ 2650777844 StgBelowNeg10_h_FFA8F4 "MV040";
BA_ "CI_SigId" SG_ 2650777844 StgBelowNeg10_h_FFA8F4 44162;
BA_ "CI_SigName" SG_ 2650777844 StgBelowNeg10_h_FFA8F4 "StgBelowNeg10_h";
BA_ "GenSigTimeoutTime_PCM" SG_ 2650777844 StgBelowNeg10_h_FFA8F4 3000000;
BA_ "SigType" SG_ 2650777844 StgBelowNeg10_h_FFA8F4 1;
BA_ "CI_ParId" SG_ 2650777844 StgBelow0_h_FFA8F4 "MV039";
BA_ "CI_SigId" SG_ 2650777844 StgBelow0_h_FFA8F4 44161;
BA_ "CI_SigName" SG_ 2650777844 StgBelow0_h_FFA8F4 "StgBelow0_h";
BA_ "GenSigTimeoutTime_PCM" SG_ 2650777844 StgBelow0_h_FFA8F4 3000000;
BA_ "SigType" SG_ 2650777844 StgBelow0_h_FFA8F4 1;
BA_ "CI_ParId" SG_ 2650777844 StgOver0_h_FFA8F4 "MV038";
BA_ "CI_SigId" SG_ 2650777844 StgOver0_h_FFA8F4 44160;
BA_ "CI_SigName" SG_ 2650777844 StgOver0_h_FFA8F4 "StgOver0_h";
BA_ "GenSigTimeoutTime_PCM" SG_ 2650777844 StgOver0_h_FFA8F4 3000000;
BA_ "SigType" SG_ 2650777844 StgOver0_h_FFA8F4 1;
BA_ "CI_ParId" SG_ 2650777844 StgOver15_h_FFA8F4 "MV037";
BA_ "CI_SigId" SG_ 2650777844 StgOver15_h_FFA8F4 44159;
BA_ "CI_SigName" SG_ 2650777844 StgOver15_h_FFA8F4 "StgOver15_h";
BA_ "GenSigTimeoutTime_PCM" SG_ 2650777844 StgOver15_h_FFA8F4 3000000;
BA_ "SigType" SG_ 2650777844 StgOver15_h_FFA8F4 1;
BA_ "CI_ParId" SG_ 2650777844 StgOver30_h_FFA8F4 "MV036";
BA_ "CI_SigId" SG_ 2650777844 StgOver30_h_FFA8F4 44158;
BA_ "CI_SigName" SG_ 2650777844 StgOver30_h_FFA8F4 "StgOver30_h";
BA_ "GenSigTimeoutTime_PCM" SG_ 2650777844 StgOver30_h_FFA8F4 3000000;
BA_ "SigType" SG_ 2650777844 StgOver30_h_FFA8F4 1;
BA_ "CI_ParId" SG_ 2650777844 StgOver35_h_FFA8F4 "MV035";
BA_ "CI_SigId" SG_ 2650777844 StgOver35_h_FFA8F4 44157;
BA_ "CI_SigName" SG_ 2650777844 StgOver35_h_FFA8F4 "StgOver35_h";
BA_ "GenSigTimeoutTime_PCM" SG_ 2650777844 StgOver35_h_FFA8F4 3000000;
BA_ "SigType" SG_ 2650777844 StgOver35_h_FFA8F4 1;
BA_ "CI_ParId" SG_ 2650777844 StgOver40_h_FFA8F4 "MV034";
BA_ "CI_SigId" SG_ 2650777844 StgOver40_h_FFA8F4 44156;
BA_ "CI_SigName" SG_ 2650777844 StgOver40_h_FFA8F4 "StgOver40_h";
BA_ "GenSigTimeoutTime_PCM" SG_ 2650777844 StgOver40_h_FFA8F4 3000000;
BA_ "SigType" SG_ 2650777844 StgOver40_h_FFA8F4 1;
BA_ "CI_ParId" SG_ 2650777844 StgOver45_h_FFA8F4 "MV033";
BA_ "CI_SigId" SG_ 2650777844 StgOver45_h_FFA8F4 44155;
BA_ "CI_SigName" SG_ 2650777844 StgOver45_h_FFA8F4 "StgOver45_h";
BA_ "GenSigTimeoutTime_PCM" SG_ 2650777844 StgOver45_h_FFA8F4 3000000;
BA_ "SigType" SG_ 2650777844 StgOver45_h_FFA8F4 1;
BA_ "CI_ParId" SG_ 2650777844 StgOver55_h_FFA8F4 "MV032";
BA_ "CI_SigId" SG_ 2650777844 StgOver55_h_FFA8F4 44154;
BA_ "CI_SigName" SG_ 2650777844 StgOver55_h_FFA8F4 "StgOver55_h";
BA_ "GenSigTimeoutTime_PCM" SG_ 2650777844 StgOver55_h_FFA8F4 3000000;
BA_ "SigType" SG_ 2650777844 StgOver55_h_FFA8F4 1;
BA_ "CI_ParId" SG_ 2650777845 MaxIntervalViolation_FFA8F5 "MV043";
BA_ "CI_SigId" SG_ 2650777845 MaxIntervalViolation_FFA8F5 44178;
BA_ "CI_SigName" SG_ 2650777845 MaxIntervalViolation_FFA8F5 "MaxIntervalViolation";
BA_ "GenSigTimeoutTime_PCM" SG_ 2650777845 MaxIntervalViolation_FFA8F5 3000000;
BA_ "CI_ParId" SG_ 2650777845 StgBelowNeg30_h_FFA8F5 "MV042";
BA_ "CI_SigId" SG_ 2650777845 StgBelowNeg30_h_FFA8F5 44177;
BA_ "CI_SigName" SG_ 2650777845 StgBelowNeg30_h_FFA8F5 "StgBelowNeg30_h";
BA_ "GenSigTimeoutTime_PCM" SG_ 2650777845 StgBelowNeg30_h_FFA8F5 3000000;
BA_ "SigType" SG_ 2650777845 StgBelowNeg30_h_FFA8F5 1;
BA_ "CI_ParId" SG_ 2650777845 StgBelowNeg20_h_FFA8F5 "MV041";
BA_ "CI_SigId" SG_ 2650777845 StgBelowNeg20_h_FFA8F5 44176;
BA_ "CI_SigName" SG_ 2650777845 StgBelowNeg20_h_FFA8F5 "StgBelowNeg20_h";
BA_ "GenSigTimeoutTime_PCM" SG_ 2650777845 StgBelowNeg20_h_FFA8F5 3000000;
BA_ "SigType" SG_ 2650777845 StgBelowNeg20_h_FFA8F5 1;
BA_ "CI_ParId" SG_ 2650777845 StgBelowNeg10_h_FFA8F5 "MV040";
BA_ "CI_SigId" SG_ 2650777845 StgBelowNeg10_h_FFA8F5 44175;
BA_ "CI_SigName" SG_ 2650777845 StgBelowNeg10_h_FFA8F5 "StgBelowNeg10_h";
BA_ "GenSigTimeoutTime_PCM" SG_ 2650777845 StgBelowNeg10_h_FFA8F5 3000000;
BA_ "SigType" SG_ 2650777845 StgBelowNeg10_h_FFA8F5 1;
BA_ "CI_ParId" SG_ 2650777845 StgBelow0_h_FFA8F5 "MV039";
BA_ "CI_SigId" SG_ 2650777845 StgBelow0_h_FFA8F5 44174;
BA_ "CI_SigName" SG_ 2650777845 StgBelow0_h_FFA8F5 "StgBelow0_h";
BA_ "GenSigTimeoutTime_PCM" SG_ 2650777845 StgBelow0_h_FFA8F5 3000000;
BA_ "SigType" SG_ 2650777845 StgBelow0_h_FFA8F5 1;
BA_ "CI_ParId" SG_ 2650777845 StgOver0_h_FFA8F5 "MV038";
BA_ "CI_SigId" SG_ 2650777845 StgOver0_h_FFA8F5 44173;
BA_ "CI_SigName" SG_ 2650777845 StgOver0_h_FFA8F5 "StgOver0_h";
BA_ "GenSigTimeoutTime_PCM" SG_ 2650777845 StgOver0_h_FFA8F5 3000000;
BA_ "SigType" SG_ 2650777845 StgOver0_h_FFA8F5 1;
BA_ "CI_ParId" SG_ 2650777845 StgOver15_h_FFA8F5 "MV037";
BA_ "CI_SigId" SG_ 2650777845 StgOver15_h_FFA8F5 44172;
BA_ "CI_SigName" SG_ 2650777845 StgOver15_h_FFA8F5 "StgOver15_h";
BA_ "GenSigTimeoutTime_PCM" SG_ 2650777845 StgOver15_h_FFA8F5 3000000;
BA_ "SigType" SG_ 2650777845 StgOver15_h_FFA8F5 1;
BA_ "CI_ParId" SG_ 2650777845 StgOver30_h_FFA8F5 "MV036";
BA_ "CI_SigId" SG_ 2650777845 StgOver30_h_FFA8F5 44171;
BA_ "CI_SigName" SG_ 2650777845 StgOver30_h_FFA8F5 "StgOver30_h";
BA_ "GenSigTimeoutTime_PCM" SG_ 2650777845 StgOver30_h_FFA8F5 3000000;
BA_ "SigType" SG_ 2650777845 StgOver30_h_FFA8F5 1;
BA_ "CI_ParId" SG_ 2650777845 StgOver35_h_FFA8F5 "MV035";
BA_ "CI_SigId" SG_ 2650777845 StgOver35_h_FFA8F5 44170;
BA_ "CI_SigName" SG_ 2650777845 StgOver35_h_FFA8F5 "StgOver35_h";
BA_ "GenSigTimeoutTime_PCM" SG_ 2650777845 StgOver35_h_FFA8F5 3000000;
BA_ "SigType" SG_ 2650777845 StgOver35_h_FFA8F5 1;
BA_ "CI_ParId" SG_ 2650777845 StgOver40_h_FFA8F5 "MV034";
BA_ "CI_SigId" SG_ 2650777845 StgOver40_h_FFA8F5 44169;
BA_ "CI_SigName" SG_ 2650777845 StgOver40_h_FFA8F5 "StgOver40_h";
BA_ "GenSigTimeoutTime_PCM" SG_ 2650777845 StgOver40_h_FFA8F5 3000000;
BA_ "SigType" SG_ 2650777845 StgOver40_h_FFA8F5 1;
BA_ "CI_ParId" SG_ 2650777845 StgOver45_h_FFA8F5 "MV033";
BA_ "CI_SigId" SG_ 2650777845 StgOver45_h_FFA8F5 44168;
BA_ "CI_SigName" SG_ 2650777845 StgOver45_h_FFA8F5 "StgOver45_h";
BA_ "GenSigTimeoutTime_PCM" SG_ 2650777845 StgOver45_h_FFA8F5 3000000;
BA_ "SigType" SG_ 2650777845 StgOver45_h_FFA8F5 1;
BA_ "CI_ParId" SG_ 2650777845 StgOver55_h_FFA8F5 "MV032";
BA_ "CI_SigId" SG_ 2650777845 StgOver55_h_FFA8F5 44167;
BA_ "CI_SigName" SG_ 2650777845 StgOver55_h_FFA8F5 "StgOver55_h";
BA_ "GenSigTimeoutTime_PCM" SG_ 2650777845 StgOver55_h_FFA8F5 3000000;
BA_ "SigType" SG_ 2650777845 StgOver55_h_FFA8F5 1;
BA_ "CI_ParId" SG_ 2650777846 MaxIntervalViolation_FFA8F6 "MV043";
BA_ "CI_SigId" SG_ 2650777846 MaxIntervalViolation_FFA8F6 44191;
BA_ "CI_SigName" SG_ 2650777846 MaxIntervalViolation_FFA8F6 "MaxIntervalViolation";
BA_ "GenSigTimeoutTime_PCM" SG_ 2650777846 MaxIntervalViolation_FFA8F6 3000000;
BA_ "CI_ParId" SG_ 2650777846 StgBelowNeg30_h_FFA8F6 "MV042";
BA_ "CI_SigId" SG_ 2650777846 StgBelowNeg30_h_FFA8F6 44190;
BA_ "CI_SigName" SG_ 2650777846 StgBelowNeg30_h_FFA8F6 "StgBelowNeg30_h";
BA_ "GenSigTimeoutTime_PCM" SG_ 2650777846 StgBelowNeg30_h_FFA8F6 3000000;
BA_ "SigType" SG_ 2650777846 StgBelowNeg30_h_FFA8F6 1;
BA_ "CI_ParId" SG_ 2650777846 StgBelowNeg20_h_FFA8F6 "MV041";
BA_ "CI_SigId" SG_ 2650777846 StgBelowNeg20_h_FFA8F6 44189;
BA_ "CI_SigName" SG_ 2650777846 StgBelowNeg20_h_FFA8F6 "StgBelowNeg20_h";
BA_ "GenSigTimeoutTime_PCM" SG_ 2650777846 StgBelowNeg20_h_FFA8F6 3000000;
BA_ "SigType" SG_ 2650777846 StgBelowNeg20_h_FFA8F6 1;
BA_ "CI_ParId" SG_ 2650777846 StgBelowNeg10_h_FFA8F6 "MV040";
BA_ "CI_SigId" SG_ 2650777846 StgBelowNeg10_h_FFA8F6 44188;
BA_ "CI_SigName" SG_ 2650777846 StgBelowNeg10_h_FFA8F6 "StgBelowNeg10_h";
BA_ "GenSigTimeoutTime_PCM" SG_ 2650777846 StgBelowNeg10_h_FFA8F6 3000000;
BA_ "SigType" SG_ 2650777846 StgBelowNeg10_h_FFA8F6 1;
BA_ "CI_ParId" SG_ 2650777846 StgBelow0_h_FFA8F6 "MV039";
BA_ "CI_SigId" SG_ 2650777846 StgBelow0_h_FFA8F6 44187;
BA_ "CI_SigName" SG_ 2650777846 StgBelow0_h_FFA8F6 "StgBelow0_h";
BA_ "GenSigTimeoutTime_PCM" SG_ 2650777846 StgBelow0_h_FFA8F6 3000000;
BA_ "SigType" SG_ 2650777846 StgBelow0_h_FFA8F6 1;
BA_ "CI_ParId" SG_ 2650777846 StgOver0_h_FFA8F6 "MV038";
BA_ "CI_SigId" SG_ 2650777846 StgOver0_h_FFA8F6 44186;
BA_ "CI_SigName" SG_ 2650777846 StgOver0_h_FFA8F6 "StgOver0_h";
BA_ "GenSigTimeoutTime_PCM" SG_ 2650777846 StgOver0_h_FFA8F6 3000000;
BA_ "SigType" SG_ 2650777846 StgOver0_h_FFA8F6 1;
BA_ "CI_ParId" SG_ 2650777846 StgOver15_h_FFA8F6 "MV037";
BA_ "CI_SigId" SG_ 2650777846 StgOver15_h_FFA8F6 44185;
BA_ "CI_SigName" SG_ 2650777846 StgOver15_h_FFA8F6 "StgOver15_h";
BA_ "GenSigTimeoutTime_PCM" SG_ 2650777846 StgOver15_h_FFA8F6 3000000;
BA_ "SigType" SG_ 2650777846 StgOver15_h_FFA8F6 1;
BA_ "CI_ParId" SG_ 2650777846 StgOver30_h_FFA8F6 "MV036";
BA_ "CI_SigId" SG_ 2650777846 StgOver30_h_FFA8F6 44184;
BA_ "CI_SigName" SG_ 2650777846 StgOver30_h_FFA8F6 "StgOver30_h";
BA_ "GenSigTimeoutTime_PCM" SG_ 2650777846 StgOver30_h_FFA8F6 3000000;
BA_ "SigType" SG_ 2650777846 StgOver30_h_FFA8F6 1;
BA_ "CI_ParId" SG_ 2650777846 StgOver35_h_FFA8F6 "MV035";
BA_ "CI_SigId" SG_ 2650777846 StgOver35_h_FFA8F6 44183;
BA_ "CI_SigName" SG_ 2650777846 StgOver35_h_FFA8F6 "StgOver35_h";
BA_ "GenSigTimeoutTime_PCM" SG_ 2650777846 StgOver35_h_FFA8F6 3000000;
BA_ "SigType" SG_ 2650777846 StgOver35_h_FFA8F6 1;
BA_ "CI_ParId" SG_ 2650777846 StgOver40_h_FFA8F6 "MV034";
BA_ "CI_SigId" SG_ 2650777846 StgOver40_h_FFA8F6 44182;
BA_ "CI_SigName" SG_ 2650777846 StgOver40_h_FFA8F6 "StgOver40_h";
BA_ "GenSigTimeoutTime_PCM" SG_ 2650777846 StgOver40_h_FFA8F6 3000000;
BA_ "SigType" SG_ 2650777846 StgOver40_h_FFA8F6 1;
BA_ "CI_ParId" SG_ 2650777846 StgOver45_h_FFA8F6 "MV033";
BA_ "CI_SigId" SG_ 2650777846 StgOver45_h_FFA8F6 44181;
BA_ "CI_SigName" SG_ 2650777846 StgOver45_h_FFA8F6 "StgOver45_h";
BA_ "GenSigTimeoutTime_PCM" SG_ 2650777846 StgOver45_h_FFA8F6 3000000;
BA_ "SigType" SG_ 2650777846 StgOver45_h_FFA8F6 1;
BA_ "CI_ParId" SG_ 2650777846 StgOver55_h_FFA8F6 "MV032";
BA_ "CI_SigId" SG_ 2650777846 StgOver55_h_FFA8F6 44180;
BA_ "CI_SigName" SG_ 2650777846 StgOver55_h_FFA8F6 "StgOver55_h";
BA_ "GenSigTimeoutTime_PCM" SG_ 2650777846 StgOver55_h_FFA8F6 3000000;
BA_ "SigType" SG_ 2650777846 StgOver55_h_FFA8F6 1;
BA_ "CI_ParId" SG_ 2583654525 TboxSts "ID0975";
BA_ "CI_SigId" SG_ 2583654525 TboxSts 33780;
BA_ "CI_SigName" SG_ 2583654525 TboxSts "Tbox Status ";
BA_ "GenSigTimeoutTime_PCM" SG_ 2583654525 TboxSts 25000;
BA_ "SigType" SG_ 2583654525 TboxSts 4;
BA_ "CI_ParId" SG_ 2566898670 WFact "V007";
BA_ "CI_SigId" SG_ 2566898670 WFact 1661;
BA_ "CI_SigName" SG_ 2566898670 WFact "W Factor";
BA_ "GenSigSendType" SG_ 2566898670 WFact 3;
BA_ "GenSigStartValue" SG_ 2566898670 WFact 2400;
BA_ "GenSigTimeoutTime_PCM" SG_ 2566898670 WFact 300000;
BA_ "SigType" SG_ 2566898670 WFact 1;
BA_ "CI_ParId" SG_ 2566898670 NextCalDateYr "V052";
BA_ "CI_SigId" SG_ 2566898670 NextCalDateYr 1660;
BA_ "CI_SigName" SG_ 2566898670 NextCalDateYr "Next Calibration Date - Year";
BA_ "GenSigSendType" SG_ 2566898670 NextCalDateYr 3;
BA_ "GenSigTimeoutTime_PCM" SG_ 2566898670 NextCalDateYr 300000;
BA_ "SigType" SG_ 2566898670 NextCalDateYr 1;
BA_ "CI_ParId" SG_ 2566898670 NextCalDateMonth "V051";
BA_ "CI_SigId" SG_ 2566898670 NextCalDateMonth 1659;
BA_ "CI_SigName" SG_ 2566898670 NextCalDateMonth "Next Calibration Date - Month";
BA_ "GenSigSendType" SG_ 2566898670 NextCalDateMonth 3;
BA_ "GenSigStartValue" SG_ 2566898670 NextCalDateMonth 1;
BA_ "GenSigTimeoutTime_PCM" SG_ 2566898670 NextCalDateMonth 300000;
BA_ "SigType" SG_ 2566898670 NextCalDateMonth 1;
BA_ "CI_ParId" SG_ 2566898670 NextCalDateDay "V050";
BA_ "CI_SigId" SG_ 2566898670 NextCalDateDay 1658;
BA_ "CI_SigName" SG_ 2566898670 NextCalDateDay "Next Calibration Date - Day";
BA_ "GenSigSendType" SG_ 2566898670 NextCalDateDay 3;
BA_ "GenSigStartValue" SG_ 2566898670 NextCalDateDay 1;
BA_ "GenSigTimeoutTime_PCM" SG_ 2566898670 NextCalDateDay 300000;
BA_ "SigType" SG_ 2566898670 NextCalDateDay 1;
BA_ "CI_ParId" SG_ 2566898670 PrefLang "V005";
BA_ "CI_SigId" SG_ 2566898670 PrefLang 1657;
BA_ "CI_SigName" SG_ 2566898670 PrefLang "Preferred Language";
BA_ "GenSigSendType" SG_ 2566898670 PrefLang 3;
BA_ "GenSigTimeoutTime_PCM" SG_ 2566898670 PrefLang 300000;
BA_ "SigType" SG_ 2566898670 PrefLang 3;
BA_ "CI_ParId" SG_ 2566898670 Driv1Id_FFC3EE "V004";
BA_ "CI_SigId" SG_ 2566898670 Driv1Id_FFC3EE 1656;
BA_ "CI_SigName" SG_ 2566898670 Driv1Id_FFC3EE "Driver 1 Identification";
BA_ "GenSigSendType" SG_ 2566898670 Driv1Id_FFC3EE 3;
BA_ "GenSigTimeoutTime_PCM" SG_ 2566898670 Driv1Id_FFC3EE 300000;
BA_ "SigType" SG_ 2566898670 Driv1Id_FFC3EE 3;
BA_ "CI_ParId" SG_ 2566898926 PrintDrawSts "V013";
BA_ "CI_SigId" SG_ 2566898926 PrintDrawSts 1668;
BA_ "CI_SigName" SG_ 2566898926 PrintDrawSts "Printer Drawer State";
BA_ "GenSigTimeoutTime_PCM" SG_ 2566898926 PrintDrawSts 50000;
BA_ "SigType" SG_ 2566898926 PrintDrawSts 4;
BA_ "CI_ParId" SG_ 2566898926 EndOfLifeDriv1CardAlert "V012";
BA_ "CI_SigId" SG_ 2566898926 EndOfLifeDriv1CardAlert 1667;
BA_ "CI_SigName" SG_ 2566898926 EndOfLifeDriv1CardAlert "End Of Life Driver 1 Card Alert";
BA_ "GenSigTimeoutTime_PCM" SG_ 2566898926 EndOfLifeDriv1CardAlert 50000;
BA_ "SigType" SG_ 2566898926 EndOfLifeDriv1CardAlert 4;
BA_ "CI_ParId" SG_ 2566898926 Driv1CardDwlAlert "V011";
BA_ "CI_SigId" SG_ 2566898926 Driv1CardDwlAlert 1666;
BA_ "CI_SigName" SG_ 2566898926 Driv1CardDwlAlert "Driver1 Card Download Alert";
BA_ "GenSigTimeoutTime_PCM" SG_ 2566898926 Driv1CardDwlAlert 50000;
BA_ "SigType" SG_ 2566898926 Driv1CardDwlAlert 4;
BA_ "CI_ParId" SG_ 2566898926 Driv1CurDurOfSelActv "V010";
BA_ "CI_SigId" SG_ 2566898926 Driv1CurDurOfSelActv 1665;
BA_ "CI_SigName" SG_ 2566898926 Driv1CurDurOfSelActv "Driver1 Current Duration Of Selected Activity";
BA_ "GenSigTimeoutTime_PCM" SG_ 2566898926 Driv1CurDurOfSelActv 50000;
BA_ "SigType" SG_ 2566898926 Driv1CurDurOfSelActv 1;
BA_ "CI_ParId" SG_ 2566898926 Driv1CumulBreakTime "V009";
BA_ "CI_SigId" SG_ 2566898926 Driv1CumulBreakTime 1664;
BA_ "CI_SigName" SG_ 2566898926 Driv1CumulBreakTime "Driver1 Cumulative Break Time";
BA_ "GenSigTimeoutTime_PCM" SG_ 2566898926 Driv1CumulBreakTime 50000;
BA_ "SigType" SG_ 2566898926 Driv1CumulBreakTime 1;
BA_ "CI_ParId" SG_ 2566898926 Driv1ContDrivTime "V008";
BA_ "CI_SigId" SG_ 2566898926 Driv1ContDrivTime 1663;
BA_ "CI_SigName" SG_ 2566898926 Driv1ContDrivTime "Driver1 Continuous Driving Time";
BA_ "GenSigTimeoutTime_PCM" SG_ 2566898926 Driv1ContDrivTime 50000;
BA_ "SigType" SG_ 2566898926 Driv1ContDrivTime 1;
BA_ "CI_ParId" SG_ 2566899694 AvCnt "V049";
BA_ "CI_SigId" SG_ 2566899694 AvCnt 1705;
BA_ "CI_SigName" SG_ 2566899694 AvCnt "Available Counter";
BA_ "GenSigSendType" SG_ 2566899694 AvCnt 3;
BA_ "GenSigTimeoutTime_PCM" SG_ 2566899694 AvCnt 300000;
BA_ "SigType" SG_ 2566899694 AvCnt 1;
BA_ "CI_ParId" SG_ 2566899694 WorkCnt "V048";
BA_ "CI_SigId" SG_ 2566899694 WorkCnt 1704;
BA_ "CI_SigName" SG_ 2566899694 WorkCnt "Work Counter";
BA_ "GenSigSendType" SG_ 2566899694 WorkCnt 3;
BA_ "GenSigTimeoutTime_PCM" SG_ 2566899694 WorkCnt 300000;
BA_ "SigType" SG_ 2566899694 WorkCnt 1;
BA_ "CI_ParId" SG_ 2566899694 DrivCnt "V047";
BA_ "CI_SigId" SG_ 2566899694 DrivCnt 1703;
BA_ "CI_SigName" SG_ 2566899694 DrivCnt "Driving Counter";
BA_ "GenSigSendType" SG_ 2566899694 DrivCnt 3;
BA_ "GenSigTimeoutTime_PCM" SG_ 2566899694 DrivCnt 300000;
BA_ "SigType" SG_ 2566899694 DrivCnt 1;
BA_ "CI_ParId" SG_ 2566899694 TwoWeeksTotOdo "V046";
BA_ "CI_SigId" SG_ 2566899694 TwoWeeksTotOdo 1702;
BA_ "CI_SigName" SG_ 2566899694 TwoWeeksTotOdo "Two Weeks Total Odometer";
BA_ "GenSigSendType" SG_ 2566899694 TwoWeeksTotOdo 3;
BA_ "GenSigTimeoutTime_PCM" SG_ 2566899694 TwoWeeksTotOdo 300000;
BA_ "SigType" SG_ 2566899694 TwoWeeksTotOdo 1;
BA_ "CI_ParId" SG_ 2566899694 WeekTotOdo "V045";
BA_ "CI_SigId" SG_ 2566899694 WeekTotOdo 1701;
BA_ "CI_SigName" SG_ 2566899694 WeekTotOdo "Weekly Total Odometer";
BA_ "GenSigSendType" SG_ 2566899694 WeekTotOdo 3;
BA_ "GenSigTimeoutTime_PCM" SG_ 2566899694 WeekTotOdo 300000;
BA_ "SigType" SG_ 2566899694 WeekTotOdo 1;
BA_ "CI_ParId" SG_ 2566899694 DayOdo "V044";
BA_ "CI_SigId" SG_ 2566899694 DayOdo 1700;
BA_ "CI_SigName" SG_ 2566899694 DayOdo "Daily Odometer";
BA_ "GenSigSendType" SG_ 2566899694 DayOdo 3;
BA_ "GenSigTimeoutTime_PCM" SG_ 2566899694 DayOdo 300000;
BA_ "SigType" SG_ 2566899694 DayOdo 1;
BA_ "CI_ParId" SG_ 2566899694 DayRestPer7Flag "V043";
BA_ "CI_SigId" SG_ 2566899694 DayRestPer7Flag 1699;
BA_ "CI_SigName" SG_ 2566899694 DayRestPer7Flag "Daily Resting Period 7 Flag";
BA_ "GenSigSendType" SG_ 2566899694 DayRestPer7Flag 3;
BA_ "GenSigTimeoutTime_PCM" SG_ 2566899694 DayRestPer7Flag 300000;
BA_ "CI_ParId" SG_ 2566899694 DayRestPer7 "V042";
BA_ "CI_SigId" SG_ 2566899694 DayRestPer7 1698;
BA_ "CI_SigName" SG_ 2566899694 DayRestPer7 "Daily Resting Period 7";
BA_ "GenSigSendType" SG_ 2566899694 DayRestPer7 3;
BA_ "GenSigTimeoutTime_PCM" SG_ 2566899694 DayRestPer7 300000;
BA_ "CI_ParId" SG_ 2566899694 DayRestPer6Flag "V041";
BA_ "CI_SigId" SG_ 2566899694 DayRestPer6Flag 1697;
BA_ "CI_SigName" SG_ 2566899694 DayRestPer6Flag "Daily Resting Period 6 Flag";
BA_ "GenSigSendType" SG_ 2566899694 DayRestPer6Flag 3;
BA_ "GenSigTimeoutTime_PCM" SG_ 2566899694 DayRestPer6Flag 300000;
BA_ "CI_ParId" SG_ 2566899694 DayRestPer6 "V040";
BA_ "CI_SigId" SG_ 2566899694 DayRestPer6 1696;
BA_ "CI_SigName" SG_ 2566899694 DayRestPer6 "Daily Resting Period 6";
BA_ "GenSigSendType" SG_ 2566899694 DayRestPer6 3;
BA_ "GenSigTimeoutTime_PCM" SG_ 2566899694 DayRestPer6 300000;
BA_ "CI_ParId" SG_ 2566899694 DayRestPer5Flag "V039";
BA_ "CI_SigId" SG_ 2566899694 DayRestPer5Flag 1695;
BA_ "CI_SigName" SG_ 2566899694 DayRestPer5Flag "Daily Resting Period 5 Flag";
BA_ "GenSigSendType" SG_ 2566899694 DayRestPer5Flag 3;
BA_ "GenSigTimeoutTime_PCM" SG_ 2566899694 DayRestPer5Flag 300000;
BA_ "CI_ParId" SG_ 2566899694 DayRestPer5 "V038";
BA_ "CI_SigId" SG_ 2566899694 DayRestPer5 1694;
BA_ "CI_SigName" SG_ 2566899694 DayRestPer5 "Daily Resting Period 5";
BA_ "GenSigSendType" SG_ 2566899694 DayRestPer5 3;
BA_ "GenSigTimeoutTime_PCM" SG_ 2566899694 DayRestPer5 300000;
BA_ "CI_ParId" SG_ 2566899694 DayRestPer4Flag "V037";
BA_ "CI_SigId" SG_ 2566899694 DayRestPer4Flag 1693;
BA_ "CI_SigName" SG_ 2566899694 DayRestPer4Flag "Daily Resting Period 4 Flag";
BA_ "GenSigSendType" SG_ 2566899694 DayRestPer4Flag 3;
BA_ "GenSigTimeoutTime_PCM" SG_ 2566899694 DayRestPer4Flag 300000;
BA_ "CI_ParId" SG_ 2566899694 DayRestPer4 "V036";
BA_ "CI_SigId" SG_ 2566899694 DayRestPer4 1692;
BA_ "CI_SigName" SG_ 2566899694 DayRestPer4 "Daily Resting Period 4";
BA_ "GenSigSendType" SG_ 2566899694 DayRestPer4 3;
BA_ "GenSigTimeoutTime_PCM" SG_ 2566899694 DayRestPer4 300000;
BA_ "CI_ParId" SG_ 2566899694 DayRestPer3Flag "V035";
BA_ "CI_SigId" SG_ 2566899694 DayRestPer3Flag 1691;
BA_ "CI_SigName" SG_ 2566899694 DayRestPer3Flag "Daily Resting Period 3 Flag";
BA_ "GenSigSendType" SG_ 2566899694 DayRestPer3Flag 3;
BA_ "GenSigTimeoutTime_PCM" SG_ 2566899694 DayRestPer3Flag 300000;
BA_ "CI_ParId" SG_ 2566899694 DayRestPer3 "V034";
BA_ "CI_SigId" SG_ 2566899694 DayRestPer3 1690;
BA_ "CI_SigName" SG_ 2566899694 DayRestPer3 "Daily Resting Period 3";
BA_ "GenSigSendType" SG_ 2566899694 DayRestPer3 3;
BA_ "GenSigTimeoutTime_PCM" SG_ 2566899694 DayRestPer3 300000;
BA_ "CI_ParId" SG_ 2566899694 DayRestPer2Flag "V033";
BA_ "CI_SigId" SG_ 2566899694 DayRestPer2Flag 1689;
BA_ "CI_SigName" SG_ 2566899694 DayRestPer2Flag "Daily Resting Period 2 Flag";
BA_ "GenSigSendType" SG_ 2566899694 DayRestPer2Flag 3;
BA_ "GenSigTimeoutTime_PCM" SG_ 2566899694 DayRestPer2Flag 300000;
BA_ "CI_ParId" SG_ 2566899694 DayRestPer2 "V032";
BA_ "CI_SigId" SG_ 2566899694 DayRestPer2 1688;
BA_ "CI_SigName" SG_ 2566899694 DayRestPer2 "Daily Resting Period 2";
BA_ "GenSigSendType" SG_ 2566899694 DayRestPer2 3;
BA_ "GenSigTimeoutTime_PCM" SG_ 2566899694 DayRestPer2 300000;
BA_ "CI_ParId" SG_ 2566899694 DayRestPer1Flag "V031";
BA_ "CI_SigId" SG_ 2566899694 DayRestPer1Flag 1687;
BA_ "CI_SigName" SG_ 2566899694 DayRestPer1Flag "Daily Resting Period 1 Flag";
BA_ "GenSigSendType" SG_ 2566899694 DayRestPer1Flag 3;
BA_ "GenSigTimeoutTime_PCM" SG_ 2566899694 DayRestPer1Flag 300000;
BA_ "CI_ParId" SG_ 2566899694 DayRestPer1 "V030";
BA_ "CI_SigId" SG_ 2566899694 DayRestPer1 1686;
BA_ "CI_SigName" SG_ 2566899694 DayRestPer1 "Daily Resting Period 1";
BA_ "GenSigSendType" SG_ 2566899694 DayRestPer1 3;
BA_ "GenSigTimeoutTime_PCM" SG_ 2566899694 DayRestPer1 300000;
BA_ "CI_ParId" SG_ 2566899694 DayDrivTimeShift6Flag "V029";
BA_ "CI_SigId" SG_ 2566899694 DayDrivTimeShift6Flag 1685;
BA_ "CI_SigName" SG_ 2566899694 DayDrivTimeShift6Flag "Daily Driving Time Shift 6 Flag";
BA_ "GenSigSendType" SG_ 2566899694 DayDrivTimeShift6Flag 3;
BA_ "GenSigTimeoutTime_PCM" SG_ 2566899694 DayDrivTimeShift6Flag 300000;
BA_ "CI_ParId" SG_ 2566899694 DayDrivTimeShift6 "V028";
BA_ "CI_SigId" SG_ 2566899694 DayDrivTimeShift6 1684;
BA_ "CI_SigName" SG_ 2566899694 DayDrivTimeShift6 "Daily Driving Time Shift 6";
BA_ "GenSigSendType" SG_ 2566899694 DayDrivTimeShift6 3;
BA_ "GenSigTimeoutTime_PCM" SG_ 2566899694 DayDrivTimeShift6 300000;
BA_ "CI_ParId" SG_ 2566899694 DayDrivTimeShift5Flag "V027";
BA_ "CI_SigId" SG_ 2566899694 DayDrivTimeShift5Flag 1683;
BA_ "CI_SigName" SG_ 2566899694 DayDrivTimeShift5Flag "Daily Driving Time Shift 5 Flag";
BA_ "GenSigSendType" SG_ 2566899694 DayDrivTimeShift5Flag 3;
BA_ "GenSigTimeoutTime_PCM" SG_ 2566899694 DayDrivTimeShift5Flag 300000;
BA_ "CI_ParId" SG_ 2566899694 DayDrivTimeShift5 "V026";
BA_ "CI_SigId" SG_ 2566899694 DayDrivTimeShift5 1682;
BA_ "CI_SigName" SG_ 2566899694 DayDrivTimeShift5 "Daily Driving Time Shift 5";
BA_ "GenSigSendType" SG_ 2566899694 DayDrivTimeShift5 3;
BA_ "GenSigTimeoutTime_PCM" SG_ 2566899694 DayDrivTimeShift5 300000;
BA_ "CI_ParId" SG_ 2566899694 DayDrivTimeShift4Flag "V025";
BA_ "CI_SigId" SG_ 2566899694 DayDrivTimeShift4Flag 1681;
BA_ "CI_SigName" SG_ 2566899694 DayDrivTimeShift4Flag "Daily Driving Time Shift 4 Flag";
BA_ "GenSigSendType" SG_ 2566899694 DayDrivTimeShift4Flag 3;
BA_ "GenSigTimeoutTime_PCM" SG_ 2566899694 DayDrivTimeShift4Flag 300000;
BA_ "CI_ParId" SG_ 2566899694 DayDrivTimeShift4 "V024";
BA_ "CI_SigId" SG_ 2566899694 DayDrivTimeShift4 1680;
BA_ "CI_SigName" SG_ 2566899694 DayDrivTimeShift4 "Daily Driving Time Shift 4";
BA_ "GenSigSendType" SG_ 2566899694 DayDrivTimeShift4 3;
BA_ "GenSigTimeoutTime_PCM" SG_ 2566899694 DayDrivTimeShift4 300000;
BA_ "CI_ParId" SG_ 2566899694 DayDrivTimeShift3Flag "V023";
BA_ "CI_SigId" SG_ 2566899694 DayDrivTimeShift3Flag 1679;
BA_ "CI_SigName" SG_ 2566899694 DayDrivTimeShift3Flag "Daily Driving Time Shift 3 Flag";
BA_ "GenSigSendType" SG_ 2566899694 DayDrivTimeShift3Flag 3;
BA_ "GenSigTimeoutTime_PCM" SG_ 2566899694 DayDrivTimeShift3Flag 300000;
BA_ "CI_ParId" SG_ 2566899694 DayDrivTimeShift3 "V022";
BA_ "CI_SigId" SG_ 2566899694 DayDrivTimeShift3 1678;
BA_ "CI_SigName" SG_ 2566899694 DayDrivTimeShift3 "Daily Driving Time Shift 3";
BA_ "GenSigSendType" SG_ 2566899694 DayDrivTimeShift3 3;
BA_ "GenSigTimeoutTime_PCM" SG_ 2566899694 DayDrivTimeShift3 300000;
BA_ "CI_ParId" SG_ 2566899694 DayDrivTimeShift2Flag "V021";
BA_ "CI_SigId" SG_ 2566899694 DayDrivTimeShift2Flag 1677;
BA_ "CI_SigName" SG_ 2566899694 DayDrivTimeShift2Flag "Daily Driving Time Shift 2 Flag";
BA_ "GenSigSendType" SG_ 2566899694 DayDrivTimeShift2Flag 3;
BA_ "GenSigTimeoutTime_PCM" SG_ 2566899694 DayDrivTimeShift2Flag 300000;
BA_ "CI_ParId" SG_ 2566899694 DayDrivTimeShift2 "V020";
BA_ "CI_SigId" SG_ 2566899694 DayDrivTimeShift2 1676;
BA_ "CI_SigName" SG_ 2566899694 DayDrivTimeShift2 "Daily Driving Time Shift 2";
BA_ "GenSigSendType" SG_ 2566899694 DayDrivTimeShift2 3;
BA_ "GenSigTimeoutTime_PCM" SG_ 2566899694 DayDrivTimeShift2 300000;
BA_ "CI_ParId" SG_ 2566899694 DayDrivTimeShift1Flag "V019";
BA_ "CI_SigId" SG_ 2566899694 DayDrivTimeShift1Flag 1675;
BA_ "CI_SigName" SG_ 2566899694 DayDrivTimeShift1Flag "Daily Driving Time Shift 1 Flag";
BA_ "GenSigSendType" SG_ 2566899694 DayDrivTimeShift1Flag 3;
BA_ "GenSigTimeoutTime_PCM" SG_ 2566899694 DayDrivTimeShift1Flag 300000;
BA_ "CI_ParId" SG_ 2566899694 DayDrivTimeShift1 "V018";
BA_ "CI_SigId" SG_ 2566899694 DayDrivTimeShift1 1674;
BA_ "CI_SigName" SG_ 2566899694 DayDrivTimeShift1 "Daily Driving Time Shift 1";
BA_ "GenSigSendType" SG_ 2566899694 DayDrivTimeShift1 3;
BA_ "GenSigTimeoutTime_PCM" SG_ 2566899694 DayDrivTimeShift1 300000;
BA_ "CI_ParId" SG_ 2566899694 DayDrivTimeFlag "V017";
BA_ "CI_SigId" SG_ 2566899694 DayDrivTimeFlag 1673;
BA_ "CI_SigName" SG_ 2566899694 DayDrivTimeFlag "Daily Driving Time Flag";
BA_ "GenSigSendType" SG_ 2566899694 DayDrivTimeFlag 3;
BA_ "GenSigTimeoutTime_PCM" SG_ 2566899694 DayDrivTimeFlag 300000;
BA_ "CI_ParId" SG_ 2566899694 DayDrivTime "V016";
BA_ "CI_SigId" SG_ 2566899694 DayDrivTime 1672;
BA_ "CI_SigName" SG_ 2566899694 DayDrivTime "Daily Driving Time";
BA_ "GenSigSendType" SG_ 2566899694 DayDrivTime 3;
BA_ "GenSigTimeoutTime_PCM" SG_ 2566899694 DayDrivTime 300000;
BA_ "CI_ParId" SG_ 2566899694 WeekTotDrivTime "V015";
BA_ "CI_SigId" SG_ 2566899694 WeekTotDrivTime 1671;
BA_ "CI_SigName" SG_ 2566899694 WeekTotDrivTime "Weekly Total Driving Time";
BA_ "GenSigSendType" SG_ 2566899694 WeekTotDrivTime 3;
BA_ "GenSigTimeoutTime_PCM" SG_ 2566899694 WeekTotDrivTime 300000;
BA_ "SigType" SG_ 2566899694 WeekTotDrivTime 1;
BA_ "CI_ParId" SG_ 2566899694 TwoWeeksTotDrivTime "V014";
BA_ "CI_SigId" SG_ 2566899694 TwoWeeksTotDrivTime 1670;
BA_ "CI_SigName" SG_ 2566899694 TwoWeeksTotDrivTime "Two Weeks Total Driving Time";
BA_ "GenSigSendType" SG_ 2566899694 TwoWeeksTotDrivTime 3;
BA_ "GenSigTimeoutTime_PCM" SG_ 2566899694 TwoWeeksTotDrivTime 300000;
BA_ "SigType" SG_ 2566899694 TwoWeeksTotDrivTime 1;
BA_ "CI_ParId" SG_ 2650771712 DatasetCustEOL06 "F254";
BA_ "CI_SigId" SG_ 2650771712 DatasetCustEOL06 44609;
BA_ "CI_SigName" SG_ 2650771712 DatasetCustEOL06 "Dataset Customization EOL 06";
BA_ "GenSigTimeoutTime_PCM" SG_ 2650771712 DatasetCustEOL06 25000;
BA_ "CI_ParId" SG_ 2650771712 DatasetCustEOL05 "F253";
BA_ "CI_SigId" SG_ 2650771712 DatasetCustEOL05 44608;
BA_ "CI_SigName" SG_ 2650771712 DatasetCustEOL05 "Dataset Customization EOL 05";
BA_ "GenSigTimeoutTime_PCM" SG_ 2650771712 DatasetCustEOL05 25000;
BA_ "CI_ParId" SG_ 2650771712 DatasetCustEOL04 "F252";
BA_ "CI_SigId" SG_ 2650771712 DatasetCustEOL04 44607;
BA_ "CI_SigName" SG_ 2650771712 DatasetCustEOL04 "Dataset Customization EOL 04";
BA_ "GenSigTimeoutTime_PCM" SG_ 2650771712 DatasetCustEOL04 25000;
BA_ "CI_ParId" SG_ 2650771712 DatasetCustEOL03 "F251";
BA_ "CI_SigId" SG_ 2650771712 DatasetCustEOL03 42026;
BA_ "CI_SigName" SG_ 2650771712 DatasetCustEOL03 "Dataset Customization EOL 03";
BA_ "GenSigTimeoutTime_PCM" SG_ 2650771712 DatasetCustEOL03 25000;
BA_ "CI_ParId" SG_ 2650771712 DatasetCustEOL02 "F250";
BA_ "CI_SigId" SG_ 2650771712 DatasetCustEOL02 42025;
BA_ "CI_SigName" SG_ 2650771712 DatasetCustEOL02 "Dataset Customization EOL 02";
BA_ "GenSigTimeoutTime_PCM" SG_ 2650771712 DatasetCustEOL02 25000;
BA_ "CI_ParId" SG_ 2650771712 DatasetCustEOL01 "F249";
BA_ "CI_SigId" SG_ 2650771712 DatasetCustEOL01 42021;
BA_ "CI_SigName" SG_ 2650771712 DatasetCustEOL01 "Dataset Customization EOL 01";
BA_ "GenSigTimeoutTime_PCM" SG_ 2650771712 DatasetCustEOL01 25000;
BA_ "CI_ParId" SG_ 2650771712 MinorVer "F248";
BA_ "CI_SigId" SG_ 2650771712 MinorVer 42020;
BA_ "CI_SigName" SG_ 2650771712 MinorVer "Minor Version";
BA_ "GenSigTimeoutTime_PCM" SG_ 2650771712 MinorVer 25000;
BA_ "CI_ParId" SG_ 2650771712 MajorVer "F247";
BA_ "CI_SigId" SG_ 2650771712 MajorVer 42019;
BA_ "CI_SigName" SG_ 2650771712 MajorVer "Major Version";
BA_ "GenSigTimeoutTime_PCM" SG_ 2650771712 MajorVer 25000;
BA_ "CI_ParId" SG_ 2650771968 DatasetCustEOL14 "F262";
BA_ "CI_SigId" SG_ 2650771968 DatasetCustEOL14 44613;
BA_ "CI_SigName" SG_ 2650771968 DatasetCustEOL14 "Dataset Customization EOL 14";
BA_ "GenSigTimeoutTime_PCM" SG_ 2650771968 DatasetCustEOL14 25000;
BA_ "CI_ParId" SG_ 2650771968 DatasetCustEOL13 "F261";
BA_ "CI_SigId" SG_ 2650771968 DatasetCustEOL13 44612;
BA_ "CI_SigName" SG_ 2650771968 DatasetCustEOL13 "Dataset Customization EOL 13";
BA_ "GenSigTimeoutTime_PCM" SG_ 2650771968 DatasetCustEOL13 25000;
BA_ "CI_ParId" SG_ 2650771968 DatasetCustEOL12 "F260";
BA_ "CI_SigId" SG_ 2650771968 DatasetCustEOL12 44611;
BA_ "CI_SigName" SG_ 2650771968 DatasetCustEOL12 "Dataset Customization EOL 12";
BA_ "GenSigTimeoutTime_PCM" SG_ 2650771968 DatasetCustEOL12 25000;
BA_ "CI_ParId" SG_ 2650771968 DatasetCustEOL11 "F259";
BA_ "CI_SigId" SG_ 2650771968 DatasetCustEOL11 44610;
BA_ "CI_SigName" SG_ 2650771968 DatasetCustEOL11 "Dataset Customization EOL 11";
BA_ "GenSigTimeoutTime_PCM" SG_ 2650771968 DatasetCustEOL11 25000;
BA_ "CI_ParId" SG_ 2650771968 DatasetCustEOL10 "F258";
BA_ "CI_SigId" SG_ 2650771968 DatasetCustEOL10 42027;
BA_ "CI_SigName" SG_ 2650771968 DatasetCustEOL10 "Dataset Customization EOL 10";
BA_ "GenSigTimeoutTime_PCM" SG_ 2650771968 DatasetCustEOL10 25000;
BA_ "CI_ParId" SG_ 2650771968 DatasetCustEOL09 "F257";
BA_ "CI_SigId" SG_ 2650771968 DatasetCustEOL09 42024;
BA_ "CI_SigName" SG_ 2650771968 DatasetCustEOL09 "Dataset Customization EOL 09";
BA_ "GenSigTimeoutTime_PCM" SG_ 2650771968 DatasetCustEOL09 25000;
BA_ "CI_ParId" SG_ 2650771968 DatasetCustEOL08 "F256";
BA_ "CI_SigId" SG_ 2650771968 DatasetCustEOL08 42023;
BA_ "CI_SigName" SG_ 2650771968 DatasetCustEOL08 "Dataset Customization EOL 08";
BA_ "GenSigTimeoutTime_PCM" SG_ 2650771968 DatasetCustEOL08 25000;
BA_ "CI_ParId" SG_ 2650771968 DatasetCustEOL07 "F255";
BA_ "CI_SigId" SG_ 2650771968 DatasetCustEOL07 42022;
BA_ "CI_SigName" SG_ 2650771968 DatasetCustEOL07 "Dataset Customization EOL 07";
BA_ "GenSigTimeoutTime_PCM" SG_ 2650771968 DatasetCustEOL07 25000;
BA_ "CI_ParId" SG_ 2650772224 Air_tCACDs "F266";
BA_ "CI_SigId" SG_ 2650772224 Air_tCACDs 44616;
BA_ "CI_SigName" SG_ 2650772224 Air_tCACDs "Temperature down stream of charged air cooler";
BA_ "GenSigTimeoutTime_PCM" SG_ 2650772224 Air_tCACDs 5000;
BA_ "SigType" SG_ 2650772224 Air_tCACDs 2;
BA_ "CI_ParId" SG_ 2650772224 AirCtl_mGovDvtMon_mp "F265";
BA_ "CI_SigId" SG_ 2650772224 AirCtl_mGovDvtMon_mp 44615;
BA_ "CI_SigName" SG_ 2650772224 AirCtl_mGovDvtMon_mp "Mass Governor Deviation Monitoring";
BA_ "GenSigTimeoutTime_PCM" SG_ 2650772224 AirCtl_mGovDvtMon_mp 5000;
BA_ "SigType" SG_ 2650772224 AirCtl_mGovDvtMon_mp 2;
BA_ "CI_ParId" SG_ 2650772224 AirCtl_mActVal "F264";
BA_ "CI_SigId" SG_ 2650772224 AirCtl_mActVal 44614;
BA_ "CI_SigName" SG_ 2650772224 AirCtl_mActVal "Actual value for Air Mass for exhaust gas recirculation";
BA_ "GenSigTimeoutTime_PCM" SG_ 2650772224 AirCtl_mActVal 5000;
BA_ "SigType" SG_ 2650772224 AirCtl_mActVal 2;
BA_ "CI_ParId" SG_ 2650772224 AFS_rNrmFlt_mp "F263";
BA_ "CI_SigId" SG_ 2650772224 AFS_rNrmFlt_mp 43068;
BA_ "CI_SigName" SG_ 2650772224 AFS_rNrmFlt_mp "PT1 filtered ratio of normalized airmass/time to measured airmass/time";
BA_ "GenSigTimeoutTime_PCM" SG_ 2650772224 AFS_rNrmFlt_mp 5000;
BA_ "CI_ParId" SG_ 2650764288 CAClg_etaFlt_mp "F270";
BA_ "CI_SigId" SG_ 2650764288 CAClg_etaFlt_mp 44619;
BA_ "CI_SigName" SG_ 2650764288 CAClg_etaFlt_mp "Filtered CA-cooler efficiency";
BA_ "GenSigTimeoutTime_PCM" SG_ 2650764288 CAClg_etaFlt_mp 5000;
BA_ "SigType" SG_ 2650764288 CAClg_etaFlt_mp 2;
BA_ "CI_ParId" SG_ 2650764288 Air_tIntkVUs "F269";
BA_ "CI_SigId" SG_ 2650764288 Air_tIntkVUs 44618;
BA_ "CI_SigName" SG_ 2650764288 Air_tIntkVUs "Engine Inlet Valve Upstream Air Temperature Device Encapsulation";
BA_ "GenSigTimeoutTime_PCM" SG_ 2650764288 Air_tIntkVUs 5000;
BA_ "SigType" SG_ 2650764288 Air_tIntkVUs 2;
BA_ "CI_ParId" SG_ 2650764288 Air_tEGRClrDs "F268";
BA_ "CI_SigId" SG_ 2650764288 Air_tEGRClrDs 44617;
BA_ "CI_SigName" SG_ 2650764288 Air_tEGRClrDs "EGR cooler down stream temperature";
BA_ "GenSigTimeoutTime_PCM" SG_ 2650764288 Air_tEGRClrDs 5000;
BA_ "SigType" SG_ 2650764288 Air_tEGRClrDs 2;
BA_ "CI_ParId" SG_ 2650764288 Air_tCACUs "F267";
BA_ "CI_SigId" SG_ 2650764288 Air_tCACUs 43069;
BA_ "CI_SigName" SG_ 2650764288 Air_tCACUs "Temperature before the load air cooler";
BA_ "GenSigTimeoutTime_PCM" SG_ 2650764288 Air_tCACUs 5000;
BA_ "SigType" SG_ 2650764288 Air_tCACUs 2;
BA_ "CI_ParId" SG_ 2650764544 DStgyEffMon_mNOxDsMon2_mp "F272";
BA_ "CI_SigId" SG_ 2650764544 DStgyEffMon_mNOxDsMon2_mp 44620;
BA_ "CI_SigName" SG_ 2650764544 DStgyEffMon_mNOxDsMon2_mp "Accumulated mass of NOx downstream (SCR EffMon2)";
BA_ "GenSigTimeoutTime_PCM" SG_ 2650764544 DStgyEffMon_mNOxDsMon2_mp 5000;
BA_ "SigType" SG_ 2650764544 DStgyEffMon_mNOxDsMon2_mp 2;
BA_ "CI_ParId" SG_ 2650764544 CoEOM_stOpModeAct "F271";
BA_ "CI_SigId" SG_ 2650764544 CoEOM_stOpModeAct 37330;
BA_ "CI_SigName" SG_ 2650764544 CoEOM_stOpModeAct "Active operation mode";
BA_ "GenSigTimeoutTime_PCM" SG_ 2650764544 CoEOM_stOpModeAct 5000;
BA_ "SigType" SG_ 2650764544 CoEOM_stOpModeAct 1;
BA_ "CI_ParId" SG_ 2650764800 DStgyEffMon_mNOxUsMon2_mp "F274";
BA_ "CI_SigId" SG_ 2650764800 DStgyEffMon_mNOxUsMon2_mp 44621;
BA_ "CI_SigName" SG_ 2650764800 DStgyEffMon_mNOxUsMon2_mp "Accumulated mass of NOx upstream (SCR EffMon2)";
BA_ "GenSigTimeoutTime_PCM" SG_ 2650764800 DStgyEffMon_mNOxUsMon2_mp 5000;
BA_ "SigType" SG_ 2650764800 DStgyEffMon_mNOxUsMon2_mp 2;
BA_ "CI_ParId" SG_ 2650764800 DStgyEffMon_mNOxDsMon4_mp "F273";
BA_ "CI_SigId" SG_ 2650764800 DStgyEffMon_mNOxDsMon4_mp 37332;
BA_ "CI_SigName" SG_ 2650764800 DStgyEffMon_mNOxDsMon4_mp "Accumulated mass of NOx downstream (SCR EffMon4)";
BA_ "GenSigTimeoutTime_PCM" SG_ 2650764800 DStgyEffMon_mNOxDsMon4_mp 5000;
BA_ "SigType" SG_ 2650764800 DStgyEffMon_mNOxDsMon4_mp 2;
BA_ "CI_ParId" SG_ 2650765056 DStgySys2_cNH3CalcCell1 "F276";
BA_ "CI_SigId" SG_ 2650765056 DStgySys2_cNH3CalcCell1 44622;
BA_ "GenSigTimeoutTime_PCM" SG_ 2650765056 DStgySys2_cNH3CalcCell1 5000;
BA_ "CI_ParId" SG_ 2650765056 DStgyEffMon_mNOxUsMon4_mp "F275";
BA_ "CI_SigId" SG_ 2650765056 DStgyEffMon_mNOxUsMon4_mp 37334;
BA_ "CI_SigName" SG_ 2650765056 DStgyEffMon_mNOxUsMon4_mp "Accumulated mass of NOx upstream (SCR EffMon4)";
BA_ "GenSigTimeoutTime_PCM" SG_ 2650765056 DStgyEffMon_mNOxUsMon4_mp 5000;
BA_ "SigType" SG_ 2650765056 DStgyEffMon_mNOxUsMon4_mp 2;
BA_ "CI_ParId" SG_ 2650765312 DStgy_cNH3CalcCell1 "F280";
BA_ "CI_SigId" SG_ 2650765312 DStgy_cNH3CalcCell1 44625;
BA_ "CI_SigName" SG_ 2650765312 DStgy_cNH3CalcCell1 "Calculated NH3 occupancy of adsorbed NH3 (cell 1)";
BA_ "GenSigTimeoutTime_PCM" SG_ 2650765312 DStgy_cNH3CalcCell1 5000;
BA_ "CI_ParId" SG_ 2650765312 CoSCR_st "F279";
BA_ "CI_SigId" SG_ 2650765312 CoSCR_st 44624;
BA_ "CI_SigName" SG_ 2650765312 CoSCR_st "state of hydraulic SCR-system";
BA_ "GenSigTimeoutTime_PCM" SG_ 2650765312 CoSCR_st 5000;
BA_ "SigType" SG_ 2650765312 CoSCR_st 1;
BA_ "CI_ParId" SG_ 2650765312 CoEng_st "F278";
BA_ "CI_SigId" SG_ 2650765312 CoEng_st 44623;
BA_ "CI_SigName" SG_ 2650765312 CoEng_st "Engine operation status";
BA_ "GenSigTimeoutTime_PCM" SG_ 2650765312 CoEng_st 5000;
BA_ "SigType" SG_ 2650765312 CoEng_st 1;
BA_ "CI_ParId" SG_ 2650765312 DStgySys2_stUreaRlsDisbl "F277";
BA_ "CI_SigId" SG_ 2650765312 DStgySys2_stUreaRlsDisbl 37336;
BA_ "CI_SigName" SG_ 2650765312 DStgySys2_stUreaRlsDisbl "Urea release inhibit condition status";
BA_ "GenSigTimeoutTime_PCM" SG_ 2650765312 DStgySys2_stUreaRlsDisbl 5000;
BA_ "SigType" SG_ 2650765312 DStgySys2_stUreaRlsDisbl 1;
BA_ "CI_ParId" SG_ 2650765568 DStgy_rIntLmbdSensMsLmbdMon_mp "F282";
BA_ "CI_SigId" SG_ 2650765568 DStgy_rIntLmbdSensMsLmbdMon_mp 44626;
BA_ "CI_SigName" SG_ 2650765568 DStgy_rIntLmbdSensMsLmbdMon_mp "Lambda Midstream: integrated Lambda from NOx sensor";
BA_ "GenSigTimeoutTime_PCM" SG_ 2650765568 DStgy_rIntLmbdSensMsLmbdMon_mp 5000;
BA_ "SigType" SG_ 2650765568 DStgy_rIntLmbdSensMsLmbdMon_mp 2;
BA_ "CI_ParId" SG_ 2650765568 DStgy_rIntLmbdSensDsLmbdMon_mp "F281";
BA_ "CI_SigId" SG_ 2650765568 DStgy_rIntLmbdSensDsLmbdMon_mp 37338;
BA_ "CI_SigName" SG_ 2650765568 DStgy_rIntLmbdSensDsLmbdMon_mp "Lambda Downstream: integrated Lambda from NOx sensor";
BA_ "GenSigTimeoutTime_PCM" SG_ 2650765568 DStgy_rIntLmbdSensDsLmbdMon_mp 5000;
BA_ "SigType" SG_ 2650765568 DStgy_rIntLmbdSensDsLmbdMon_mp 2;
BA_ "CI_ParId" SG_ 2650765824 DefTank_volFildDefRmn "F285";
BA_ "CI_SigId" SG_ 2650765824 DefTank_volFildDefRmn 44628;
BA_ "CI_SigName" SG_ 2650765824 DefTank_volFildDefRmn "Filtered remaining DEF volume";
BA_ "GenSigTimeoutTime_PCM" SG_ 2650765824 DefTank_volFildDefRmn 5000;
BA_ "SigType" SG_ 2650765824 DefTank_volFildDefRmn 1;
BA_ "CI_ParId" SG_ 2650765824 DStgy_stUreaRlsDisbl "F284";
BA_ "CI_SigId" SG_ 2650765824 DStgy_stUreaRlsDisbl 44627;
BA_ "CI_SigName" SG_ 2650765824 DStgy_stUreaRlsDisbl "Urea release inhibit condition status";
BA_ "GenSigTimeoutTime_PCM" SG_ 2650765824 DStgy_stUreaRlsDisbl 5000;
BA_ "SigType" SG_ 2650765824 DStgy_stUreaRlsDisbl 1;
BA_ "CI_ParId" SG_ 2650765824 DStgy_rIntLmbdSensUsLmbdMon_mp "F283";
BA_ "CI_SigId" SG_ 2650765824 DStgy_rIntLmbdSensUsLmbdMon_mp 37340;
BA_ "CI_SigName" SG_ 2650765824 DStgy_rIntLmbdSensUsLmbdMon_mp "Lambda Upstream: integrated Lambda from NOx sensor";
BA_ "GenSigTimeoutTime_PCM" SG_ 2650765824 DStgy_rIntLmbdSensUsLmbdMon_mp 5000;
BA_ "SigType" SG_ 2650765824 DStgy_rIntLmbdSensUsLmbdMon_mp 2;
BA_ "CI_ParId" SG_ 2650766080 EGRVlv_rDesVal "F289";
BA_ "CI_SigId" SG_ 2650766080 EGRVlv_rDesVal 44631;
BA_ "CI_SigName" SG_ 2650766080 EGRVlv_rDesVal "Desired position";
BA_ "GenSigTimeoutTime_PCM" SG_ 2650766080 EGRVlv_rDesVal 5000;
BA_ "SigType" SG_ 2650766080 EGRVlv_rDesVal 2;
BA_ "CI_ParId" SG_ 2650766080 EGRVlv_rAct "F288";
BA_ "CI_SigId" SG_ 2650766080 EGRVlv_rAct 44630;
BA_ "CI_SigName" SG_ 2650766080 EGRVlv_rAct "Actuatorposition";
BA_ "GenSigTimeoutTime_PCM" SG_ 2650766080 EGRVlv_rAct 5000;
BA_ "SigType" SG_ 2650766080 EGRVlv_rAct 2;
BA_ "CI_ParId" SG_ 2650766080 EGRClg_tMon_mp "F287";
BA_ "CI_SigId" SG_ 2650766080 EGRClg_tMon_mp 44629;
BA_ "CI_SigName" SG_ 2650766080 EGRClg_tMon_mp "Corrected modelled temperature";
BA_ "GenSigTimeoutTime_PCM" SG_ 2650766080 EGRClg_tMon_mp 5000;
BA_ "SigType" SG_ 2650766080 EGRClg_tMon_mp 2;
BA_ "CI_ParId" SG_ 2650766080 EGRClg_etaFlt "F286";
BA_ "CI_SigId" SG_ 2650766080 EGRClg_etaFlt 37342;
BA_ "CI_SigName" SG_ 2650766080 EGRClg_etaFlt "Filtered EGR-cooler efficiency";
BA_ "GenSigTimeoutTime_PCM" SG_ 2650766080 EGRClg_etaFlt 5000;
BA_ "SigType" SG_ 2650766080 EGRClg_etaFlt 2;
BA_ "CI_ParId" SG_ 2650766336 Exh_rNOxNoCat2Ds "F293";
BA_ "CI_SigId" SG_ 2650766336 Exh_rNOxNoCat2Ds 44634;
BA_ "CI_SigName" SG_ 2650766336 Exh_rNOxNoCat2Ds "NOx emission downstream of secondary catalyst";
BA_ "GenSigTimeoutTime_PCM" SG_ 2650766336 Exh_rNOxNoCat2Ds 5000;
BA_ "SigType" SG_ 2650766336 Exh_rNOxNoCat2Ds 2;
BA_ "CI_ParId" SG_ 2650766336 Exh_iPPDsIDEFild "F292";
BA_ "CI_SigId" SG_ 2650766336 Exh_iPPDsIDEFild 44633;
BA_ "CI_SigName" SG_ 2650766336 Exh_iPPDsIDEFild "PT1 filtered IDE Current value for the monitoring of the diesel-particulate filter";
BA_ "GenSigTimeoutTime_PCM" SG_ 2650766336 Exh_iPPDsIDEFild 5000;
BA_ "SigType" SG_ 2650766336 Exh_iPPDsIDEFild 2;
BA_ "CI_ParId" SG_ 2650766336 EGTCond_dmEG "F291";
BA_ "CI_SigId" SG_ 2650766336 EGTCond_dmEG 44632;
BA_ "CI_SigName" SG_ 2650766336 EGTCond_dmEG "Exhaust gas mass flow";
BA_ "GenSigTimeoutTime_PCM" SG_ 2650766336 EGTCond_dmEG 5000;
BA_ "SigType" SG_ 2650766336 EGTCond_dmEG 2;
BA_ "CI_ParId" SG_ 2650766336 EGRVlv_rPs "F290";
BA_ "CI_SigId" SG_ 2650766336 EGRVlv_rPs 37344;
BA_ "CI_SigName" SG_ 2650766336 EGRVlv_rPs "Duty cycle to power stage";
BA_ "GenSigTimeoutTime_PCM" SG_ 2650766336 EGRVlv_rPs 5000;
BA_ "SigType" SG_ 2650766336 EGRVlv_rPs 2;
BA_ "CI_ParId" SG_ 2650766592 Exh_tPFltDs "F297";
BA_ "CI_SigId" SG_ 2650766592 Exh_tPFltDs 44637;
BA_ "CI_SigName" SG_ 2650766592 Exh_tPFltDs "The downstream temperature in Particle filter";
BA_ "GenSigTimeoutTime_PCM" SG_ 2650766592 Exh_tPFltDs 5000;
BA_ "SigType" SG_ 2650766592 Exh_tPFltDs 2;
BA_ "CI_ParId" SG_ 2650766592 Exh_tOxiCatUs "F296";
BA_ "CI_SigId" SG_ 2650766592 Exh_tOxiCatUs 44636;
BA_ "CI_SigName" SG_ 2650766592 Exh_tOxiCatUs "The upstream temperature in Oxidation Catalyst";
BA_ "GenSigTimeoutTime_PCM" SG_ 2650766592 Exh_tOxiCatUs 5000;
BA_ "SigType" SG_ 2650766592 Exh_tOxiCatUs 2;
BA_ "CI_ParId" SG_ 2650766592 Exh_rNOxPresCompNSCDs "F295";
BA_ "CI_SigId" SG_ 2650766592 Exh_rNOxPresCompNSCDs 44635;
BA_ "CI_SigName" SG_ 2650766592 Exh_rNOxPresCompNSCDs "Pressure compensated NOx signal";
BA_ "GenSigTimeoutTime_PCM" SG_ 2650766592 Exh_rNOxPresCompNSCDs 5000;
BA_ "SigType" SG_ 2650766592 Exh_rNOxPresCompNSCDs 2;
BA_ "CI_ParId" SG_ 2650766592 Exh_rNOxNoCat2Ms "F294";
BA_ "CI_SigId" SG_ 2650766592 Exh_rNOxNoCat2Ms 37346;
BA_ "CI_SigName" SG_ 2650766592 Exh_rNOxNoCat2Ms "Offset corrected NOx signal from post NOx sensor";
BA_ "GenSigTimeoutTime_PCM" SG_ 2650766592 Exh_rNOxNoCat2Ms 5000;
BA_ "SigType" SG_ 2650766592 Exh_rNOxNoCat2Ms 2;
BA_ "CI_ParId" SG_ 2650766848 FBC_qArr_2 "F301";
BA_ "CI_SigId" SG_ 2650766848 FBC_qArr_2 44640;
BA_ "CI_SigName" SG_ 2650766848 FBC_qArr_2 "FBC output quantity, interface for injection system";
BA_ "GenSigTimeoutTime_PCM" SG_ 2650766848 FBC_qArr_2 5000;
BA_ "SigType" SG_ 2650766848 FBC_qArr_2 2;
BA_ "CI_ParId" SG_ 2650766848 FBC_qArr_1 "F300";
BA_ "CI_SigId" SG_ 2650766848 FBC_qArr_1 44639;
BA_ "CI_SigName" SG_ 2650766848 FBC_qArr_1 "FBC output quantity, interface for injection system";
BA_ "GenSigTimeoutTime_PCM" SG_ 2650766848 FBC_qArr_1 5000;
BA_ "SigType" SG_ 2650766848 FBC_qArr_1 2;
BA_ "CI_ParId" SG_ 2650766848 FBC_qArr_0 "F299";
BA_ "CI_SigId" SG_ 2650766848 FBC_qArr_0 44638;
BA_ "CI_SigName" SG_ 2650766848 FBC_qArr_0 "FBC output quantity, interface for injection system";
BA_ "GenSigTimeoutTime_PCM" SG_ 2650766848 FBC_qArr_0 5000;
BA_ "SigType" SG_ 2650766848 FBC_qArr_0 2;
BA_ "CI_ParId" SG_ 2650766848 Exh_tPFltUs "F298";
BA_ "CI_SigId" SG_ 2650766848 Exh_tPFltUs 37348;
BA_ "CI_SigName" SG_ 2650766848 Exh_tPFltUs "The upstream temperature in Particle filter";
BA_ "GenSigTimeoutTime_PCM" SG_ 2650766848 Exh_tPFltUs 5000;
BA_ "SigType" SG_ 2650766848 Exh_tPFltUs 2;
BA_ "CI_ParId" SG_ 2650767104 PCR_swtGov "F305";
BA_ "CI_SigId" SG_ 2650767104 PCR_swtGov 44643;
BA_ "CI_SigName" SG_ 2650767104 PCR_swtGov "Switch value controller on/off";
BA_ "GenSigTimeoutTime_PCM" SG_ 2650767104 PCR_swtGov 5000;
BA_ "SigType" SG_ 2650767104 PCR_swtGov 1;
BA_ "CI_ParId" SG_ 2650767104 Exh_stPPDs "F304";
BA_ "CI_SigId" SG_ 2650767104 Exh_stPPDs 44642;
BA_ "CI_SigName" SG_ 2650767104 Exh_stPPDs "Status of particulate sensor downstream of particulate filter";
BA_ "GenSigTimeoutTime_PCM" SG_ 2650767104 Exh_stPPDs 5000;
BA_ "SigType" SG_ 2650767104 Exh_stPPDs 1;
BA_ "CI_ParId" SG_ 2650767104 GlbDa_lTotDst "F303";
BA_ "CI_SigId" SG_ 2650767104 GlbDa_lTotDst 44641;
BA_ "CI_SigName" SG_ 2650767104 GlbDa_lTotDst "total distance since first start";
BA_ "GenSigTimeoutTime_PCM" SG_ 2650767104 GlbDa_lTotDst 5000;
BA_ "SigType" SG_ 2650767104 GlbDa_lTotDst 2;
BA_ "CI_ParId" SG_ 2650767104 FBC_qArr_3 "F302";
BA_ "CI_SigId" SG_ 2650767104 FBC_qArr_3 37350;
BA_ "CI_SigName" SG_ 2650767104 FBC_qArr_3 "FBC output quantity, interface for injection system";
BA_ "GenSigTimeoutTime_PCM" SG_ 2650767104 FBC_qArr_3 5000;
BA_ "SigType" SG_ 2650767104 FBC_qArr_3 2;
BA_ "CI_ParId" SG_ 2650767360 MeUn_iActFlt "F309";
BA_ "CI_SigId" SG_ 2650767360 MeUn_iActFlt 44646;
BA_ "CI_SigName" SG_ 2650767360 MeUn_iActFlt "Metering unit current control filtered actual current value";
BA_ "GenSigTimeoutTime_PCM" SG_ 2650767360 MeUn_iActFlt 5000;
BA_ "SigType" SG_ 2650767360 MeUn_iActFlt 2;
BA_ "CI_ParId" SG_ 2650767360 MeUn_dvolSet "F308";
BA_ "CI_SigId" SG_ 2650767360 MeUn_dvolSet 44645;
BA_ "CI_SigName" SG_ 2650767360 MeUn_dvolSet "Setpoint value (volume flow) of rail pressure governing";
BA_ "GenSigTimeoutTime_PCM" SG_ 2650767360 MeUn_dvolSet 5000;
BA_ "SigType" SG_ 2650767360 MeUn_dvolSet 2;
BA_ "CI_ParId" SG_ 2650767360 LSU_rLam_0 "F307";
BA_ "CI_SigId" SG_ 2650767360 LSU_rLam_0 44644;
BA_ "CI_SigName" SG_ 2650767360 LSU_rLam_0 "Lambda value measured from LSU";
BA_ "GenSigTimeoutTime_PCM" SG_ 2650767360 LSU_rLam_0 5000;
BA_ "SigType" SG_ 2650767360 LSU_rLam_0 2;
BA_ "CI_ParId" SG_ 2650767360 InjCtl_qSetUnBal "F306";
BA_ "CI_SigId" SG_ 2650767360 InjCtl_qSetUnBal 37352;
BA_ "CI_SigName" SG_ 2650767360 InjCtl_qSetUnBal "current injection quantity";
BA_ "GenSigTimeoutTime_PCM" SG_ 2650767360 InjCtl_qSetUnBal 5000;
BA_ "SigType" SG_ 2650767360 InjCtl_qSetUnBal 2;
BA_ "CI_ParId" SG_ 2650767616 PCR_pGovDvt "F313";
BA_ "CI_SigId" SG_ 2650767616 PCR_pGovDvt 44649;
BA_ "CI_SigName" SG_ 2650767616 PCR_pGovDvt "Control deviation of the pressure charging regulator";
BA_ "GenSigTimeoutTime_PCM" SG_ 2650767616 PCR_pGovDvt 5000;
BA_ "SigType" SG_ 2650767616 PCR_pGovDvt 2;
BA_ "CI_ParId" SG_ 2650767616 PCR_pActVal "F312";
BA_ "CI_SigId" SG_ 2650767616 PCR_pActVal 44648;
BA_ "CI_SigName" SG_ 2650767616 PCR_pActVal "Boost pressure actual value";
BA_ "GenSigTimeoutTime_PCM" SG_ 2650767616 PCR_pActVal 5000;
BA_ "SigType" SG_ 2650767616 PCR_pActVal 2;
BA_ "CI_ParId" SG_ 2650767616 MeUn_rPs "F311";
BA_ "CI_SigId" SG_ 2650767616 MeUn_rPs 44647;
BA_ "CI_SigName" SG_ 2650767616 MeUn_rPs "PWM signal output from the metering unit";
BA_ "GenSigTimeoutTime_PCM" SG_ 2650767616 MeUn_rPs 5000;
BA_ "SigType" SG_ 2650767616 MeUn_rPs 2;
BA_ "CI_ParId" SG_ 2650767616 MeUn_iSet "F310";
BA_ "CI_SigId" SG_ 2650767616 MeUn_iSet 37354;
BA_ "CI_SigName" SG_ 2650767616 MeUn_iSet "Setpoint current for the metering unit";
BA_ "GenSigTimeoutTime_PCM" SG_ 2650767616 MeUn_iSet 5000;
BA_ "SigType" SG_ 2650767616 MeUn_iSet 2;
BA_ "CI_ParId" SG_ 2650767872 PFlt_dvolPFltEGDly_mp "F317";
BA_ "CI_SigId" SG_ 2650767872 PFlt_dvolPFltEGDly_mp 44652;
BA_ "CI_SigName" SG_ 2650767872 PFlt_dvolPFltEGDly_mp "Exhaust gas volume flow corrected by the gas run time";
BA_ "GenSigTimeoutTime_PCM" SG_ 2650767872 PFlt_dvolPFltEGDly_mp 5000;
BA_ "SigType" SG_ 2650767872 PFlt_dvolPFltEGDly_mp 2;
BA_ "CI_ParId" SG_ 2650767872 PCV_rPs "F316";
BA_ "CI_SigId" SG_ 2650767872 PCV_rPs 44651;
BA_ "CI_SigName" SG_ 2650767872 PCV_rPs "Output dutycycle for pressure control valve";
BA_ "GenSigTimeoutTime_PCM" SG_ 2650767872 PCV_rPs 5000;
BA_ "SigType" SG_ 2650767872 PCV_rPs 2;
BA_ "CI_ParId" SG_ 2650767872 PCV_iSet "F315";
BA_ "CI_SigId" SG_ 2650767872 PCV_iSet 44650;
BA_ "CI_SigName" SG_ 2650767872 PCV_iSet "Setpoint current for the pressure control valve";
BA_ "GenSigTimeoutTime_PCM" SG_ 2650767872 PCV_iSet 5000;
BA_ "SigType" SG_ 2650767872 PCV_iSet 2;
BA_ "CI_ParId" SG_ 2650767872 PCV_iActFlt "F314";
BA_ "CI_SigId" SG_ 2650767872 PCV_iActFlt 37356;
BA_ "CI_SigName" SG_ 2650767872 PCV_iActFlt "Pressure setpoint of rail pressure control for the PCV";
BA_ "GenSigTimeoutTime_PCM" SG_ 2650767872 PCV_iActFlt 5000;
BA_ "SigType" SG_ 2650767872 PCV_iActFlt 2;
BA_ "CI_ParId" SG_ 2650768128 Rail_dvolDemSysNom "F321";
BA_ "CI_SigId" SG_ 2650768128 Rail_dvolDemSysNom 44655;
BA_ "CI_SigName" SG_ 2650768128 Rail_dvolDemSysNom "Volume flow requested overall for a nominal injection system";
BA_ "GenSigTimeoutTime_PCM" SG_ 2650768128 Rail_dvolDemSysNom 5000;
BA_ "SigType" SG_ 2650768128 Rail_dvolDemSysNom 2;
BA_ "CI_ParId" SG_ 2650768128 RailP_pFlt "F320";
BA_ "CI_SigId" SG_ 2650768128 RailP_pFlt 44654;
BA_ "CI_SigName" SG_ 2650768128 RailP_pFlt "Maximum rail pressure of the last 10 ms";
BA_ "GenSigTimeoutTime_PCM" SG_ 2650768128 RailP_pFlt 5000;
BA_ "SigType" SG_ 2650768128 RailP_pFlt 2;
BA_ "CI_ParId" SG_ 2650768128 PthSet_trqInrSet "F319";
BA_ "CI_SigId" SG_ 2650768128 PthSet_trqInrSet 44653;
BA_ "CI_SigName" SG_ 2650768128 PthSet_trqInrSet "PthSet: inner torque set value";
BA_ "GenSigTimeoutTime_PCM" SG_ 2650768128 PthSet_trqInrSet 5000;
BA_ "SigType" SG_ 2650768128 PthSet_trqInrSet 2;
BA_ "CI_ParId" SG_ 2650768128 PFlt_rPFltEff "F318";
BA_ "CI_SigId" SG_ 2650768128 PFlt_rPFltEff 37358;
BA_ "CI_SigName" SG_ 2650768128 PFlt_rPFltEff "Integrated inverse predicted release time";
BA_ "GenSigTimeoutTime_PCM" SG_ 2650768128 PFlt_rPFltEff 5000;
BA_ "SigType" SG_ 2650768128 PFlt_rPFltEff 2;
BA_ "CI_ParId" SG_ 2650768384 SCR_tUCatUsT "F326";
BA_ "CI_SigId" SG_ 2650768384 SCR_tUCatUsT 44659;
BA_ "CI_SigName" SG_ 2650768384 SCR_tUCatUsT "Urea catalyst upstream Temperature";
BA_ "GenSigTimeoutTime_PCM" SG_ 2650768384 SCR_tUCatUsT 5000;
BA_ "SigType" SG_ 2650768384 SCR_tUCatUsT 2;
BA_ "CI_ParId" SG_ 2650768384 SCR_tUCatDsT "F325";
BA_ "CI_SigId" SG_ 2650768384 SCR_tUCatDsT 44658;
BA_ "CI_SigName" SG_ 2650768384 SCR_tUCatDsT "Urea catalyst downstream Temperature";
BA_ "GenSigTimeoutTime_PCM" SG_ 2650768384 SCR_tUCatDsT 5000;
BA_ "SigType" SG_ 2650768384 SCR_tUCatDsT 2;
BA_ "CI_ParId" SG_ 2650768384 T15_st "F324";
BA_ "CI_SigId" SG_ 2650768384 T15_st 44657;
BA_ "CI_SigName" SG_ 2650768384 T15_st "Terminal 15 status after debouncing";
BA_ "GenSigTimeoutTime_PCM" SG_ 2650768384 T15_st 5000;
BA_ "SigType" SG_ 2650768384 T15_st 1;
BA_ "CI_ParId" SG_ 2650768384 Rail_stMon "F323";
BA_ "CI_SigId" SG_ 2650768384 Rail_stMon 44656;
BA_ "CI_SigName" SG_ 2650768384 Rail_stMon "State of the high pressure monitoring";
BA_ "GenSigTimeoutTime_PCM" SG_ 2650768384 Rail_stMon 5000;
BA_ "SigType" SG_ 2650768384 Rail_stMon 1;
BA_ "CI_ParId" SG_ 2650768384 Rail_pSetPoint "F322";
BA_ "CI_SigId" SG_ 2650768384 Rail_pSetPoint 37360;
BA_ "CI_SigName" SG_ 2650768384 Rail_pSetPoint "Rail pressure setpoint";
BA_ "GenSigTimeoutTime_PCM" SG_ 2650768384 Rail_pSetPoint 5000;
BA_ "SigType" SG_ 2650768384 Rail_pSetPoint 2;
BA_ "CI_ParId" SG_ 2650768640 TrbCh_rAct "F330";
BA_ "CI_SigId" SG_ 2650768640 TrbCh_rAct 44662;
BA_ "CI_SigName" SG_ 2650768640 TrbCh_rAct "Actuatorposition";
BA_ "GenSigTimeoutTime_PCM" SG_ 2650768640 TrbCh_rAct 5000;
BA_ "SigType" SG_ 2650768640 TrbCh_rAct 2;
BA_ "CI_ParId" SG_ 2650768640 ThrVlv_rPs "F329";
BA_ "CI_SigId" SG_ 2650768640 ThrVlv_rPs 44661;
BA_ "CI_SigName" SG_ 2650768640 ThrVlv_rPs "Duty cycle to power stage";
BA_ "GenSigTimeoutTime_PCM" SG_ 2650768640 ThrVlv_rPs 5000;
BA_ "SigType" SG_ 2650768640 ThrVlv_rPs 2;
BA_ "CI_ParId" SG_ 2650768640 ThrVlv_rDesVal "F328";
BA_ "CI_SigId" SG_ 2650768640 ThrVlv_rDesVal 44660;
BA_ "CI_SigName" SG_ 2650768640 ThrVlv_rDesVal "Desired position throttle valve";
BA_ "GenSigTimeoutTime_PCM" SG_ 2650768640 ThrVlv_rDesVal 5000;
BA_ "SigType" SG_ 2650768640 ThrVlv_rDesVal 2;
BA_ "CI_ParId" SG_ 2650768640 ThrVlv_rAct "F327";
BA_ "CI_SigId" SG_ 2650768640 ThrVlv_rAct 37362;
BA_ "CI_SigName" SG_ 2650768640 ThrVlv_rAct "Actuatorposition throttle valve";
BA_ "GenSigTimeoutTime_PCM" SG_ 2650768640 ThrVlv_rAct 5000;
BA_ "SigType" SG_ 2650768640 ThrVlv_rAct 2;
BA_ "CI_ParId" SG_ 2650768896 UDC_dmRdcAgDesDosVlv2 "F334";
BA_ "CI_SigId" SG_ 2650768896 UDC_dmRdcAgDesDosVlv2 44665;
BA_ "CI_SigName" SG_ 2650768896 UDC_dmRdcAgDesDosVlv2 "required reducing agent-mass flow for second dosing valve";
BA_ "GenSigTimeoutTime_PCM" SG_ 2650768896 UDC_dmRdcAgDesDosVlv2 5000;
BA_ "SigType" SG_ 2650768896 UDC_dmRdcAgDesDosVlv2 2;
BA_ "CI_ParId" SG_ 2650768896 UDC_dmRdcAgDes "F333";
BA_ "CI_SigId" SG_ 2650768896 UDC_dmRdcAgDes 44664;
BA_ "CI_SigName" SG_ 2650768896 UDC_dmRdcAgDes "required reducing agent-mass flow";
BA_ "GenSigTimeoutTime_PCM" SG_ 2650768896 UDC_dmRdcAgDes 5000;
BA_ "SigType" SG_ 2650768896 UDC_dmRdcAgDes 2;
BA_ "CI_ParId" SG_ 2650768896 TrbCh_rPs "F332";
BA_ "CI_SigId" SG_ 2650768896 TrbCh_rPs 44663;
BA_ "CI_SigName" SG_ 2650768896 TrbCh_rPs "Duty cycle to power stage";
BA_ "GenSigTimeoutTime_PCM" SG_ 2650768896 TrbCh_rPs 5000;
BA_ "SigType" SG_ 2650768896 TrbCh_rPs 2;
BA_ "CI_ParId" SG_ 2650768896 TrbCh_rGovDvt "F331";
BA_ "CI_SigId" SG_ 2650768896 TrbCh_rGovDvt 37364;
BA_ "CI_SigName" SG_ 2650768896 TrbCh_rGovDvt "control deviation";
BA_ "GenSigTimeoutTime_PCM" SG_ 2650768896 TrbCh_rGovDvt 5000;
BA_ "SigType" SG_ 2650768896 TrbCh_rGovDvt 2;
BA_ "CI_ParId" SG_ 2650769152 UDosVlv_tiInjTot "F337";
BA_ "CI_SigId" SG_ 2650769152 UDosVlv_tiInjTot 44667;
BA_ "CI_SigName" SG_ 2650769152 UDosVlv_tiInjTot "Total opening time of dosing valve";
BA_ "GenSigTimeoutTime_PCM" SG_ 2650769152 UDosVlv_tiInjTot 5000;
BA_ "SigType" SG_ 2650769152 UDosVlv_tiInjTot 2;
BA_ "CI_ParId" SG_ 2650769152 UDC_dmRednAgtAvrgDosVlv2 "F336";
BA_ "CI_SigId" SG_ 2650769152 UDC_dmRednAgtAvrgDosVlv2 44666;
BA_ "CI_SigName" SG_ 2650769152 UDC_dmRednAgtAvrgDosVlv2 "Average dosed quantity for second dosing valve";
BA_ "GenSigTimeoutTime_PCM" SG_ 2650769152 UDC_dmRednAgtAvrgDosVlv2 5000;
BA_ "SigType" SG_ 2650769152 UDC_dmRednAgtAvrgDosVlv2 2;
BA_ "CI_ParId" SG_ 2650769152 UDC_dmRednAgtAvrg "F335";
BA_ "CI_SigId" SG_ 2650769152 UDC_dmRednAgtAvrg 37366;
BA_ "CI_SigName" SG_ 2650769152 UDC_dmRednAgtAvrg "Average dosed quantity";
BA_ "GenSigTimeoutTime_PCM" SG_ 2650769152 UDC_dmRednAgtAvrg 5000;
BA_ "SigType" SG_ 2650769152 UDC_dmRednAgtAvrg 2;
BA_ "CI_ParId" SG_ 2650769408 UrTLCSnsr_ratConcSens "F340";
BA_ "CI_SigId" SG_ 2650769408 UrTLCSnsr_ratConcSens 44669;
BA_ "CI_SigName" SG_ 2650769408 UrTLCSnsr_ratConcSens "DEF Concentration sensed by the TLC sensor";
BA_ "GenSigTimeoutTime_PCM" SG_ 2650769408 UrTLCSnsr_ratConcSens 5000;
BA_ "SigType" SG_ 2650769408 UrTLCSnsr_ratConcSens 2;
BA_ "CI_ParId" SG_ 2650769408 UrPSnsr_pFild "F339";
BA_ "CI_SigId" SG_ 2650769408 UrPSnsr_pFild 44668;
BA_ "CI_SigName" SG_ 2650769408 UrPSnsr_pFild "Filtered system pressure";
BA_ "GenSigTimeoutTime_PCM" SG_ 2650769408 UrPSnsr_pFild 5000;
BA_ "SigType" SG_ 2650769408 UrPSnsr_pFild 2;
BA_ "CI_ParId" SG_ 2650769408 UDosVlv_tiInjTotVlv2 "F338";
BA_ "CI_SigId" SG_ 2650769408 UDosVlv_tiInjTotVlv2 37368;
BA_ "CI_SigName" SG_ 2650769408 UDosVlv_tiInjTotVlv2 "Total opening time of second dosing valve";
BA_ "GenSigTimeoutTime_PCM" SG_ 2650769408 UDosVlv_tiInjTotVlv2 5000;
BA_ "SigType" SG_ 2650769408 UDosVlv_tiInjTotVlv2 2;
BA_ "CI_ParId" SG_ 2650769664 OilLfT_rRmnEngOilLfT "F345";
BA_ "CI_SigId" SG_ 2650769664 OilLfT_rRmnEngOilLfT 44673;
BA_ "CI_SigName" SG_ 2650769664 OilLfT_rRmnEngOilLfT "Remaining engine oil life in percentage";
BA_ "GenSigTimeoutTime_PCM" SG_ 2650769664 OilLfT_rRmnEngOilLfT 5000;
BA_ "SigType" SG_ 2650769664 OilLfT_rRmnEngOilLfT 1;
BA_ "CI_ParId" SG_ 2650769664 Oil_pSwmp "F344";
BA_ "CI_SigId" SG_ 2650769664 Oil_pSwmp 44672;
BA_ "CI_SigName" SG_ 2650769664 Oil_pSwmp "Oil pressure value filtered for sending via CAN";
BA_ "GenSigTimeoutTime_PCM" SG_ 2650769664 Oil_pSwmp 5000;
BA_ "SigType" SG_ 2650769664 Oil_pSwmp 2;
BA_ "CI_ParId" SG_ 2650769664 EnvT_t "F343";
BA_ "CI_SigId" SG_ 2650769664 EnvT_t 44671;
BA_ "CI_SigName" SG_ 2650769664 EnvT_t "Environment temperature signal (with replacement reaction in case of sensor error)";
BA_ "GenSigTimeoutTime_PCM" SG_ 2650769664 EnvT_t 5000;
BA_ "SigType" SG_ 2650769664 EnvT_t 2;
BA_ "CI_ParId" SG_ 2650769664 Tra_numGear "F342";
BA_ "CI_SigId" SG_ 2650769664 Tra_numGear 44670;
BA_ "CI_SigName" SG_ 2650769664 Tra_numGear "Current gear information";
BA_ "GenSigTimeoutTime_PCM" SG_ 2650769664 Tra_numGear 5000;
BA_ "SigType" SG_ 2650769664 Tra_numGear 2;
BA_ "CI_ParId" SG_ 2650769664 UrTLCSnsr_t "F341";
BA_ "CI_SigId" SG_ 2650769664 UrTLCSnsr_t 37370;
BA_ "CI_SigName" SG_ 2650769664 UrTLCSnsr_t "temperature measured by the TLC sensor";
BA_ "GenSigTimeoutTime_PCM" SG_ 2650769664 UrTLCSnsr_t 5000;
BA_ "SigType" SG_ 2650769664 UrTLCSnsr_t 2;
BA_ "CI_ParId" SG_ 2650769920 PFltLd_resFlw "F349";
BA_ "CI_SigId" SG_ 2650769920 PFltLd_resFlw 44676;
BA_ "CI_SigName" SG_ 2650769920 PFltLd_resFlw "Flow resistance of the particulate filter";
BA_ "GenSigTimeoutTime_PCM" SG_ 2650769920 PFltLd_resFlw 5000;
BA_ "SigType" SG_ 2650769920 PFltLd_resFlw 2;
BA_ "CI_ParId" SG_ 2650769920 SCRMon_nrLftTotCurrDcyc "F348";
BA_ "CI_SigId" SG_ 2650769920 SCRMon_nrLftTotCurrDcyc 44675;
BA_ "CI_SigName" SG_ 2650769920 SCRMon_nrLftTotCurrDcyc "Total number of pump strokes during pressure buildup in this driving cycle";
BA_ "GenSigTimeoutTime_PCM" SG_ 2650769920 SCRMon_nrLftTotCurrDcyc 5000;
BA_ "SigType" SG_ 2650769920 SCRMon_nrLftTotCurrDcyc 1;
BA_ "CI_ParId" SG_ 2650769920 ITEM_frctSOIO2 "F347";
BA_ "CI_SigId" SG_ 2650769920 ITEM_frctSOIO2 44674;
BA_ "CI_SigName" SG_ 2650769920 ITEM_frctSOIO2 "Correction factor for low temperature combustion";
BA_ "GenSigTimeoutTime_PCM" SG_ 2650769920 ITEM_frctSOIO2 5000;
BA_ "SigType" SG_ 2650769920 ITEM_frctSOIO2 2;
BA_ "CI_ParId" SG_ 2650769920 AFS_dm "F346";
BA_ "CI_SigId" SG_ 2650769920 AFS_dm 37372;
BA_ "CI_SigName" SG_ 2650769920 AFS_dm "Sensed fresh air mass flow";
BA_ "GenSigTimeoutTime_PCM" SG_ 2650769920 AFS_dm 5000;
BA_ "SigType" SG_ 2650769920 AFS_dm 2;
BA_ "CI_ParId" SG_ 2650770176 OilLfT_rRmnDst "F354";
BA_ "CI_SigId" SG_ 2650770176 OilLfT_rRmnDst 44680;
BA_ "CI_SigName" SG_ 2650770176 OilLfT_rRmnDst "Remaining engine oil life based on covered mileage";
BA_ "GenSigTimeoutTime_PCM" SG_ 2650770176 OilLfT_rRmnDst 5000;
BA_ "SigType" SG_ 2650770176 OilLfT_rRmnDst 1;
BA_ "CI_ParId" SG_ 2650770176 OilLfT_rRmnRgn "F353";
BA_ "CI_SigId" SG_ 2650770176 OilLfT_rRmnRgn 44679;
BA_ "CI_SigName" SG_ 2650770176 OilLfT_rRmnRgn "Remaining engine oil life based on DPF regeneration";
BA_ "GenSigTimeoutTime_PCM" SG_ 2650770176 OilLfT_rRmnRgn 5000;
BA_ "SigType" SG_ 2650770176 OilLfT_rRmnRgn 1;
BA_ "CI_ParId" SG_ 2650770176 PFltLd_mSot "F352";
BA_ "CI_SigId" SG_ 2650770176 PFltLd_mSot 44678;
BA_ "CI_SigName" SG_ 2650770176 PFltLd_mSot "Soot mass in the particulate filter";
BA_ "GenSigTimeoutTime_PCM" SG_ 2650770176 PFltLd_mSot 5000;
BA_ "SigType" SG_ 2650770176 PFltLd_mSot 2;
BA_ "CI_ParId" SG_ 2650770176 PFlt_lRgnMean "F351";
BA_ "CI_SigId" SG_ 2650770176 PFlt_lRgnMean 44677;
BA_ "CI_SigName" SG_ 2650770176 PFlt_lRgnMean "Mean distance of since regeneration";
BA_ "GenSigTimeoutTime_PCM" SG_ 2650770176 PFlt_lRgnMean 5000;
BA_ "SigType" SG_ 2650770176 PFlt_lRgnMean 2;
BA_ "CI_ParId" SG_ 2650770176 PFlt_tiRgnMean "F350";
BA_ "CI_SigId" SG_ 2650770176 PFlt_tiRgnMean 37374;
BA_ "CI_SigName" SG_ 2650770176 PFlt_tiRgnMean "Mean Time since last regeneration";
BA_ "GenSigTimeoutTime_PCM" SG_ 2650770176 PFlt_tiRgnMean 5000;
BA_ "SigType" SG_ 2650770176 PFlt_tiRgnMean 2;
BA_ "CI_ParId" SG_ 2650770432 AFS_dmDrft "F358";
BA_ "CI_SigId" SG_ 2650770432 AFS_dmDrft 44683;
BA_ "CI_SigName" SG_ 2650770432 AFS_dmDrft "Compensated Air mass value for the drift";
BA_ "GenSigTimeoutTime_PCM" SG_ 2650770432 AFS_dmDrft 5000;
BA_ "SigType" SG_ 2650770432 AFS_dmDrft 2;
BA_ "CI_ParId" SG_ 2650770432 InjCtl_qRaw "F357";
BA_ "CI_SigId" SG_ 2650770432 InjCtl_qRaw 44682;
BA_ "CI_SigName" SG_ 2650770432 InjCtl_qRaw "raw value of injection mass";
BA_ "GenSigTimeoutTime_PCM" SG_ 2650770432 InjCtl_qRaw 5000;
BA_ "SigType" SG_ 2650770432 InjCtl_qRaw 2;
BA_ "CI_ParId" SG_ 2650770432 FMO_qCor "F356";
BA_ "CI_SigId" SG_ 2650770432 FMO_qCor 44681;
BA_ "CI_SigName" SG_ 2650770432 FMO_qCor "Correction quantity from the observer";
BA_ "GenSigTimeoutTime_PCM" SG_ 2650770432 FMO_qCor 5000;
BA_ "SigType" SG_ 2650770432 FMO_qCor 2;
BA_ "CI_ParId" SG_ 2650770432 ActMod_trqClth "F355";
BA_ "CI_SigId" SG_ 2650770432 ActMod_trqClth 37376;
BA_ "CI_SigName" SG_ 2650770432 ActMod_trqClth "actual engine torque - clutch torque";
BA_ "GenSigTimeoutTime_PCM" SG_ 2650770432 ActMod_trqClth 5000;
BA_ "SigType" SG_ 2650770432 ActMod_trqClth 2;
BA_ "CI_ParId" SG_ 2583640871 PriEptoEnergyCons "ID2606";
BA_ "CI_SigId" SG_ 2583640871 PriEptoEnergyCons 45658;
BA_ "CI_SigName" SG_ 2583640871 PriEptoEnergyCons "Primary ePTO Energy Consumption";
BA_ "GenSigTimeoutTime_PCM" SG_ 2583640871 PriEptoEnergyCons 50000;
BA_ "SigType" SG_ 2583640871 PriEptoEnergyCons 1;
BA_ "CI_ParId" SG_ 2583640871 TotTractEnergyCons "ID2073";
BA_ "CI_SigId" SG_ 2583640871 TotTractEnergyCons 40409;
BA_ "CI_SigName" SG_ 2583640871 TotTractEnergyCons "Total Traction Energy Consumption";
BA_ "GenSigTimeoutTime_PCM" SG_ 2583640871 TotTractEnergyCons 50000;
BA_ "SigType" SG_ 2583640871 TotTractEnergyCons 1;
BA_ "CI_ParId" SG_ 2583640615 TotEnergyRecoveredWithBrks "ID2076";
BA_ "CI_SigId" SG_ 2583640615 TotEnergyRecoveredWithBrks 41786;
BA_ "CI_SigName" SG_ 2583640615 TotEnergyRecoveredWithBrks "Total Energy Recovered with Brakes";
BA_ "GenSigTimeoutTime_PCM" SG_ 2583640615 TotEnergyRecoveredWithBrks 50000;
BA_ "SigType" SG_ 2583640615 TotEnergyRecoveredWithBrks 1;
BA_ "CI_ParId" SG_ 2583640615 TotHvacEnergyCons "ID2075";
BA_ "CI_SigId" SG_ 2583640615 TotHvacEnergyCons 41785;
BA_ "CI_SigName" SG_ 2583640615 TotHvacEnergyCons "Total HVAC Energy Consumption";
BA_ "GenSigTimeoutTime_PCM" SG_ 2583640615 TotHvacEnergyCons 50000;
BA_ "SigType" SG_ 2583640615 TotHvacEnergyCons 1;
BA_ "CI_ParId" SG_ 2583636764 TsrDualCarriageWaySLStart "ID2491";
BA_ "CI_SigId" SG_ 2583636764 TsrDualCarriageWaySLStart 44606;
BA_ "CI_SigName" SG_ 2583636764 TsrDualCarriageWaySLStart "TSR Dual carriage way Speed Limit start";
BA_ "GenSigTimeoutTime_SGW" SG_ 2583636764 TsrDualCarriageWaySLStart 50000;
BA_ "CI_ParId" SG_ 2583636764 TsrSingleCarriageWaySLStart "ID2490";
BA_ "CI_SigId" SG_ 2583636764 TsrSingleCarriageWaySLStart 44605;
BA_ "CI_SigName" SG_ 2583636764 TsrSingleCarriageWaySLStart "TSR Single carriage way Speed Limit Start";
BA_ "GenSigTimeoutTime_SGW" SG_ 2583636764 TsrSingleCarriageWaySLStart 50000;
BA_ "CI_ParId" SG_ 2583636764 TsrPlaystreetResidentialSLStart "ID2489";
BA_ "CI_SigId" SG_ 2583636764 TsrPlaystreetResidentialSLStart 44604;
BA_ "CI_SigName" SG_ 2583636764 TsrPlaystreetResidentialSLStart "TSR Playstreet Residential Speed Limit Start";
BA_ "GenSigTimeoutTime_SGW" SG_ 2583636764 TsrPlaystreetResidentialSLStart 50000;
BA_ "CI_ParId" SG_ 2583636764 TsrCityBuildUpSLStart "ID2488";
BA_ "CI_SigId" SG_ 2583636764 TsrCityBuildUpSLStart 44603;
BA_ "CI_SigName" SG_ 2583636764 TsrCityBuildUpSLStart "TSR City BuildUp Speed Limit Start";
BA_ "GenSigTimeoutTime_SGW" SG_ 2583636764 TsrCityBuildUpSLStart 50000;
BA_ "CI_ParId" SG_ 2583636764 TsrMotwaySLStart "ID2487";
BA_ "CI_SigId" SG_ 2583636764 TsrMotwaySLStart 44602;
BA_ "CI_SigName" SG_ 2583636764 TsrMotwaySLStart "TSR Motorway Speed Limit Start";
BA_ "GenSigTimeoutTime_SGW" SG_ 2583636764 TsrMotwaySLStart 50000;
BA_ "CI_ParId" SG_ 2566909770 VmuWakeUp "ID2123";
BA_ "CI_SigId" SG_ 2566909770 VmuWakeUp 41678;
BA_ "CI_SigName" SG_ 2566909770 VmuWakeUp "VMU Wake Up";
BA_ "GenSigTimeoutTime_SGW" SG_ 2566909770 VmuWakeUp 500;
BA_ "SigType" SG_ 2566909770 VmuWakeUp 4;
BA_ "CI_ParId" SG_ 2566867182 SignifTimeOverlapInUsedDrivActiv "V075";
BA_ "CI_SigId" SG_ 2566867182 SignifTimeOverlapInUsedDrivActiv 1752;
BA_ "CI_SigName" SG_ 2566867182 SignifTimeOverlapInUsedDrivActiv "Significant time overlap in used driver activities";
BA_ "GenSigSendType" SG_ 2566867182 SignifTimeOverlapInUsedDrivActiv 3;
BA_ "GenSigTimeoutTime_PCM" SG_ 2566867182 SignifTimeOverlapInUsedDrivActiv 300000;
BA_ "SigType" SG_ 2566867182 SignifTimeOverlapInUsedDrivActiv 4;
BA_ "CI_ParId" SG_ 2566867182 MultiManningCurShift "V074";
BA_ "CI_SigId" SG_ 2566867182 MultiManningCurShift 1751;
BA_ "CI_SigName" SG_ 2566867182 MultiManningCurShift "Multi-manning for the current shift";
BA_ "GenSigSendType" SG_ 2566867182 MultiManningCurShift 3;
BA_ "GenSigTimeoutTime_PCM" SG_ 2566867182 MultiManningCurShift 300000;
BA_ "SigType" SG_ 2566867182 MultiManningCurShift 4;
BA_ "CI_ParId" SG_ 2566867182 WeekRestPerCalcEna "V073";
BA_ "CI_SigId" SG_ 2566867182 WeekRestPerCalcEna 1750;
BA_ "CI_SigName" SG_ 2566867182 WeekRestPerCalcEna "Weekly rest periods calculation enabled";
BA_ "GenSigSendType" SG_ 2566867182 WeekRestPerCalcEna 3;
BA_ "GenSigTimeoutTime_PCM" SG_ 2566867182 WeekRestPerCalcEna 300000;
BA_ "SigType" SG_ 2566867182 WeekRestPerCalcEna 4;
BA_ "CI_ParId" SG_ 2566867182 NoSuffDataOnTheDrivCard "V072";
BA_ "CI_SigId" SG_ 2566867182 NoSuffDataOnTheDrivCard 1749;
BA_ "CI_SigName" SG_ 2566867182 NoSuffDataOnTheDrivCard "No sufficient data on the driver card";
BA_ "GenSigSendType" SG_ 2566867182 NoSuffDataOnTheDrivCard 3;
BA_ "GenSigTimeoutTime_PCM" SG_ 2566867182 NoSuffDataOnTheDrivCard 300000;
BA_ "SigType" SG_ 2566867182 NoSuffDataOnTheDrivCard 4;
BA_ "CI_ParId" SG_ 2566867182 UnknownPer "V071";
BA_ "CI_SigId" SG_ 2566867182 UnknownPer 1748;
BA_ "CI_SigName" SG_ 2566867182 UnknownPer "Unknown periods";
BA_ "GenSigSendType" SG_ 2566867182 UnknownPer 3;
BA_ "GenSigTimeoutTime_PCM" SG_ 2566867182 UnknownPer 300000;
BA_ "SigType" SG_ 2566867182 UnknownPer 4;
BA_ "CI_ParId" SG_ 2566867182 RemReducDayRestPer "V070";
BA_ "CI_SigId" SG_ 2566867182 RemReducDayRestPer 1747;
BA_ "CI_SigName" SG_ 2566867182 RemReducDayRestPer "Remaining reduced daily rest periods";
BA_ "GenSigSendType" SG_ 2566867182 RemReducDayRestPer 3;
BA_ "GenSigTimeoutTime_PCM" SG_ 2566867182 RemReducDayRestPer 300000;
BA_ "CI_ParId" SG_ 2566867182 Rem10HDrivTimes "V069";
BA_ "CI_SigId" SG_ 2566867182 Rem10HDrivTimes 1746;
BA_ "CI_SigName" SG_ 2566867182 Rem10HDrivTimes "Remaining 10 h driving times";
BA_ "GenSigSendType" SG_ 2566867182 Rem10HDrivTimes 3;
BA_ "GenSigTimeoutTime_PCM" SG_ 2566867182 Rem10HDrivTimes 300000;
BA_ "CI_ParId" SG_ 2566867182 OpenCompIn2ndWeekBefLast "V067";
BA_ "CI_SigId" SG_ 2566867182 OpenCompIn2ndWeekBefLast 1745;
BA_ "CI_SigName" SG_ 2566867182 OpenCompIn2ndWeekBefLast "Open compensation in the 2nd week before last";
BA_ "GenSigSendType" SG_ 2566867182 OpenCompIn2ndWeekBefLast 3;
BA_ "GenSigTimeoutTime_PCM" SG_ 2566867182 OpenCompIn2ndWeekBefLast 300000;
BA_ "SigType" SG_ 2566867182 OpenCompIn2ndWeekBefLast 1;
BA_ "CI_ParId" SG_ 2566867182 OpenCompInWeekBefLast "V066";
BA_ "CI_SigId" SG_ 2566867182 OpenCompInWeekBefLast 1744;
BA_ "CI_SigName" SG_ 2566867182 OpenCompInWeekBefLast "Open compensation in the week before last";
BA_ "GenSigSendType" SG_ 2566867182 OpenCompInWeekBefLast 3;
BA_ "GenSigTimeoutTime_PCM" SG_ 2566867182 OpenCompInWeekBefLast 300000;
BA_ "SigType" SG_ 2566867182 OpenCompInWeekBefLast 1;
BA_ "CI_ParId" SG_ 2566867182 OpenCompInLw "V065";
BA_ "CI_SigId" SG_ 2566867182 OpenCompInLw 1743;
BA_ "CI_SigName" SG_ 2566867182 OpenCompInLw "Open compensation in the last week";
BA_ "GenSigSendType" SG_ 2566867182 OpenCompInLw 3;
BA_ "GenSigTimeoutTime_PCM" SG_ 2566867182 OpenCompInLw 300000;
BA_ "SigType" SG_ 2566867182 OpenCompInLw 1;
BA_ "CI_ParId" SG_ 2566867182 DurOfNwlyRestPer "V064";
BA_ "CI_SigId" SG_ 2566867182 DurOfNwlyRestPer 1742;
BA_ "CI_SigName" SG_ 2566867182 DurOfNwlyRestPer "Duration of next weekly rest period";
BA_ "GenSigSendType" SG_ 2566867182 DurOfNwlyRestPer 3;
BA_ "GenSigTimeoutTime_PCM" SG_ 2566867182 DurOfNwlyRestPer 300000;
BA_ "SigType" SG_ 2566867182 DurOfNwlyRestPer 1;
BA_ "CI_ParId" SG_ 2566867182 RemTimeTillNwlyRestPer "V063";
BA_ "CI_SigId" SG_ 2566867182 RemTimeTillNwlyRestPer 1741;
BA_ "CI_SigName" SG_ 2566867182 RemTimeTillNwlyRestPer "Remaining time till next weekly rest period";
BA_ "GenSigSendType" SG_ 2566867182 RemTimeTillNwlyRestPer 3;
BA_ "GenSigTimeoutTime_PCM" SG_ 2566867182 RemTimeTillNwlyRestPer 300000;
BA_ "SigType" SG_ 2566867182 RemTimeTillNwlyRestPer 1;
BA_ "CI_ParId" SG_ 2566867182 RemDrivTimeOfCw "V062";
BA_ "CI_SigId" SG_ 2566867182 RemDrivTimeOfCw 1740;
BA_ "CI_SigName" SG_ 2566867182 RemDrivTimeOfCw "Remaining driving time of current week";
BA_ "GenSigSendType" SG_ 2566867182 RemDrivTimeOfCw 3;
BA_ "GenSigTimeoutTime_PCM" SG_ 2566867182 RemDrivTimeOfCw 300000;
BA_ "SigType" SG_ 2566867182 RemDrivTimeOfCw 1;
BA_ "CI_ParId" SG_ 2566867182 DurOfNextDayRestPer "V061";
BA_ "CI_SigId" SG_ 2566867182 DurOfNextDayRestPer 1739;
BA_ "CI_SigName" SG_ 2566867182 DurOfNextDayRestPer "Duration of next daily rest period";
BA_ "GenSigSendType" SG_ 2566867182 DurOfNextDayRestPer 3;
BA_ "GenSigTimeoutTime_PCM" SG_ 2566867182 DurOfNextDayRestPer 300000;
BA_ "SigType" SG_ 2566867182 DurOfNextDayRestPer 1;
BA_ "CI_ParId" SG_ 2566867182 RemTimeTillNextDayRestPer "V060";
BA_ "CI_SigId" SG_ 2566867182 RemTimeTillNextDayRestPer 1738;
BA_ "CI_SigName" SG_ 2566867182 RemTimeTillNextDayRestPer "Remaining time till next daily rest period";
BA_ "GenSigSendType" SG_ 2566867182 RemTimeTillNextDayRestPer 3;
BA_ "GenSigTimeoutTime_PCM" SG_ 2566867182 RemTimeTillNextDayRestPer 300000;
BA_ "SigType" SG_ 2566867182 RemTimeTillNextDayRestPer 1;
BA_ "CI_ParId" SG_ 2566867182 RemCurDayDrivTime "V059";
BA_ "CI_SigId" SG_ 2566867182 RemCurDayDrivTime 1737;
BA_ "CI_SigName" SG_ 2566867182 RemCurDayDrivTime "Remaining current daily driving time";
BA_ "GenSigSendType" SG_ 2566867182 RemCurDayDrivTime 3;
BA_ "GenSigTimeoutTime_PCM" SG_ 2566867182 RemCurDayDrivTime 300000;
BA_ "SigType" SG_ 2566867182 RemCurDayDrivTime 1;
BA_ "CI_ParId" SG_ 2566867182 DurOfNextDrivPer "V058";
BA_ "CI_SigId" SG_ 2566867182 DurOfNextDrivPer 1736;
BA_ "CI_SigName" SG_ 2566867182 DurOfNextDrivPer "Duration of next driving period ";
BA_ "GenSigSendType" SG_ 2566867182 DurOfNextDrivPer 3;
BA_ "GenSigTimeoutTime_PCM" SG_ 2566867182 DurOfNextDrivPer 300000;
BA_ "SigType" SG_ 2566867182 DurOfNextDrivPer 1;
BA_ "CI_ParId" SG_ 2566867182 TimeBefStartOfNextDrivPer "V057";
BA_ "CI_SigId" SG_ 2566867182 TimeBefStartOfNextDrivPer 1735;
BA_ "CI_SigName" SG_ 2566867182 TimeBefStartOfNextDrivPer "Time before start of next driving period";
BA_ "GenSigSendType" SG_ 2566867182 TimeBefStartOfNextDrivPer 3;
BA_ "GenSigTimeoutTime_PCM" SG_ 2566867182 TimeBefStartOfNextDrivPer 300000;
BA_ "SigType" SG_ 2566867182 TimeBefStartOfNextDrivPer 1;
BA_ "CI_ParId" SG_ 2566867182 RemDurOfCurBreak_Rest "V056";
BA_ "CI_SigId" SG_ 2566867182 RemDurOfCurBreak_Rest 1734;
BA_ "CI_SigName" SG_ 2566867182 RemDurOfCurBreak_Rest "Remaining duration of current break/rest";
BA_ "GenSigSendType" SG_ 2566867182 RemDurOfCurBreak_Rest 3;
BA_ "GenSigTimeoutTime_PCM" SG_ 2566867182 RemDurOfCurBreak_Rest 300000;
BA_ "SigType" SG_ 2566867182 RemDurOfCurBreak_Rest 1;
BA_ "CI_ParId" SG_ 2566867182 DurOfNextRest_Break "V055";
BA_ "CI_SigId" SG_ 2566867182 DurOfNextRest_Break 1733;
BA_ "CI_SigName" SG_ 2566867182 DurOfNextRest_Break "Duration of next rest/break";
BA_ "GenSigSendType" SG_ 2566867182 DurOfNextRest_Break 3;
BA_ "GenSigTimeoutTime_PCM" SG_ 2566867182 DurOfNextRest_Break 300000;
BA_ "SigType" SG_ 2566867182 DurOfNextRest_Break 1;
BA_ "CI_ParId" SG_ 2566867182 RemTimeTillNextRest_Break "V054";
BA_ "CI_SigId" SG_ 2566867182 RemTimeTillNextRest_Break 1732;
BA_ "CI_SigName" SG_ 2566867182 RemTimeTillNextRest_Break "Remaining time till next rest/break";
BA_ "GenSigSendType" SG_ 2566867182 RemTimeTillNextRest_Break 3;
BA_ "GenSigTimeoutTime_PCM" SG_ 2566867182 RemTimeTillNextRest_Break 300000;
BA_ "SigType" SG_ 2566867182 RemTimeTillNextRest_Break 1;
BA_ "CI_ParId" SG_ 2566867182 RemCurDrivTime "V053";
BA_ "CI_SigId" SG_ 2566867182 RemCurDrivTime 1731;
BA_ "CI_SigName" SG_ 2566867182 RemCurDrivTime "Remaining current driving time";
BA_ "GenSigSendType" SG_ 2566867182 RemCurDrivTime 3;
BA_ "GenSigTimeoutTime_PCM" SG_ 2566867182 RemCurDrivTime 300000;
BA_ "SigType" SG_ 2566867182 RemCurDrivTime 1;
BA_ "CI_ParId" SG_ 2566867694 CwWorkTime "V094";
BA_ "CI_SigId" SG_ 2566867694 CwWorkTime 1775;
BA_ "CI_SigName" SG_ 2566867694 CwWorkTime "Current week working time";
BA_ "GenSigSendType" SG_ 2566867694 CwWorkTime 3;
BA_ "GenSigTimeoutTime_PCM" SG_ 2566867694 CwWorkTime 300000;
BA_ "SigType" SG_ 2566867694 CwWorkTime 1;
BA_ "CI_ParId" SG_ 2566867694 CurDayWorkTime "V093";
BA_ "CI_SigId" SG_ 2566867694 CurDayWorkTime 1774;
BA_ "CI_SigName" SG_ 2566867694 CurDayWorkTime "Current daily working time";
BA_ "GenSigSendType" SG_ 2566867694 CurDayWorkTime 3;
BA_ "GenSigTimeoutTime_PCM" SG_ 2566867694 CurDayWorkTime 300000;
BA_ "SigType" SG_ 2566867694 CurDayWorkTime 1;
BA_ "CI_ParId" SG_ 2566867694 LwAssignReducWeekRestPer "V092";
BA_ "CI_SigId" SG_ 2566867694 LwAssignReducWeekRestPer 1773;
BA_ "CI_SigName" SG_ 2566867694 LwAssignReducWeekRestPer "Last Week - Assigned reduced weekly rest periods";
BA_ "GenSigSendType" SG_ 2566867694 LwAssignReducWeekRestPer 3;
BA_ "GenSigTimeoutTime_PCM" SG_ 2566867694 LwAssignReducWeekRestPer 300000;
BA_ "CI_ParId" SG_ 2566867694 LwAssignRegWeekRestPer "V091";
BA_ "CI_SigId" SG_ 2566867694 LwAssignRegWeekRestPer 1772;
BA_ "CI_SigName" SG_ 2566867694 LwAssignRegWeekRestPer "Last Week - Assigned regular weekly rest periods";
BA_ "GenSigSendType" SG_ 2566867694 LwAssignRegWeekRestPer 3;
BA_ "GenSigTimeoutTime_PCM" SG_ 2566867694 LwAssignRegWeekRestPer 300000;
BA_ "CI_ParId" SG_ 2566867694 CwNumOfAssignReducWeekRestPer "V089";
BA_ "CI_SigId" SG_ 2566867694 CwNumOfAssignReducWeekRestPer 1771;
BA_ "CI_SigName" SG_ 2566867694 CwNumOfAssignReducWeekRestPer "Current Week - Number of assigned reduced weekly rest periods";
BA_ "GenSigSendType" SG_ 2566867694 CwNumOfAssignReducWeekRestPer 3;
BA_ "GenSigTimeoutTime_PCM" SG_ 2566867694 CwNumOfAssignReducWeekRestPer 300000;
BA_ "CI_ParId" SG_ 2566867694 CwNumOfAssignRegWeekRestPer "V088";
BA_ "CI_SigId" SG_ 2566867694 CwNumOfAssignRegWeekRestPer 1770;
BA_ "CI_SigName" SG_ 2566867694 CwNumOfAssignRegWeekRestPer "Current Week - Number of assigned regular weekly rest periods";
BA_ "GenSigSendType" SG_ 2566867694 CwNumOfAssignRegWeekRestPer 3;
BA_ "GenSigTimeoutTime_PCM" SG_ 2566867694 CwNumOfAssignRegWeekRestPer 300000;
BA_ "CI_ParId" SG_ 2566867694 DurOfCurRestPer "V086";
BA_ "CI_SigId" SG_ 2566867694 DurOfCurRestPer 1769;
BA_ "CI_SigName" SG_ 2566867694 DurOfCurRestPer "Duration of current rest period";
BA_ "GenSigSendType" SG_ 2566867694 DurOfCurRestPer 3;
BA_ "GenSigTimeoutTime_PCM" SG_ 2566867694 DurOfCurRestPer 300000;
BA_ "SigType" SG_ 2566867694 DurOfCurRestPer 1;
BA_ "CI_ParId" SG_ 2566867694 DurOfCurRest "V085";
BA_ "CI_SigId" SG_ 2566867694 DurOfCurRest 1768;
BA_ "CI_SigName" SG_ 2566867694 DurOfCurRest "Duration of current rest";
BA_ "GenSigSendType" SG_ 2566867694 DurOfCurRest 3;
BA_ "GenSigTimeoutTime_PCM" SG_ 2566867694 DurOfCurRest 300000;
BA_ "SigType" SG_ 2566867694 DurOfCurRest 1;
BA_ "CI_ParId" SG_ 2566867694 CumulBreakTime "V084";
BA_ "CI_SigId" SG_ 2566867694 CumulBreakTime 1767;
BA_ "CI_SigName" SG_ 2566867694 CumulBreakTime "Cumulative break time";
BA_ "GenSigSendType" SG_ 2566867694 CumulBreakTime 3;
BA_ "GenSigTimeoutTime_PCM" SG_ 2566867694 CumulBreakTime 300000;
BA_ "SigType" SG_ 2566867694 CumulBreakTime 1;
BA_ "CI_ParId" SG_ 2566867694 WeekDrivTime "V083";
BA_ "CI_SigId" SG_ 2566867694 WeekDrivTime 1766;
BA_ "CI_SigName" SG_ 2566867694 WeekDrivTime "Weekly driving time";
BA_ "GenSigSendType" SG_ 2566867694 WeekDrivTime 3;
BA_ "GenSigTimeoutTime_PCM" SG_ 2566867694 WeekDrivTime 300000;
BA_ "SigType" SG_ 2566867694 WeekDrivTime 1;
BA_ "CI_ParId" SG_ 2566867694 TwoWeeksDrivTime "V082";
BA_ "CI_SigId" SG_ 2566867694 TwoWeeksDrivTime 1765;
BA_ "CI_SigName" SG_ 2566867694 TwoWeeksDrivTime "Two weeks driving time";
BA_ "GenSigSendType" SG_ 2566867694 TwoWeeksDrivTime 3;
BA_ "GenSigTimeoutTime_PCM" SG_ 2566867694 TwoWeeksDrivTime 300000;
BA_ "SigType" SG_ 2566867694 TwoWeeksDrivTime 1;
BA_ "CI_ParId" SG_ 2566867694 DayDrivTime_FF4AEE "V081";
BA_ "CI_SigId" SG_ 2566867694 DayDrivTime_FF4AEE 1764;
BA_ "CI_SigName" SG_ 2566867694 DayDrivTime_FF4AEE "Daily driving time";
BA_ "GenSigSendType" SG_ 2566867694 DayDrivTime_FF4AEE 3;
BA_ "GenSigTimeoutTime_PCM" SG_ 2566867694 DayDrivTime_FF4AEE 300000;
BA_ "SigType" SG_ 2566867694 DayDrivTime_FF4AEE 1;
BA_ "CI_ParId" SG_ 2566867694 ContDrivTime "V080";
BA_ "CI_SigId" SG_ 2566867694 ContDrivTime 1763;
BA_ "CI_SigName" SG_ 2566867694 ContDrivTime "Continuous driving time";
BA_ "GenSigSendType" SG_ 2566867694 ContDrivTime 3;
BA_ "GenSigTimeoutTime_PCM" SG_ 2566867694 ContDrivTime 300000;
BA_ "SigType" SG_ 2566867694 ContDrivTime 1;
BA_ "CI_ParId" SG_ 2583645991 EmActPwrKw "ID1796";
BA_ "CI_SigId" SG_ 2583645991 EmActPwrKw 39400;
BA_ "CI_SigName" SG_ 2583645991 EmActPwrKw "EM_Actual_Power_kW";
BA_ "GenSigTimeoutTime_PCM" SG_ 2583645991 EmActPwrKw 1250;
BA_ "SigType" SG_ 2583645991 EmActPwrKw 1;
BA_ "CI_ParId" SG_ 2583645991 BatActPwrKw "ID1795";
BA_ "CI_SigId" SG_ 2583645991 BatActPwrKw 39399;
BA_ "CI_SigName" SG_ 2583645991 BatActPwrKw "Battery_Actual_Power_kW";
BA_ "GenSigTimeoutTime_PCM" SG_ 2583645991 BatActPwrKw 1250;
BA_ "SigType" SG_ 2583645991 BatActPwrKw 2;
BA_ "CI_ParId" SG_ 2566913319 VacuumPumpActv "ID1503";
BA_ "CI_SigId" SG_ 2566913319 VacuumPumpActv 3690;
BA_ "CI_SigName" SG_ 2566913319 VacuumPumpActv "Vacuum Pump Activation";
BA_ "GenSigTimeoutTime_PCM" SG_ 2566913319 VacuumPumpActv 2500;
BA_ "SigType" SG_ 2566913319 VacuumPumpActv 4;
BA_ "CI_ParId" SG_ 2566913319 TimeToEndChgPhase "ID1500";
BA_ "CI_SigId" SG_ 2566913319 TimeToEndChgPhase 3689;
BA_ "CI_SigName" SG_ 2566913319 TimeToEndChgPhase "Time To End Charging Phase";
BA_ "GenSigTimeoutTime_PCM" SG_ 2566913319 TimeToEndChgPhase 2500;
BA_ "CI_ParId" SG_ 2566913319 GridChgPwr "ID1502";
BA_ "CI_SigId" SG_ 2566913319 GridChgPwr 3688;
BA_ "CI_SigName" SG_ 2566913319 GridChgPwr "Grid Charging Power";
BA_ "GenSigTimeoutTime_PCM" SG_ 2566913319 GridChgPwr 2500;
BA_ "CI_ParId" SG_ 2566913319 VehPluggedSts "ID1499";
BA_ "CI_SigId" SG_ 2566913319 VehPluggedSts 3687;
BA_ "CI_SigName" SG_ 2566913319 VehPluggedSts "Vehicle Plugged Status";
BA_ "GenSigTimeoutTime_PCM" SG_ 2566913319 VehPluggedSts 2500;
BA_ "SigType" SG_ 2566913319 VehPluggedSts 4;
BA_ "CI_ParId" SG_ 2566913319 ChgOpMode "ID1498";
BA_ "CI_SigId" SG_ 2566913319 ChgOpMode 3686;
BA_ "CI_SigName" SG_ 2566913319 ChgOpMode "Charging Operation Mode";
BA_ "GenSigTimeoutTime_PCM" SG_ 2566913319 ChgOpMode 2500;
BA_ "CI_ParId" SG_ 2566913319 ElPwtTract "ID1497";
BA_ "CI_SigId" SG_ 2566913319 ElPwtTract 3685;
BA_ "CI_SigName" SG_ 2566913319 ElPwtTract "Electrical Powertrain Traction";
BA_ "GenSigTimeoutTime_PCM" SG_ 2566913319 ElPwtTract 2500;
BA_ "SigType" SG_ 2566913319 ElPwtTract 4;
BA_ "CI_ParId" SG_ 2566913319 ReqHazardLight "ID1492";
BA_ "CI_SigId" SG_ 2566913319 ReqHazardLight 3683;
BA_ "CI_SigName" SG_ 2566913319 ReqHazardLight "Requesting Hazard Light";
BA_ "GenSigTimeoutTime_PCM" SG_ 2566913319 ReqHazardLight 2500;
BA_ "SigType" SG_ 2566913319 ReqHazardLight 4;
BA_ "CI_ParId" SG_ 2566913319 HvacEnaFunct "ID1491";
BA_ "CI_SigId" SG_ 2566913319 HvacEnaFunct 3682;
BA_ "CI_SigName" SG_ 2566913319 HvacEnaFunct "HVAC Enable Function";
BA_ "GenSigTimeoutTime_PCM" SG_ 2566913319 HvacEnaFunct 2500;
BA_ "SigType" SG_ 2566913319 HvacEnaFunct 4;
BA_ "CI_ParId" SG_ 2566913319 ScheddRechargeSts "ID2122";
BA_ "CI_SigId" SG_ 2566913319 ScheddRechargeSts 41668;
BA_ "CI_SigName" SG_ 2566913319 ScheddRechargeSts "Scheduled Recharge Status";
BA_ "GenSigTimeoutTime_PCM" SG_ 2566913319 ScheddRechargeSts 2500;
BA_ "SigType" SG_ 2566913319 ScheddRechargeSts 4;
BA_ "CI_ParId" SG_ 2566913319 ChgSts_FFFD27 "ID2121";
BA_ "CI_SigId" SG_ 2566913319 ChgSts_FFFD27 41667;
BA_ "CI_SigName" SG_ 2566913319 ChgSts_FFFD27 "Charging Status ";
BA_ "GenSigTimeoutTime_PCM" SG_ 2566913319 ChgSts_FFFD27 2500;
BA_ "SigType" SG_ 2566913319 ChgSts_FFFD27 4;
BA_ "CI_ParId" SG_ 2566913319 ChgPortSts "ID2120";
BA_ "CI_SigId" SG_ 2566913319 ChgPortSts 41658;
BA_ "CI_SigName" SG_ 2566913319 ChgPortSts "Charging Port Status";
BA_ "GenSigTimeoutTime_PCM" SG_ 2566913319 ChgPortSts 2500;
BA_ "SigType" SG_ 2566913319 ChgPortSts 4;
BA_ "CI_ParId" SG_ 2566913319 RegenBrkBlk "ID1545";
BA_ "CI_SigId" SG_ 2566913319 RegenBrkBlk 3681;
BA_ "CI_SigName" SG_ 2566913319 RegenBrkBlk "Regenerative Braking Blocked";
BA_ "GenSigTimeoutTime_PCM" SG_ 2566913319 RegenBrkBlk 2500;
BA_ "SigType" SG_ 2566913319 RegenBrkBlk 4;
BA_ "CI_ParId" SG_ 2566913319 RegenBrkModeActv "ID1489";
BA_ "CI_SigId" SG_ 2566913319 RegenBrkModeActv 3680;
BA_ "CI_SigName" SG_ 2566913319 RegenBrkModeActv "Regenerative Brake Mode Active";
BA_ "GenSigTimeoutTime_PCM" SG_ 2566913319 RegenBrkModeActv 2500;
BA_ "CI_ParId" SG_ 2566913319 ReqRegenBrkLight "ID1482";
BA_ "CI_SigId" SG_ 2566913319 ReqRegenBrkLight 3679;
BA_ "CI_SigName" SG_ 2566913319 ReqRegenBrkLight "Requesting Regenerative Brake Light";
BA_ "GenSigTimeoutTime_PCM" SG_ 2566913319 ReqRegenBrkLight 2500;
BA_ "SigType" SG_ 2566913319 ReqRegenBrkLight 4;
BA_ "CI_ParId" SG_ 2566913319 ElMotTractMode "ID1481";
BA_ "CI_SigId" SG_ 2566913319 ElMotTractMode 3678;
BA_ "CI_SigName" SG_ 2566913319 ElMotTractMode "Electric Motor Traction Mode";
BA_ "GenSigTimeoutTime_PCM" SG_ 2566913319 ElMotTractMode 2500;
VAL_ 2566908199 ExtElLoadPrioFdbk 0 "Active" 1 "Not Active" 2 "Error" 3 "Not Available" ;
VAL_ 2566908199 TractModeInhFdbk 0 "No Inhibition" 1 "Inhibition Active, Driver No Req" 2 "Inhibition Active, Driver Req" 3 "Res" 4 "Res" 5 "Res" 6 "Error" 7 "Not Available" ;
VAL_ 2566908199 ExtRegenBrkModeReqFdbk 0 "OK" 1 "NOK" 2 "Error" 3 "Not Available" ;
VAL_ 2566908199 ExtTractReqFdbk 0 "OK" 1 "NOK" 2 "Error" 3 "Not Available" ;
VAL_ 2566908199 ExtHvacReqFdbk 0 "OK" 1 "NOK" 2 "Error" 3 "Not Available" ;
VAL_ 2566908234 BatChgDurTime 0 "No Action" 1 "Start Charging" 2 "Suspending Charging" 3 "Resume Charging" 4 "Stop Charging" 6 "Error" 7 "Not Available" ;
VAL_ 2566908234 ExtBatChgReq 0 "Inactive" 1 "Active" 2 "Error" 3 "Not Available" ;
VAL_ 2566908234 FmsRegenBrkModeReq 0 "Regenerative" 1 "One Pedal Drive" 2 "Coasting" 3 "No Selection" 4 "Reserved" 5 "Reserved" 6 "Error" 7 "Not Available" ;
VAL_ 2566908234 FmsExtTractModeReq 0 "Normal" 1 "Eco" 2 "Performance" 3 "No Selection" 4 "Power Inhibit" 5 "Reserved" 6 "Error" 7 "Not Available" ;
VAL_ 2566908234 FmsHvacWorkMode 0 "Normal" 1 "Eco" 2 "Error" 3 "Not Available / No Action" ;
VAL_ 2566908234 ExtHvacReq 0 "Off" 1 "On Grid Only" 2 "On without Grid" 5 "Error" 7 "Not Available" ;
VAL_ 2583664714 PosLightCtrl 0 "Off" 1 "On" 2 "Error" 3 "Not Available" ;
VAL_ 2583664714 LowBeamLightCtrl 0 "Off" 1 "On" 2 "Error" 3 "Not Available" ;
VAL_ 2583664714 RearCeilLight_FF984A 0 "Off" 1 "On" 2 "Error" 3 "Not Available" ;
VAL_ 2583664714 CentCeilLight_FF984A 0 "Off" 1 "On" 2 "Error" 3 "Not Available" ;
VAL_ 2583664714 LatRightCeilLight_FF984A 0 "Off" 1 "On" 2 "Error" 3 "Not Available" ;
VAL_ 2583664714 LatLeftCeilLight_FF984A 0 "Off" 1 "On" 2 "Error" 3 "Not Available" ;
VAL_ 2583664714 FrontCeilLight_FF984A 0 "Off" 1 "On" 2 "Error" 3 "Not Available" ;
VAL_ 2583664714 EcoMode_FF984A 0 "Disable" 1 "Enable" 2 "Error" 3 "Not Available" ;
VAL_ 2583664714 EcoHiMatic 0 "Disable" 1 "Enable" 2 "Error" 3 "Not Available" ;
VAL_ 2566896409 EacPwrLim 255 "Not Available" ;
VAL_ 2566896409 EacCtrlMode 0 "Off" 1 "On" 2 "Reserved" 3 "Not Available / Do not change" ;
VAL_ 2566896409 EacSpeed 255 "Not Available" ;
VAL_ 2566897046 EacPhaseCur 255 "Not Available" ;
VAL_ 2566897046 EacInvTemp 255 "Not Available" ;
VAL_ 2566897046 EacInCur 255 "Not Available" ;
VAL_ 2566897046 EacInV 254 "Error" 255 "Not Available" ;
VAL_ 2566897046 EacSts 0 "Off" 1 "On" 2 "Limit" 3 "Pre-heating" 4 "Reserved" 5 "Reserved" 6 "Init" 7 "Not Available / Error" ;
VAL_ 2566897046 EacSpeed_FFBD96 255 "Not Available" ;
VAL_ 2566886218 EcallSts 0 "No actions (default)" 1 "Manual emergency call" 2 "Automatic emergency call" 6 "Error" 7 "Not Available" ;
VAL_ 2566886227 SrsCfg 0 "Airbag Only" 1 "FIS Only" 2 "Full Config" 3 "Not Available" ;
VAL_ 2566886227 AirbagFail 0 "Off, no Fault" 1 "No Fault, Lamp Flashing" 2 "Fault Present, Lamp On" 3 "Not Available" ;
VAL_ 2566886227 AllAirbagsSts 0 "On/No Lamp" 1 "Off/Yellow Lamp On" 2 "Error/Red Lamp On" 3 "Not Available" ;
VAL_ 2566886227 PassAirbagSts 0 "On/No Lamp" 1 "Off/Yellow Lamp On" 2 "Error/Red Lamp On" 3 "Not Available" ;
VAL_ 2566886227 CrashOutSts_FF9353 0 "No crash" 1 "Front Pretensioner" 2 "Front First Level" 4 "Front Second Level" 8 "Right Hand Side" 16 "Left Hand Side" 32 "Rear" 64 "Rollover" 128 "Pedestrian" ;
VAL_ 2566886227 FuelCutoffInd 0 "Not Active" 1 "Active" 2 "Error" 3 "Not Available" ;
VAL_ 2583669789 SevAnomalyInBlk2 0 "No" 1 "Yes" 2 "Error" 3 "Not Available" ;
VAL_ 2583669789 SevAnomalyInBlk1 0 "No" 1 "Yes" 2 "Error" 3 "Not Available" ;
VAL_ 2583669789 Blk2Full 0 "No" 1 "Yes" 2 "Error" 3 "Not Available" ;
VAL_ 2583669789 Blk1Full 0 "No" 1 "Yes" 2 "Error" 3 "Not Available" ;
VAL_ 2583669834 WarnRx 0 "No" 1 "Yes" 2 "Error" 3 "Not Available" ;
VAL_ 2650775319 MaxChgCurLim 0 "8A" 1 "16A" 2 "32A" 3 "Not Used" 4 "Not Used" 5 "Not Used" 6 "Error" 7 "Not available" ;
VAL_ 2650775319 DseNotificationSet 0 "Notification Disable" 1 "Notification Enable" 2 "Error" 3 "Not Available" ;
VAL_ 2650775319 EptoMenuWaitingMode 0 "Disable" 1 "Enable" 2 "Error" 3 "Not Available" ;
VAL_ 2650775319 ChgPlugLck_UnlckAtEndOfChg 0 "Stay Locked (Plugged)" 1 "Unlock" 2 "Error" 3 "Not Available" ;
VAL_ 2650775319 MaxSocForEndOfChg 254 "Error" 255 "Not Available" ;
VAL_ 2650775319 MinSocUtilitiesDisconn 254 "Error" 255 "Not Available" ;
VAL_ 2650775319 ElLoadPrioPc 254 "Error" 255 "Not Available" ;
VAL_ 2650775335 ElLoadPrioPc_FF9F27 254 "Error" 255 "Not Available" ;
VAL_ 2650775370 ZZS_24_1DFF9F4A 0 "Stay Locked (Plugged)" 1 "Unlock" 2 "Error" 3 "Not Available" ;
VAL_ 2650775370 ElLoadPrioPc_FF9F4A 254 "Error" 255 "Not Available" ;
VAL_ 2583678231 EngStartStopMenuSet 0 "Off" 1 "On" 2 "Error" 3 "Not Available" ;
VAL_ 2583678231 MenuAutoLckTimer2 0 ": Autolocking Disabled" 254 ": Error (if necessary)" 255 ": Not Available (IC menu Absent)" ;
VAL_ 2583678231 MenuAutoLckTimer1 0 ": Autolocking Disabled" 254 ": Error (if necessary)" 255 ": Not Available (IC menu Absent)" ;
VAL_ 2583678231 MenuSelDistReq 0 "Near" 1 "Middle" 2 "Far" 3 "Menu off" 4 "Reserved" 6 "Error" 7 "Not Available / No Action" ;
VAL_ 2583678231 MenuWelcomeLightReq 0 "Off" 1 "On" 2 "Error" 3 "Not available" ;
VAL_ 2583678231 MenuKeylessEntry 0 "Off" 1 "On" 2 "Error" 3 "Not available" ;
VAL_ 2583678231 MenuSelUnlckSound 0 "Off" 1 "On" 2 "Error" 3 "Not available" ;
VAL_ 2583678231 MenuSelLckSound 0 "Off" 1 "On" 2 "Error" 3 "Not available" ;
VAL_ 2583678231 MenuSelUnlckMode 0 "Single" 1 "Centralized" 2 "Error" 3 "Not available" ;
VAL_ 2583678241 IgnShutdnTimer 255 "Not Available" ;
VAL_ 2583654525 TboxSts 0 "Status OK" 1 "Status Not OK" 2 "Error" 3 "Not Available" ;
VAL_ 2566898670 WFact 0 "Not used" ;
VAL_ 2566898670 NextCalDateMonth 0 "Not used" ;
VAL_ 2566898670 NextCalDateDay 0 "Not used" ;
VAL_ 2566898926 PrintDrawSts 0 "Open" 1 "Closed" 2 "Error" 3 "Not Available" ;
VAL_ 2566898926 EndOfLifeDriv1CardAlert 0 "No Alert" 1 "Alert Active" 2 "Error" 3 "Not Available" ;
VAL_ 2566898926 Driv1CardDwlAlert 0 "No Alert" 1 "Alert Active" 2 "Error" 3 "Not Available" ;
VAL_ 2566899694 DayRestPer7Flag 0 "No Unknown activities" 1 "At least 1 Unknown act period" ;
VAL_ 2566899694 DayRestPer7 32766 "Error" 32767 "Not Available" ;
VAL_ 2566899694 DayRestPer6Flag 0 "No Unknown activities" 1 "At least 1 Unknown act period" ;
VAL_ 2566899694 DayRestPer6 32766 "Error" 32767 "Not Available" ;
VAL_ 2566899694 DayRestPer5Flag 0 "No Unknown activities" 1 "At least 1 Unknown act period" ;
VAL_ 2566899694 DayRestPer5 32766 "Error" 32767 "Not Available" ;
VAL_ 2566899694 DayRestPer4Flag 0 "No Unknown activities" 1 "At least 1 Unknown act period" ;
VAL_ 2566899694 DayRestPer4 32766 "Error" 32767 "Not Available" ;
VAL_ 2566899694 DayRestPer3Flag 0 "No Unknown activities" 1 "At least 1 Unknown act period" ;
VAL_ 2566899694 DayRestPer3 32766 "Error" 32767 "Not Available" ;
VAL_ 2566899694 DayRestPer2Flag 0 "No Unknown activities" 1 "At least 1 Unknown act period" ;
VAL_ 2566899694 DayRestPer2 32766 "Error" 32767 "Not Available" ;
VAL_ 2566899694 DayRestPer1Flag 0 "No Unknown activities" 1 "At least 1 Unknown act period" ;
VAL_ 2566899694 DayRestPer1 32766 "Error" 32767 "Not Available" ;
VAL_ 2566899694 DayDrivTimeShift6Flag 0 "No resting period" 1 "At least one resting period" ;
VAL_ 2566899694 DayDrivTimeShift6 32766 "Error" 32767 "Not Available" ;
VAL_ 2566899694 DayDrivTimeShift5Flag 0 "No resting period" 1 "At least one resting period" ;
VAL_ 2566899694 DayDrivTimeShift5 32766 "Error" 32767 "Not Available" ;
VAL_ 2566899694 DayDrivTimeShift4Flag 0 "No resting period" 1 "At least one resting period" ;
VAL_ 2566899694 DayDrivTimeShift4 32766 "Error" 32767 "Not Available" ;
VAL_ 2566899694 DayDrivTimeShift3Flag 0 "No resting period" 1 "At least one resting period" ;
VAL_ 2566899694 DayDrivTimeShift3 32766 "Error" 32767 "Not Available" ;
VAL_ 2566899694 DayDrivTimeShift2Flag 0 "No resting period" 1 "At least one resting period" ;
VAL_ 2566899694 DayDrivTimeShift2 32766 "Error" 32767 "Not Available" ;
VAL_ 2566899694 DayDrivTimeShift1Flag 0 "No resting period" 1 "At least one resting period" ;
VAL_ 2566899694 DayDrivTimeShift1 32766 "Error" 32767 "Not Available" ;
VAL_ 2566899694 DayDrivTimeFlag 0 "No resting period" 1 "At least one resting period" ;
VAL_ 2566899694 DayDrivTime 32766 "Error" 32767 "Not Available" ;
VAL_ 2650768384 T15_st 0 "Off" 1 "On" ;
VAL_ 2650768384 Rail_stMon 0 "OFF" 1 "MeUn" 2 "PCV" 3 "CPC" 4 "Wait_MeUn" 5 "Wait_PCV" 255 "RAIL_UNUSED" ;
VAL_ 2583636764 TsrDualCarriageWaySLStart 0 "Suspended" 1 "5km/h [mph]" 2 "7km/h [mph]" 3 "10km/h [mph]" 4 "15km/h [mph]" 5 "20km/h [mph]" 6 "25km/h [mph]" 7 "30km/h [mph]" 8 "35km/h [mph]" 9 "40km/h [mph]" 10 "45km/h [mph]" 11 "50km/h [mph]" 12 "55km/h [mph]" 13 "60km/h [mph]" 14 "65km/h [mph]" 15 "70km/h [mph]" 16 "75km/h [mph]" 17 "80km/h [mph]" 18 "85km/h [mph]" 19 "90km/h [mph]" 20 "95km/h [mph]" 21 "100km/h [mph]" 22 "105km/h [mph]" 23 "110km/h [mph]" 24 "115km/h [mph]" 25 "120km/h [mph]" 26 "130km/h [mph]" 27 "140km/h [mph]" 28 "150km/h [mph]" 29 "160km/h [mph]" 30 "Unlimited km/h [mph]" 31 "Not Available km/h [mph]" ;
VAL_ 2583636764 TsrSingleCarriageWaySLStart 0 "Suspended" 1 "5km/h [mph]" 2 "7km/h [mph]" 3 "10km/h [mph]" 4 "15km/h [mph]" 5 "20km/h [mph]" 6 "25km/h [mph]" 7 "30km/h [mph]" 8 "35km/h [mph]" 9 "40km/h [mph]" 10 "45km/h [mph]" 11 "50km/h [mph]" 12 "55km/h [mph]" 13 "60km/h [mph]" 14 "65km/h [mph]" 15 "70km/h [mph]" 16 "75km/h [mph]" 17 "80km/h [mph]" 18 "85km/h [mph]" 19 "90km/h [mph]" 20 "95km/h [mph]" 21 "100km/h [mph]" 22 "105km/h [mph]" 23 "110km/h [mph]" 24 "115km/h [mph]" 25 "120km/h [mph]" 26 "130km/h [mph]" 27 "140km/h [mph]" 28 "150km/h [mph]" 29 "160km/h [mph]" 30 "Unlimited km/h [mph]" 31 "Not Available km/h [mph]" ;
VAL_ 2583636764 TsrPlaystreetResidentialSLStart 0 "Suspended" 1 "5km/h [mph]" 2 "7km/h [mph]" 3 "10km/h [mph]" 4 "15km/h [mph]" 5 "20km/h [mph]" 6 "25km/h [mph]" 7 "30km/h [mph]" 8 "35km/h [mph]" 9 "40km/h [mph]" 10 "45km/h [mph]" 11 "50km/h [mph]" 12 "55km/h [mph]" 13 "60km/h [mph]" 14 "65km/h [mph]" 15 "70km/h [mph]" 16 "75km/h [mph]" 17 "80km/h [mph]" 18 "85km/h [mph]" 19 "90km/h [mph]" 20 "95km/h [mph]" 21 "100km/h [mph]" 22 "105km/h [mph]" 23 "110km/h [mph]" 24 "115km/h [mph]" 25 "120km/h [mph]" 26 "130km/h [mph]" 27 "140km/h [mph]" 28 "150km/h [mph]" 29 "160km/h [mph]" 30 "Unlimited km/h [mph]" 31 "Not Available km/h [mph]" ;
VAL_ 2583636764 TsrCityBuildUpSLStart 0 "Suspended" 1 "5km/h [mph]" 2 "7km/h [mph]" 3 "10km/h [mph]" 4 "15km/h [mph]" 5 "20km/h [mph]" 6 "25km/h [mph]" 7 "30km/h [mph]" 8 "35km/h [mph]" 9 "40km/h [mph]" 10 "45km/h [mph]" 11 "50km/h [mph]" 12 "55km/h [mph]" 13 "60km/h [mph]" 14 "65km/h [mph]" 15 "70km/h [mph]" 16 "75km/h [mph]" 17 "80km/h [mph]" 18 "85km/h [mph]" 19 "90km/h [mph]" 20 "95km/h [mph]" 21 "100km/h [mph]" 22 "105km/h [mph]" 23 "110km/h [mph]" 24 "115km/h [mph]" 25 "120km/h [mph]" 26 "130km/h [mph]" 27 "140km/h [mph]" 28 "150km/h [mph]" 29 "160km/h [mph]" 30 "Unlimited km/h [mph]" 31 "Not Available km/h [mph]" ;
VAL_ 2583636764 TsrMotwaySLStart 0 "Suspended" 1 "5km/h [mph]" 2 "7km/h [mph]" 3 "10km/h [mph]" 4 "15km/h [mph]" 5 "20km/h [mph]" 6 "25km/h [mph]" 7 "30km/h [mph]" 8 "35km/h [mph]" 9 "40km/h [mph]" 10 "45km/h [mph]" 11 "50km/h [mph]" 12 "55km/h [mph]" 13 "60km/h [mph]" 14 "65km/h [mph]" 15 "70km/h [mph]" 16 "75km/h [mph]" 17 "80km/h [mph]" 18 "85km/h [mph]" 19 "90km/h [mph]" 20 "95km/h [mph]" 21 "100km/h [mph]" 22 "105km/h [mph]" 23 "110km/h [mph]" 24 "115km/h [mph]" 25 "120km/h [mph]" 26 "130km/h [mph]" 27 "140km/h [mph]" 28 "150km/h [mph]" 29 "160km/h [mph]" 30 "Unlimited km/h [mph]" 31 "Not Available km/h [mph]" ;
VAL_ 2566909770 VmuWakeUp 0 "Off, No Request" 1 "On, WuP Request" 2 "Error" 3 "Not Available" ;
VAL_ 2566867182 SignifTimeOverlapInUsedDrivActiv 0 "no significant time overlaps" 1 "significant time overlap" 2 "Error indicator" 3 "Not Available" ;
VAL_ 2566867182 MultiManningCurShift 0 "Single driver for current shift" 1 "Multi-manning for current shift" 2 "Error indicator" 3 "Not Available" ;
VAL_ 2566867182 WeekRestPerCalcEna 0 "Disabled" 1 "Enabled" 2 "Error indicator" 3 "Not Available" ;
VAL_ 2566867182 NoSuffDataOnTheDrivCard 0 "Sufficient data" 1 "No sufficient data" 2 "Error indicator" 3 "Not Available" ;
VAL_ 2566867182 UnknownPer 0 "No UNKNOWN periods" 1 "At least one UNKNOWN period" 2 "Error indicator" 3 "Not Available or not installed" ;
VAL_ 2566867182 RemReducDayRestPer 4 "Reserved" 5 "Reserved" 6 "Error indicator" 7 "Not Available" ;
VAL_ 2566867182 Rem10HDrivTimes 3 "Reserved" 4 "Reserved" 5 "Reserved" 6 "Error indicator" 7 "Not Available" ;
VAL_ 2566867694 LwAssignReducWeekRestPer 14 "Error indicator" 15 "Not Available" ;
VAL_ 2566867694 LwAssignRegWeekRestPer 14 "Error indicator" 15 "Not Available" ;
VAL_ 2566867694 CwNumOfAssignReducWeekRestPer 14 "Error indicator" 15 "Not Available" ;
VAL_ 2566867694 CwNumOfAssignRegWeekRestPer 14 "Error indicator" 15 "Not Available" ;
VAL_ 2583645991 EmActPwrKw 65534 "Error" 65535 "Not Available" ;
VAL_ 2583645991 BatActPwrKw 65534 "Error" 65535 "Not Available" ;
VAL_ 2566913319 VacuumPumpActv 0 "Off" 1 "On" 2 "Error" 3 "Not Available/Take no action" ;
VAL_ 2566913319 TimeToEndChgPhase 62 "Error" 63 "Not Available" ;
VAL_ 2566913319 VehPluggedSts 0 "Off" 1 "On" 2 "Reserved" 3 "Not Available/Take no action" ;
VAL_ 2566913319 ChgOpMode 0 "Mode Off" 1 "Mode 2" 2 "Mode 3" 3 "Mode 4" 6 "Error" 7 "Not Available" ;
VAL_ 2566913319 ElPwtTract 0 "Enabled" 1 "Disabled" 2 "Error" 3 "Not Available" ;
VAL_ 2566913319 ReqHazardLight 0 "Off" 1 "On" 2 "Reserved" 3 "Not Available/Take no action" ;
VAL_ 2566913319 HvacEnaFunct 0 "Disabled" 1 "Enabled" 2 "Error" 3 "Not Available" ;
VAL_ 2566913319 ScheddRechargeSts 0 "Charging Scheduled" 1 "Charging Not Scheduled" 2 "Error" 3 "Not Available" ;
VAL_ 2566913319 ChgSts_FFFD27 0 "On" 1 "Off" 2 "Error" 3 "Not Available" ;
VAL_ 2566913319 ChgPortSts 0 "Closed" 1 "Opened" 2 "Error" 3 "Not Available" ;
VAL_ 2566913319 RegenBrkBlk 0 "Inactive" 1 "Active" 2 "Error" 3 "Not Available" ;
VAL_ 2566913319 RegenBrkModeActv 0 "Regenerative" 1 "One Pedal Drive" 2 "Coasting" 3 "Fixed Regenerative" 4 "Fixed One Pedal Drive" 5 "Fixed Coasting" 6 "Error" 7 "Not Available" ;
VAL_ 2566913319 ReqRegenBrkLight 0 "Off" 1 "On" 2 "Reserved" 3 "Not Available/Take no action" ;
VAL_ 2566913319 ElMotTractMode 0 "Normal" 1 "Eco" 2 "Performance" 3 "Fixed Normal" 4 "Fixed Eco" 5 "Fixed Performance" 6 "Error" 7 "Not Available" ;
